VERSION "created by canmatrix"

NS_ :

BS_:

BU_: RadarFrontCenter DASy MPC3

BO_ 3221225472 VECTOR__INDEPENDENT_SIG_MSG: 0 Vector__XXX
 SG_ New_Signal_4448 : 0|8@1+ (1,0) [0|0] "" Vector__XXX

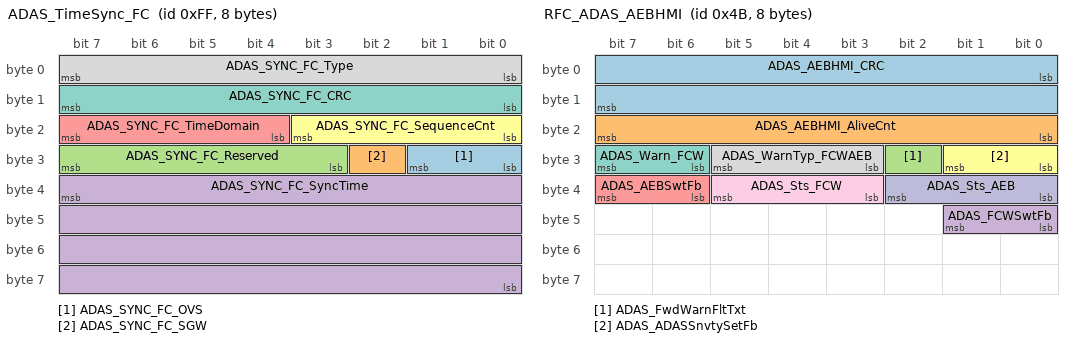
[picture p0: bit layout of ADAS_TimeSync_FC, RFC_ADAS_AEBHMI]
BO_ 255 ADAS_TimeSync_FC: 8 DASy
 SG_ ADAS_SYNC_FC_OVS : 24|2@1+ (1,0) [0|3] ""  MPC3,RadarFrontCenter
 SG_ ADAS_SYNC_FC_SGW : 26|1@1+ (1,0) [0|1] ""  MPC3,RadarFrontCenter
 SG_ ADAS_SYNC_FC_Reserved : 27|5@1+ (1,0) [0|31] ""  MPC3,RadarFrontCenter
 SG_ ADAS_SYNC_FC_SyncTime : 39|32@0+ (1,0) [0|4294967295] ""  MPC3,RadarFrontCenter
 SG_ ADAS_SYNC_FC_TimeDomain : 20|4@1+ (1,0) [0|15] ""  MPC3,RadarFrontCenter
 SG_ ADAS_SYNC_FC_SequenceCnt : 16|4@1+ (1,0) [0|15] ""  MPC3,RadarFrontCenter
 SG_ ADAS_SYNC_FC_CRC : 8|8@1+ (1,0) [0|0] ""  MPC3,RadarFrontCenter
 SG_ ADAS_SYNC_FC_Type : 0|8@1+ (1,0) [0|255] ""  MPC3,RadarFrontCenter

BO_ 75 RFC_ADAS_AEBHMI: 8 RadarFrontCenter
 SG_ ADAS_AEBHMI_CRC : 0|16@1+ (1,0) [0|65535] ""  DASy
 SG_ ADAS_AEBHMI_AliveCnt : 16|8@1+ (1,0) [0|255] ""  DASy
 SG_ ADAS_FwdWarnFltTxt : 26|1@1+ (1,0) [0|1] ""  DASy
 SG_ ADAS_FCWSwtFb : 40|2@1+ (1,0) [0|3] ""  DASy
 SG_ ADAS_AEBSwtFb : 38|2@1+ (1,0) [0|3] ""  DASy
 SG_ ADAS_ADASSnvtySetFb : 24|2@1+ (1,0) [0|3] ""  DASy
 SG_ ADAS_Warn_FCW : 30|2@1+ (1,0) [0|3] ""  DASy
 SG_ ADAS_WarnTyp_FCWAEB : 27|3@1+ (1,0) [0|7] ""  DASy
 SG_ ADAS_Sts_FCW : 35|3@1+ (1,0) [0|7] ""  DASy
 SG_ ADAS_Sts_AEB : 32|3@1+ (1,0) [0|7] ""  DASy

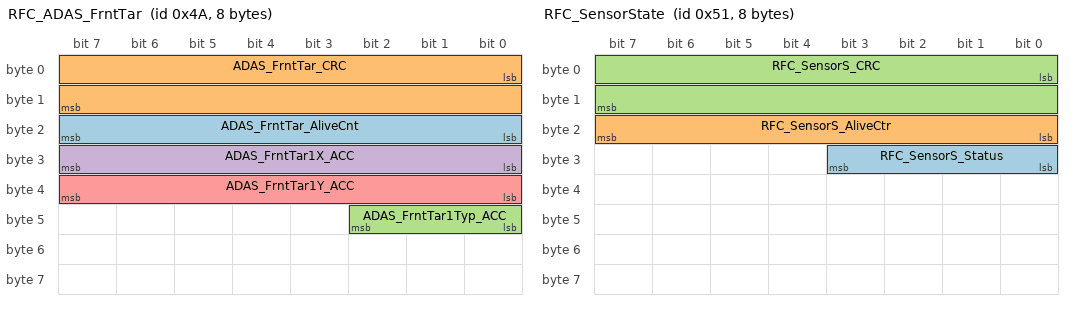
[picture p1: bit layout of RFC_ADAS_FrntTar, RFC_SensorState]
BO_ 74 RFC_ADAS_FrntTar: 8 RadarFrontCenter
 SG_ ADAS_FrntTar_AliveCnt : 16|8@1+ (1,0) [0|255] ""  DASy
 SG_ ADAS_FrntTar_CRC : 0|16@1+ (1,0) [0|65535] ""  DASy
 SG_ ADAS_FrntTar1Typ_ACC : 40|3@1+ (1,0) [0|7] ""  DASy
 SG_ ADAS_FrntTar1X_ACC : 24|8@1+ (1,0) [0|255] ""  DASy
 SG_ ADAS_FrntTar1Y_ACC : 32|8@1+ (0.1,-12.7) [-12.7|12.8] ""  DASy

BO_ 81 RFC_SensorState: 8 RadarFrontCenter
 SG_ RFC_SensorS_Status : 24|4@1+ (1,0) [0|15] ""  DASy
 SG_ RFC_SensorS_AliveCtr : 16|8@1+ (1,0) [0|255] ""  DASy
 SG_ RFC_SensorS_CRC : 0|16@1+ (1,0) [0|65535] ""  DASy

BO_ 2281601536 Dev_Video_SyncVisor_TX: 8 MPC3
 SG_ ImgTimeDelay : 32|32@1+ (1,0) [0|4294967295] ""  RadarFrontCenter,DASy
 SG_ ImgFrameCounter : 0|32@1+ (1,0) [0|4294967295] ""  DASy,RadarFrontCenter

BO_ 931 VFC_MapInfo: 16 MPC3
 SG_ VFC_MapInfo_CountryCode : 118|10@1+ (1,0) [0|1023] ""  RadarFrontCenter,DASy
 SG_ VFC_MapInfo_CurrentLane : 52|3@1+ (1,0) [0|7] ""  RadarFrontCenter,DASy
 SG_ VFC_MapInfo_RoadCurv : 104|12@1+ (2E-005,-0.04094) [-0.04094|0.04096] "1/m"  RadarFrontCenter,DASy
 SG_ VFC_MapInfo_BuildUp_Dx : 88|10@1+ (1,0) [0|1023] "m"  RadarFrontCenter,DASy
 SG_ VFC_MapInfo_BuildUp : 98|2@1+ (1,0) [0|3] ""  RadarFrontCenter,DASy
 SG_ VFC_MapInfo_Bridge_Dx : 72|10@1+ (1,0) [0|1023] "m"  RadarFrontCenter,DASy
 SG_ VFC_MapInfo_Bridge : 82|2@1+ (1,0) [0|3] ""  RadarFrontCenter,DASy
 SG_ VFC_MapInfo_Tunnel : 66|2@1+ (1,0) [0|3] ""  RadarFrontCenter,DASy
 SG_ VFC_MapInfo_Tunnel_Dx : 56|10@1+ (1,0) [0|1023] "m"  RadarFrontCenter,DASy
 SG_ VFC_MapInfo_TollGate : 50|2@1+ (1,0) [0|3] ""  RadarFrontCenter,DASy
 SG_ VFC_MapInfo_TollGate_Dx : 40|10@1+ (1,0) [0|1023] "m"  RadarFrontCenter,DASy
 SG_ VFC_MapInfo_DiRoad_Offset200 : 38|2@1+ (1,0) [0|3] ""  RadarFrontCenter,DASy
 SG_ VFC_MapInfo_LaneNum_Offset200 : 35|3@1+ (1,0) [0|7] ""  RadarFrontCenter,DASy
 SG_ VFC_MapInfo_LaneNum_Offset0 : 32|3@1+ (1,0) [0|7] ""  RadarFrontCenter,DASy
 SG_ VFC_MapInfo_DiRoad_Offset0 : 30|2@1+ (1,0) [0|3] ""  RadarFrontCenter,DASy
 SG_ VFC_MapInfo_RoadClass_Offset200 : 27|3@1+ (1,0) [0|7] ""  RadarFrontCenter,DASy
 SG_ VFC_MapInfo_RoadClass_Offset0 : 24|3@1+ (1,0) [0|7] ""  RadarFrontCenter,DASy
 SG_ VFC_MapInfo_AliveCtr : 16|8@1+ (1,0) [0|255] ""  RadarFrontCenter,DASy
 SG_ VFC_MapInfo_CRC : 0|16@1+ (1,0) [0|65535] ""  RadarFrontCenter,DASy

BO_ 80 VFC_SensorState: 12 MPC3
 SG_ VFC_SensorState_Status : 40|3@1+ (1,0) [0|7] ""  RadarFrontCenter,DASy
 SG_ VFC_SensorState_Report : 64|6@1+ (1,0) [0|63] ""  RadarFrontCenter,DASy
 SG_ VFC_SensorState_VisionFault : 32|3@1+ (1,0) [0|7] ""  RadarFrontCenter,DASy
 SG_ VFC_SensorState_VisionDTCs : 35|3@1+ (1,0) [0|7] ""  RadarFrontCenter,DASy
 SG_ VFC_SensorState_ProtocolVersion : 48|16@1+ (1,0) [0|65535] ""  RadarFrontCenter,DASy
 SG_ VFC_SensorState_BlindnessProb : 24|6@1+ (2,0) [0|100] "%"  RadarFrontCenter,DASy
 SG_ VFC_SensorState_AliveCtr : 16|8@1+ (1,0) [0|255] ""  RadarFrontCenter,DASy
 SG_ VFC_SensorState_CRC : 0|16@1+ (1,0) [0|65535] ""  RadarFrontCenter,DASy

BO_ 160 VFC_ObjectHdr: 32 MPC3
 SG_ VFC_ObjHdr_TimeStampStatus : 248|8@1+ (1,0) [0|255] ""  DASy,RadarFrontCenter
 SG_ VFC_ObjHdr_AUTOSARTStamp : 222|26@1+ (1,0) [0|67108863] "ms"  DASy,RadarFrontCenter
 SG_ VFC_ObjHdr_CycleTime : 208|10@1+ (0.001,0) [0|1] "s"  RadarFrontCenter,DASy
 SG_ VFC_ObjHdr_MountPosZ : 192|11@1+ (0.001,0) [0|2] "m"  RadarFrontCenter,DASy
 SG_ VFC_ObjHdr_MountPosY : 176|12@1+ (0.001,-2) [-2|2] "m"  RadarFrontCenter,DASy
 SG_ VFC_ObjHdr_MountPosX : 160|13@1+ (0.001,-4) [-4|4] "m"  RadarFrontCenter,DASy
 SG_ VFC_ObjHdr_CalibYawStdDev : 144|9@1+ (0.0005,0) [0|0.25] "rad"  RadarFrontCenter,DASy
 SG_ VFC_ObjHdr_CalibYawAngle : 128|10@1+ (0.0005,-0.2) [-0.2|0.2] "rad"  RadarFrontCenter,DASy
 SG_ VFC_ObjHdr_CalibRollStdDev : 112|9@1+ (0.0005,0) [0|0.25] "rad"  RadarFrontCenter,DASy
 SG_ VFC_ObjHdr_CalibRollAngle : 96|10@1+ (0.0005,-0.2) [-0.2|0.2] "rad"  RadarFrontCenter,DASy
 SG_ VFC_ObjHdr_FreeViewProb : 74|6@1+ (2,0) [0|100] "%"  RadarFrontCenter,DASy
 SG_ VFC_ObjHdr_CalibPitchStdDev : 80|9@1+ (0.0005,0) [0|0.25] "rad"  RadarFrontCenter,DASy
 SG_ VFC_ObjHdr_CalibState : 173|3@1+ (1,0) [0|7] ""  RadarFrontCenter,DASy
 SG_ VFC_ObjHdr_CalibPitchAngle : 64|10@1+ (0.0005,-0.2) [-0.2|0.2] "rad"  RadarFrontCenter,DASy
 SG_ VFC_ObjHdr_FrameNo : 28|4@1+ (1,0) [0|15] ""  RadarFrontCenter,DASy
 SG_ VFC_ObjHdr_CRC : 0|16@1+ (1,0) [0|65535] ""  RadarFrontCenter,DASy
 SG_ VFC_ObjHdr_AliveCtr : 16|8@1+ (1,0) [0|255] ""  RadarFrontCenter,DASy
 SG_ VFC_ObjHdr_BlockCtr : 24|4@1+ (1,0) [0|15] ""  RadarFrontCenter,DASy
 SG_ VFC_ObjHdr_TimeStamp : 32|26@1+ (1,0) [0|67108863] "ms"  RadarFrontCenter,DASy
 SG_ VFC_ObjHdr_Blindness : 58|6@1+ (2,0) [0|100] "%"  RadarFrontCenter,DASy
 SG_ VFC_ObjHdr_ObjCount : 89|7@1+ (1,0) [0|127] ""  RadarFrontCenter,DASy

BO_ 176 VFC_Object00A: 64 MPC3
 SG_ VFC_Obj00A_CRC : 0|16@1+ (1,0) [0|65535] ""  RadarFrontCenter,DASy
 SG_ VFC_Obj00A_AliveCtr : 16|8@1+ (1,0) [0|255] ""  RadarFrontCenter,DASy
 SG_ VFC_Obj00A_BlockCtr : 24|4@1+ (1,0) [0|15] ""  RadarFrontCenter,DASy
 SG_ VFC_Obj00A_ProtOrderIndex : 32|6@1+ (1,0) [0|63] ""  RadarFrontCenter,DASy
 SG_ VFC_Obj00A_Ax : 39|9@1+ (0.1,-16) [-16|16] "m/s^2"  RadarFrontCenter,DASy
 SG_ VFC_Obj00A_Vx : 48|12@1+ (0.1,-154) [-154|50] "m/s"  RadarFrontCenter,DASy
 SG_ VFC_Obj00A_Dx : 60|12@1+ (0.05,0) [0|204.7] "m"  RadarFrontCenter,DASy
 SG_ VFC_Obj00A_Dy : 72|14@1+ (0.01,-80) [-80|80] "m"  RadarFrontCenter,DASy
 SG_ VFC_Obj00A_Vy : 86|10@1+ (0.1,-50) [-50|50] "m/s"  RadarFrontCenter,DASy
 SG_ VFC_Obj00A_Ay : 96|8@1+ (0.1,-12) [-12|12] "m/s^2"  RadarFrontCenter,DASy
 SG_ VFC_Obj00A_DyStdDev : 104|10@1+ (0.02,0) [0|20] "m"  RadarFrontCenter,DASy
 SG_ VFC_Obj00A_DxStdDev : 118|10@1+ (0.05,0) [0|50] "m"  RadarFrontCenter,DASy
 SG_ VFC_Obj00A_VxStdDev : 128|10@1+ (0.1,0) [0|100] "m/s"  RadarFrontCenter,DASy
 SG_ VFC_Obj00A_ExistProb : 138|6@1+ (2,0) [0|100] "%"  RadarFrontCenter,DASy
 SG_ VFC_Obj00A_VyStdDev : 144|9@1+ (0.1,0) [0|50] "m/s"  RadarFrontCenter,DASy
 SG_ VFC_Obj00A_TypeProb : 154|6@1+ (2,0) [0|100] "%"  RadarFrontCenter,DASy
 SG_ VFC_Obj00A_AxStdDev : 160|8@1+ (0.1,0) [0|25] "m/s^2"  RadarFrontCenter,DASy
 SG_ VFC_Obj00A_AyStdDev : 168|8@1+ (0.1,0) [0|25] "m/s^2"  RadarFrontCenter,DASy
 SG_ VFC_Obj00A_PhiLeft : 176|13@1+ (0.00025,-1) [-1|1] ""  RadarFrontCenter,DASy
 SG_ VFC_Obj00A_ClassifiedView : 189|3@1+ (1,0) [0|7] ""  RadarFrontCenter,DASy
 SG_ VFC_Obj00A_Length : 192|9@1+ (0.05,0) [0|25.5] "m"  RadarFrontCenter,DASy
 SG_ VFC_Obj00A_WidthStdDev : 201|7@1+ (0.01,0) [0|1] "m"  RadarFrontCenter,DASy
 SG_ VFC_Obj00A_Height : 208|9@1+ (0.01,0) [0|5.11] "m"  RadarFrontCenter,DASy
 SG_ VFC_Obj00A_HeightStdDev : 217|7@1+ (0.01,0) [0|1] "m"  RadarFrontCenter,DASy
 SG_ VFC_Obj00A_PhiLeftStdDev : 224|8@1+ (0.0002,0) [0|0.05] ""  RadarFrontCenter,DASy
 SG_ VFC_Obj00A_HeadingStdDev : 232|6@1+ (0.01,0) [0|0.5] "rad"  RadarFrontCenter,DASy
 SG_ VFC_Obj00A_Measured : 238|2@1+ (1,0) [0|3] ""  RadarFrontCenter,DASy
 SG_ VFC_Obj00A_Heading : 240|9@1+ (0.01,-1.57) [-1.57|1.57] "rad"  RadarFrontCenter,DASy
 SG_ VFC_Obj00A_LengthStdDev : 249|7@1+ (0.05,0) [0|5] "m"  RadarFrontCenter,DASy
 SG_ VFC_Obj00A_PhiMid : 256|13@1+ (0.00025,-1) [-1|1] ""  RadarFrontCenter,DASy
 SG_ VFC_Obj00A_Width : 269|11@1+ (0.01,0) [0|12] "m"  RadarFrontCenter,DASy
 SG_ VFC_Obj00A_PhiMidStdDev : 280|8@1+ (0.0002,0) [0|0.05] ""  RadarFrontCenter,DASy
 SG_ VFC_Obj00A_PhiRight : 288|13@1+ (0.00025,-1) [-1|1] ""  RadarFrontCenter,DASy
 SG_ VFC_Obj00A_VisibleView : 301|3@1+ (1,0) [0|4] ""  RadarFrontCenter,DASy
 SG_ VFC_Obj00A_PhiRightStdDev : 304|8@1+ (0.0002,0) [0|0.05] ""  RadarFrontCenter,DASy
 SG_ VFC_Obj00A_PhiLeftVel : 312|13@1+ (0.001,-4) [-4|4] "1/s"  RadarFrontCenter,DASy
 SG_ VFC_Obj00A_PhiRightVel : 328|13@1+ (0.001,-4) [-4|4] "1/s"  RadarFrontCenter,DASy
 SG_ VFC_Obj00A_PhiRightVelStdDev : 344|8@1+ (0.001,0) [0|0.25] "1/s"  RadarFrontCenter,DASy
 SG_ VFC_Obj00A_PhiLeftVelStdDev : 352|8@1+ (0.001,0) [0|0.25] "1/s"  RadarFrontCenter,DASy
 SG_ VFC_Obj00A_PhiTop : 360|12@1+ (0.00025,-0.4) [-0.4|0.4] ""  RadarFrontCenter,DASy
 SG_ VFC_Obj00A_PhiBottom : 372|12@1+ (0.00025,-0.4) [-0.4|0.4] ""  RadarFrontCenter,DASy
 SG_ VFC_Obj00A_PhiTopStdDev : 384|8@1+ (0.0002,0) [0|0.05] ""  RadarFrontCenter,DASy
 SG_ VFC_Obj00A_HeadOrientation : 392|4@1+ (1,0) [0|15] ""  RadarFrontCenter,DASy
 SG_ VFC_Obj00A_Type : 396|4@1+ (1,0) [0|15] ""  RadarFrontCenter,DASy
 SG_ VFC_Obj00A_PhiBottomStdDev : 400|8@1+ (0.0002,0) [0|0.05] ""  RadarFrontCenter,DASy
 SG_ VFC_Obj00A_NormVx : 408|16@1+ (0.001,-40) [-40|25] "1/s"  RadarFrontCenter,DASy
 SG_ VFC_Obj00A_NormAx : 424|13@1+ (0.002,-10) [-10|6] "1/s^2"  RadarFrontCenter,DASy
 SG_ VFC_Obj00A_NormAxStdDev : 440|10@1+ (0.0025,0) [0|2.5] "1/s^2"  RadarFrontCenter,DASy
 SG_ VFC_Obj00A_ProbMovingLat : 450|6@1+ (2,0) [0|100] "%"  RadarFrontCenter,DASy
 SG_ VFC_Obj00A_ID : 456|8@1+ (1,0) [0|254] ""  RadarFrontCenter,DASy
 SG_ VFC_Obj00A_NormVxStdDev : 464|10@1+ (0.001,0) [0|1] "1/s"  RadarFrontCenter,DASy
 SG_ VFC_Obj00A_ProbMovingLong : 474|6@1+ (2,0) [0|100] "%"  RadarFrontCenter,DASy

BO_ 177 VFC_Object00B: 16 MPC3
 SG_ VFC_Obj00B_TTIPC_StdDev : 120|7@1+ (0.0625,0) [0|7.875] ""  RadarFrontCenter,DASy
 SG_ VFC_Obj00B_TTIPC : 104|11@1+ (0.008,-8) [-8|8] ""  RadarFrontCenter,DASy
 SG_ VFC_Obj00B_AngLongitude : 88|10@1+ (0.005,-2.5) [-2.5|2.5] "rad/s"  RadarFrontCenter,DASy
 SG_ VFC_Obj00B_CRC : 0|16@1+ (1,0) [0|65535] ""  RadarFrontCenter,DASy
 SG_ VFC_Obj00B_AliveCtr : 16|8@1+ (1,0) [0|255] ""  RadarFrontCenter,DASy
 SG_ VFC_Obj00B_BlockCtr : 24|4@1+ (1,0) [0|15] ""  RadarFrontCenter,DASy
 SG_ VFC_Obj00B_ScaleChange : 32|14@1+ (0.0001,0.5) [0.5|2.1] ""  RadarFrontCenter,DASy
 SG_ VFC_Obj00B_ScaleChngStdDev : 48|10@1+ (0.0001,0) [0|0.1] ""  RadarFrontCenter,DASy
 SG_ VFC_Obj00B_LineEdgeRightEgo : 58|1@1+ (1,0) [0|1] ""  RadarFrontCenter,DASy
 SG_ VFC_Obj00B_LineEdgeLeftEgo : 59|1@1+ (1,0) [0|1] ""  RadarFrontCenter,DASy
 SG_ VFC_Obj00B_CompletelyInImg : 60|1@1+ (1,0) [0|1] ""  RadarFrontCenter,DASy
 SG_ VFC_Obj00B_DirIndicator : 61|3@1+ (1,0) [0|7] ""  RadarFrontCenter,DASy
 SG_ VFC_Obj00B_LineEdgeAngle : 64|13@1+ (0.00025,-1) [-1|1] "rad"  RadarFrontCenter,DASy
 SG_ VFC_Obj00B_BrakeLight : 77|3@1+ (1,0) [0|7] ""  RadarFrontCenter,DASy
 SG_ VFC_Obj00B_MeasSource : 80|5@1+ (1,0) [0|31] ""  RadarFrontCenter,DASy
 SG_ VFC_Obj00B_Reliab : 98|6@1+ (1,0) [0|63] ""  RadarFrontCenter,DASy

BO_ 178 VFC_Object01A: 64 MPC3
 SG_ VFC_Obj01A_CRC : 0|16@1+ (1,0) [0|65535] ""  RadarFrontCenter,DASy
 SG_ VFC_Obj01A_AliveCtr : 16|8@1+ (1,0) [0|255] ""  RadarFrontCenter,DASy
 SG_ VFC_Obj01A_BlockCtr : 24|4@1+ (1,0) [0|15] ""  RadarFrontCenter,DASy
 SG_ VFC_Obj01A_ProtOrderIndex : 32|6@1+ (1,0) [0|63] ""  RadarFrontCenter,DASy
 SG_ VFC_Obj01A_Ax : 39|9@1+ (0.1,-16) [-16|16] "m/s^2"  RadarFrontCenter,DASy
 SG_ VFC_Obj01A_Vx : 48|12@1+ (0.1,-154) [-154|50] "m/s"  RadarFrontCenter,DASy
 SG_ VFC_Obj01A_Dx : 60|12@1+ (0.05,0) [0|204.7] "m"  RadarFrontCenter,DASy
 SG_ VFC_Obj01A_Dy : 72|14@1+ (0.01,-80) [-80|80] "m"  RadarFrontCenter,DASy
 SG_ VFC_Obj01A_Vy : 86|10@1+ (0.1,-50) [-50|50] "m/s"  RadarFrontCenter,DASy
 SG_ VFC_Obj01A_Ay : 96|8@1+ (0.1,-12) [-12|12] "m/s^2"  RadarFrontCenter,DASy
 SG_ VFC_Obj01A_DyStdDev : 104|10@1+ (0.02,0) [0|20] "m"  RadarFrontCenter,DASy
 SG_ VFC_Obj01A_DxStdDev : 118|10@1+ (0.05,0) [0|50] "m"  RadarFrontCenter,DASy
 SG_ VFC_Obj01A_VxStdDev : 128|10@1+ (0.1,0) [0|100] "m/s"  RadarFrontCenter,DASy
 SG_ VFC_Obj01A_ExistProb : 138|6@1+ (2,0) [0|100] "%"  RadarFrontCenter,DASy
 SG_ VFC_Obj01A_VyStdDev : 144|9@1+ (0.1,0) [0|50] "m/s"  RadarFrontCenter,DASy
 SG_ VFC_Obj01A_TypeProb : 154|6@1+ (2,0) [0|100] "%"  RadarFrontCenter,DASy
 SG_ VFC_Obj01A_AxStdDev : 160|8@1+ (0.1,0) [0|25] "m/s^2"  RadarFrontCenter,DASy
 SG_ VFC_Obj01A_AyStdDev : 168|8@1+ (0.1,0) [0|25] "m/s^2"  RadarFrontCenter,DASy
 SG_ VFC_Obj01A_PhiLeft : 176|13@1+ (0.00025,-1) [-1|1] ""  RadarFrontCenter,DASy
 SG_ VFC_Obj01A_ClassifiedView : 189|3@1+ (1,0) [0|7] ""  RadarFrontCenter,DASy
 SG_ VFC_Obj01A_Length : 192|9@1+ (0.05,0) [0|25.5] "m"  RadarFrontCenter,DASy
 SG_ VFC_Obj01A_WidthStdDev : 201|7@1+ (0.01,0) [0|1] "m"  RadarFrontCenter,DASy
 SG_ VFC_Obj01A_Height : 208|9@1+ (0.01,0) [0|5.11] "m"  RadarFrontCenter,DASy
 SG_ VFC_Obj01A_HeightStdDev : 217|7@1+ (0.01,0) [0|1] "m"  RadarFrontCenter,DASy
 SG_ VFC_Obj01A_PhiLeftStdDev : 224|8@1+ (0.0002,0) [0|0.05] ""  RadarFrontCenter,DASy
 SG_ VFC_Obj01A_HeadingStdDev : 232|6@1+ (0.01,0) [0|0.5] "rad"  RadarFrontCenter,DASy
 SG_ VFC_Obj01A_Measured : 238|2@1+ (1,0) [0|3] ""  RadarFrontCenter,DASy
 SG_ VFC_Obj01A_Heading : 240|9@1+ (0.01,-1.57) [-1.57|1.57] "rad"  RadarFrontCenter,DASy
 SG_ VFC_Obj01A_LengthStdDev : 249|7@1+ (0.05,0) [0|5] "m"  RadarFrontCenter,DASy
 SG_ VFC_Obj01A_PhiMid : 256|13@1+ (0.00025,-1) [-1|1] ""  RadarFrontCenter,DASy
 SG_ VFC_Obj01A_Width : 269|11@1+ (0.01,0) [0|12] "m"  RadarFrontCenter,DASy
 SG_ VFC_Obj01A_PhiMidStdDev : 280|8@1+ (0.0002,0) [0|0.05] ""  RadarFrontCenter,DASy
 SG_ VFC_Obj01A_PhiRight : 288|13@1+ (0.00025,-1) [-1|1] ""  RadarFrontCenter,DASy
 SG_ VFC_Obj01A_VisibleView : 301|3@1+ (1,0) [0|4] ""  RadarFrontCenter,DASy
 SG_ VFC_Obj01A_PhiRightStdDev : 304|8@1+ (0.0002,0) [0|0.05] ""  RadarFrontCenter,DASy
 SG_ VFC_Obj01A_PhiLeftVel : 312|13@1+ (0.001,-4) [-4|4] "1/s"  RadarFrontCenter,DASy
 SG_ VFC_Obj01A_PhiRightVel : 328|13@1+ (0.001,-4) [-4|4] "1/s"  RadarFrontCenter,DASy
 SG_ VFC_Obj01A_PhiRightVelStdDev : 344|8@1+ (0.001,0) [0|0.25] "1/s"  RadarFrontCenter,DASy
 SG_ VFC_Obj01A_PhiLeftVelStdDev : 352|8@1+ (0.001,0) [0|0.25] "1/s"  RadarFrontCenter,DASy
 SG_ VFC_Obj01A_PhiTop : 360|12@1+ (0.00025,-0.4) [-0.4|0.4] ""  RadarFrontCenter,DASy
 SG_ VFC_Obj01A_PhiBottom : 372|12@1+ (0.00025,-0.4) [-0.4|0.4] ""  RadarFrontCenter,DASy
 SG_ VFC_Obj01A_PhiTopStdDev : 384|8@1+ (0.0002,0) [0|0.05] ""  RadarFrontCenter,DASy
 SG_ VFC_Obj01A_HeadOrientation : 392|4@1+ (1,0) [0|10] ""  RadarFrontCenter,DASy
 SG_ VFC_Obj01A_Type : 396|4@1+ (1,0) [0|15] ""  RadarFrontCenter,DASy
 SG_ VFC_Obj01A_PhiBottomStdDev : 400|8@1+ (0.0002,0) [0|0.05] ""  RadarFrontCenter,DASy
 SG_ VFC_Obj01A_NormVx : 408|16@1+ (0.001,-40) [-40|25] "1/s"  RadarFrontCenter,DASy
 SG_ VFC_Obj01A_NormAx : 424|13@1+ (0.002,-10) [-10|6] "1/s^2"  RadarFrontCenter,DASy
 SG_ VFC_Obj01A_NormAxStdDev : 440|10@1+ (0.0025,0) [0|2.5] "1/s^2"  RadarFrontCenter,DASy
 SG_ VFC_Obj01A_ProbMovingLat : 450|6@1+ (2,0) [0|100] "%"  RadarFrontCenter,DASy
 SG_ VFC_Obj01A_ID : 456|8@1+ (1,0) [0|254] ""  RadarFrontCenter,DASy
 SG_ VFC_Obj01A_NormVxStdDev : 464|10@1+ (0.001,0) [0|1] "1/s"  RadarFrontCenter,DASy
 SG_ VFC_Obj01A_ProbMovingLong : 474|6@1+ (2,0) [0|100] "%"  RadarFrontCenter,DASy

BO_ 179 VFC_Object01B: 16 MPC3
 SG_ VFC_Obj01B_TTIPC_StdDev : 120|7@1+ (0.0625,0) [0|7.875] ""  RadarFrontCenter,DASy
 SG_ VFC_Obj01B_TTIPC : 104|11@1+ (0.008,-8) [-8|8] ""  RadarFrontCenter,DASy
 SG_ VFC_Obj01B_AngLongitude : 88|10@1+ (0.005,-2.5) [-2.5|2.5] "rad/s"  RadarFrontCenter,DASy
 SG_ VFC_Obj01B_CRC : 0|16@1+ (1,0) [0|65535] ""  RadarFrontCenter,DASy
 SG_ VFC_Obj01B_AliveCtr : 16|8@1+ (1,0) [0|255] ""  RadarFrontCenter,DASy
 SG_ VFC_Obj01B_BlockCtr : 24|4@1+ (1,0) [0|15] ""  RadarFrontCenter,DASy
 SG_ VFC_Obj01B_ScaleChange : 32|14@1+ (0.0001,0.5) [0.5|2.1] ""  RadarFrontCenter,DASy
 SG_ VFC_Obj01B_ScaleChngStdDev : 48|10@1+ (0.0001,0) [0|0.1] ""  RadarFrontCenter,DASy
 SG_ VFC_Obj01B_LineEdgeRightEgo : 58|1@1+ (1,0) [0|1] ""  RadarFrontCenter,DASy
 SG_ VFC_Obj01B_LineEdgeLeftEgo : 59|1@1+ (1,0) [0|1] ""  RadarFrontCenter,DASy
 SG_ VFC_Obj01B_CompletelyInImg : 60|1@1+ (1,0) [0|1] ""  RadarFrontCenter,DASy
 SG_ VFC_Obj01B_DirIndicator : 61|3@1+ (1,0) [0|7] ""  RadarFrontCenter,DASy
 SG_ VFC_Obj01B_LineEdgeAngle : 64|13@1+ (0.00025,-1) [-1|1] "rad"  RadarFrontCenter,DASy
 SG_ VFC_Obj01B_BrakeLight : 77|3@1+ (1,0) [0|7] ""  RadarFrontCenter,DASy
 SG_ VFC_Obj01B_MeasSource : 80|5@1+ (1,0) [0|31] ""  RadarFrontCenter,DASy
 SG_ VFC_Obj01B_Reliab : 98|6@1+ (1,0) [0|63] ""  RadarFrontCenter,DASy

BO_ 180 VFC_Object02A: 64 MPC3
 SG_ VFC_Obj02A_CRC : 0|16@1+ (1,0) [0|65535] ""  RadarFrontCenter,DASy
 SG_ VFC_Obj02A_AliveCtr : 16|8@1+ (1,0) [0|255] ""  RadarFrontCenter,DASy
 SG_ VFC_Obj02A_BlockCtr : 24|4@1+ (1,0) [0|15] ""  RadarFrontCenter,DASy
 SG_ VFC_Obj02A_ProtOrderIndex : 32|6@1+ (1,0) [0|63] ""  RadarFrontCenter,DASy
 SG_ VFC_Obj02A_Ax : 39|9@1+ (0.1,-16) [-16|16] "m/s^2"  RadarFrontCenter,DASy
 SG_ VFC_Obj02A_Vx : 48|12@1+ (0.1,-154) [-154|50] "m/s"  RadarFrontCenter,DASy
 SG_ VFC_Obj02A_Dx : 60|12@1+ (0.05,0) [0|204.7] "m"  RadarFrontCenter,DASy
 SG_ VFC_Obj02A_Dy : 72|14@1+ (0.01,-80) [-80|80] "m"  RadarFrontCenter,DASy
 SG_ VFC_Obj02A_Vy : 86|10@1+ (0.1,-50) [-50|50] "m/s"  RadarFrontCenter,DASy
 SG_ VFC_Obj02A_Ay : 96|8@1+ (0.1,-12) [-12|12] "m/s^2"  RadarFrontCenter,DASy
 SG_ VFC_Obj02A_DyStdDev : 104|10@1+ (0.02,0) [0|20] "m"  RadarFrontCenter,DASy
 SG_ VFC_Obj02A_DxStdDev : 118|10@1+ (0.05,0) [0|50] "m"  RadarFrontCenter,DASy
 SG_ VFC_Obj02A_VxStdDev : 128|10@1+ (0.1,0) [0|100] "m/s"  RadarFrontCenter,DASy
 SG_ VFC_Obj02A_ExistProb : 138|6@1+ (2,0) [0|100] "%"  RadarFrontCenter,DASy
 SG_ VFC_Obj02A_VyStdDev : 144|9@1+ (0.1,0) [0|50] "m/s"  RadarFrontCenter,DASy
 SG_ VFC_Obj02A_TypeProb : 154|6@1+ (2,0) [0|100] "%"  RadarFrontCenter,DASy
 SG_ VFC_Obj02A_AxStdDev : 160|8@1+ (0.1,0) [0|25] "m/s^2"  RadarFrontCenter,DASy
 SG_ VFC_Obj02A_AyStdDev : 168|8@1+ (0.1,0) [0|25] "m/s^2"  RadarFrontCenter,DASy
 SG_ VFC_Obj02A_PhiLeft : 176|13@1+ (0.00025,-1) [-1|1] ""  RadarFrontCenter,DASy
 SG_ VFC_Obj02A_ClassifiedView : 189|3@1+ (1,0) [0|7] ""  RadarFrontCenter,DASy
 SG_ VFC_Obj02A_Length : 192|9@1+ (0.05,0) [0|25.5] "m"  RadarFrontCenter,DASy
 SG_ VFC_Obj02A_WidthStdDev : 201|7@1+ (0.01,0) [0|1] "m"  RadarFrontCenter,DASy
 SG_ VFC_Obj02A_Height : 208|9@1+ (0.01,0) [0|5.11] "m"  RadarFrontCenter,DASy
 SG_ VFC_Obj02A_HeightStdDev : 217|7@1+ (0.01,0) [0|1] "m"  RadarFrontCenter,DASy
 SG_ VFC_Obj02A_PhiLeftStdDev : 224|8@1+ (0.0002,0) [0|0.05] ""  RadarFrontCenter,DASy
 SG_ VFC_Obj02A_HeadingStdDev : 232|6@1+ (0.01,0) [0|0.5] "rad"  RadarFrontCenter,DASy
 SG_ VFC_Obj02A_Measured : 238|2@1+ (1,0) [0|3] ""  RadarFrontCenter,DASy
 SG_ VFC_Obj02A_Heading : 240|9@1+ (0.01,-1.57) [-1.57|1.57] "rad"  RadarFrontCenter,DASy
 SG_ VFC_Obj02A_LengthStdDev : 249|7@1+ (0.05,0) [0|5] "m"  RadarFrontCenter,DASy
 SG_ VFC_Obj02A_PhiMid : 256|13@1+ (0.00025,-1) [-1|1] ""  RadarFrontCenter,DASy
 SG_ VFC_Obj02A_Width : 269|11@1+ (0.01,0) [0|12] "m"  RadarFrontCenter,DASy
 SG_ VFC_Obj02A_PhiMidStdDev : 280|8@1+ (0.0002,0) [0|0.05] ""  RadarFrontCenter,DASy
 SG_ VFC_Obj02A_PhiRight : 288|13@1+ (0.00025,-1) [-1|1] ""  RadarFrontCenter,DASy
 SG_ VFC_Obj02A_VisibleView : 301|3@1+ (1,0) [0|4] ""  RadarFrontCenter,DASy
 SG_ VFC_Obj02A_PhiRightStdDev : 304|8@1+ (0.0002,0) [0|0.05] ""  RadarFrontCenter,DASy
 SG_ VFC_Obj02A_PhiLeftVel : 312|13@1+ (0.001,-4) [-4|4] "1/s"  RadarFrontCenter,DASy
 SG_ VFC_Obj02A_PhiRightVel : 328|13@1+ (0.001,-4) [-4|4] "1/s"  RadarFrontCenter,DASy
 SG_ VFC_Obj02A_PhiRightVelStdDev : 344|8@1+ (0.001,0) [0|0.25] "1/s"  RadarFrontCenter,DASy
 SG_ VFC_Obj02A_PhiLeftVelStdDev : 352|8@1+ (0.001,0) [0|0.25] "1/s"  RadarFrontCenter,DASy
 SG_ VFC_Obj02A_PhiTop : 360|12@1+ (0.00025,-0.4) [-0.4|0.4] ""  RadarFrontCenter,DASy
 SG_ VFC_Obj02A_PhiBottom : 372|12@1+ (0.00025,-0.4) [-0.4|0.4] ""  RadarFrontCenter,DASy
 SG_ VFC_Obj02A_PhiTopStdDev : 384|8@1+ (0.0002,0) [0|0.05] ""  RadarFrontCenter,DASy
 SG_ VFC_Obj02A_HeadOrientation : 392|4@1+ (1,0) [0|10] ""  RadarFrontCenter,DASy
 SG_ VFC_Obj02A_Type : 396|4@1+ (1,0) [0|15] ""  RadarFrontCenter,DASy
 SG_ VFC_Obj02A_PhiBottomStdDev : 400|8@1+ (0.0002,0) [0|0.05] ""  RadarFrontCenter,DASy
 SG_ VFC_Obj02A_NormVx : 408|16@1+ (0.001,-40) [-40|25] "1/s"  RadarFrontCenter,DASy
 SG_ VFC_Obj02A_NormAx : 424|13@1+ (0.002,-10) [-10|6] "1/s^2"  RadarFrontCenter,DASy
 SG_ VFC_Obj02A_NormAxStdDev : 440|10@1+ (0.0025,0) [0|2.5] "1/s^2"  RadarFrontCenter,DASy
 SG_ VFC_Obj02A_ProbMovingLat : 450|6@1+ (2,0) [0|100] "%"  RadarFrontCenter,DASy
 SG_ VFC_Obj02A_ID : 456|8@1+ (1,0) [0|254] ""  RadarFrontCenter,DASy
 SG_ VFC_Obj02A_NormVxStdDev : 464|10@1+ (0.001,0) [0|1] "1/s"  RadarFrontCenter,DASy
 SG_ VFC_Obj02A_ProbMovingLong : 474|6@1+ (2,0) [0|100] "%"  RadarFrontCenter,DASy

BO_ 181 VFC_Object02B: 16 MPC3
 SG_ VFC_Obj02B_TTIPC_StdDev : 120|7@1+ (0.0625,0) [0|7.875] ""  RadarFrontCenter,DASy
 SG_ VFC_Obj02B_TTIPC : 104|11@1+ (0.008,-8) [-8|8] ""  RadarFrontCenter,DASy
 SG_ VFC_Obj02B_AngLongitude : 88|10@1+ (0.005,-2.5) [-2.5|2.5] "rad/s"  RadarFrontCenter,DASy
 SG_ VFC_Obj02B_CRC : 0|16@1+ (1,0) [0|65535] ""  RadarFrontCenter,DASy
 SG_ VFC_Obj02B_AliveCtr : 16|8@1+ (1,0) [0|255] ""  RadarFrontCenter,DASy
 SG_ VFC_Obj02B_BlockCtr : 24|4@1+ (1,0) [0|15] ""  RadarFrontCenter,DASy
 SG_ VFC_Obj02B_ScaleChange : 32|14@1+ (0.0001,0.5) [0.5|2.1] ""  RadarFrontCenter,DASy
 SG_ VFC_Obj02B_ScaleChngStdDev : 48|10@1+ (0.0001,0) [0|0.1] ""  RadarFrontCenter,DASy
 SG_ VFC_Obj02B_LineEdgeRightEgo : 58|1@1+ (1,0) [0|1] ""  RadarFrontCenter,DASy
 SG_ VFC_Obj02B_LineEdgeLeftEgo : 59|1@1+ (1,0) [0|1] ""  RadarFrontCenter,DASy
 SG_ VFC_Obj02B_CompletelyInImg : 60|1@1+ (1,0) [0|1] ""  RadarFrontCenter,DASy
 SG_ VFC_Obj02B_DirIndicator : 61|3@1+ (1,0) [0|7] ""  RadarFrontCenter,DASy
 SG_ VFC_Obj02B_LineEdgeAngle : 64|13@1+ (0.00025,-1) [-1|1] "rad"  RadarFrontCenter,DASy
 SG_ VFC_Obj02B_BrakeLight : 77|3@1+ (1,0) [0|7] ""  RadarFrontCenter,DASy
 SG_ VFC_Obj02B_MeasSource : 80|5@1+ (1,0) [0|31] ""  RadarFrontCenter,DASy
 SG_ VFC_Obj02B_Reliab : 98|6@1+ (1,0) [0|63] ""  RadarFrontCenter,DASy

BO_ 182 VFC_Object03A: 64 MPC3
 SG_ VFC_Obj03A_CRC : 0|16@1+ (1,0) [0|65535] ""  RadarFrontCenter,DASy
 SG_ VFC_Obj03A_AliveCtr : 16|8@1+ (1,0) [0|255] ""  RadarFrontCenter,DASy
 SG_ VFC_Obj03A_BlockCtr : 24|4@1+ (1,0) [0|15] ""  RadarFrontCenter,DASy
 SG_ VFC_Obj03A_ProtOrderIndex : 32|6@1+ (1,0) [0|63] ""  RadarFrontCenter,DASy
 SG_ VFC_Obj03A_Ax : 39|9@1+ (0.1,-16) [-16|16] "m/s^2"  RadarFrontCenter,DASy
 SG_ VFC_Obj03A_Vx : 48|12@1+ (0.1,-154) [-154|50] "m/s"  RadarFrontCenter,DASy
 SG_ VFC_Obj03A_Dx : 60|12@1+ (0.05,0) [0|204.7] "m"  RadarFrontCenter,DASy
 SG_ VFC_Obj03A_Dy : 72|14@1+ (0.01,-80) [-80|80] "m"  RadarFrontCenter,DASy
 SG_ VFC_Obj03A_Vy : 86|10@1+ (0.1,-50) [-50|50] "m/s"  RadarFrontCenter,DASy
 SG_ VFC_Obj03A_Ay : 96|8@1+ (0.1,-12) [-12|12] "m/s^2"  RadarFrontCenter,DASy
 SG_ VFC_Obj03A_DyStdDev : 104|10@1+ (0.02,0) [0|20] "m"  RadarFrontCenter,DASy
 SG_ VFC_Obj03A_DxStdDev : 118|10@1+ (0.05,0) [0|50] "m"  RadarFrontCenter,DASy
 SG_ VFC_Obj03A_VxStdDev : 128|10@1+ (0.1,0) [0|100] "m/s"  RadarFrontCenter,DASy
 SG_ VFC_Obj03A_ExistProb : 138|6@1+ (2,0) [0|100] "%"  RadarFrontCenter,DASy
 SG_ VFC_Obj03A_VyStdDev : 144|9@1+ (0.1,0) [0|50] "m/s"  RadarFrontCenter,DASy
 SG_ VFC_Obj03A_TypeProb : 154|6@1+ (2,0) [0|100] "%"  RadarFrontCenter,DASy
 SG_ VFC_Obj03A_AxStdDev : 160|8@1+ (0.1,0) [0|25] "m/s^2"  RadarFrontCenter,DASy
 SG_ VFC_Obj03A_AyStdDev : 168|8@1+ (0.1,0) [0|25] "m/s^2"  RadarFrontCenter,DASy
 SG_ VFC_Obj03A_PhiLeft : 176|13@1+ (0.00025,-1) [-1|1] ""  RadarFrontCenter,DASy
 SG_ VFC_Obj03A_ClassifiedView : 189|3@1+ (1,0) [0|7] ""  RadarFrontCenter,DASy
 SG_ VFC_Obj03A_Length : 192|9@1+ (0.05,0) [0|25.5] "m"  RadarFrontCenter,DASy
 SG_ VFC_Obj03A_WidthStdDev : 201|7@1+ (0.01,0) [0|1] "m"  RadarFrontCenter,DASy
 SG_ VFC_Obj03A_Height : 208|9@1+ (0.01,0) [0|5.11] "m"  RadarFrontCenter,DASy
 SG_ VFC_Obj03A_HeightStdDev : 217|7@1+ (0.01,0) [0|1] "m"  RadarFrontCenter,DASy
 SG_ VFC_Obj03A_PhiLeftStdDev : 224|8@1+ (0.0002,0) [0|0.05] ""  RadarFrontCenter,DASy
 SG_ VFC_Obj03A_HeadingStdDev : 232|6@1+ (0.01,0) [0|0.5] "rad"  RadarFrontCenter,DASy
 SG_ VFC_Obj03A_Measured : 238|2@1+ (1,0) [0|3] ""  RadarFrontCenter,DASy
 SG_ VFC_Obj03A_Heading : 240|9@1+ (0.01,-1.57) [-1.57|1.57] "rad"  RadarFrontCenter,DASy
 SG_ VFC_Obj03A_LengthStdDev : 249|7@1+ (0.05,0) [0|5] "m"  RadarFrontCenter,DASy
 SG_ VFC_Obj03A_PhiMid : 256|13@1+ (0.00025,-1) [-1|1] ""  RadarFrontCenter,DASy
 SG_ VFC_Obj03A_Width : 269|11@1+ (0.01,0) [0|12] "m"  RadarFrontCenter,DASy
 SG_ VFC_Obj03A_PhiMidStdDev : 280|8@1+ (0.0002,0) [0|0.05] ""  RadarFrontCenter,DASy
 SG_ VFC_Obj03A_PhiRight : 288|13@1+ (0.00025,-1) [-1|1] ""  RadarFrontCenter,DASy
 SG_ VFC_Obj03A_VisibleView : 301|3@1+ (1,0) [0|4] ""  RadarFrontCenter,DASy
 SG_ VFC_Obj03A_PhiRightStdDev : 304|8@1+ (0.0002,0) [0|0.05] ""  RadarFrontCenter,DASy
 SG_ VFC_Obj03A_PhiLeftVel : 312|13@1+ (0.001,-4) [-4|4] "1/s"  RadarFrontCenter,DASy
 SG_ VFC_Obj03A_PhiRightVel : 328|13@1+ (0.001,-4) [-4|4] "1/s"  RadarFrontCenter,DASy
 SG_ VFC_Obj03A_PhiRightVelStdDev : 344|8@1+ (0.001,0) [0|0.25] "1/s"  RadarFrontCenter,DASy
 SG_ VFC_Obj03A_PhiLeftVelStdDev : 352|8@1+ (0.001,0) [0|0.25] "1/s"  RadarFrontCenter,DASy
 SG_ VFC_Obj03A_PhiTop : 360|12@1+ (0.00025,-0.4) [-0.4|0.4] ""  RadarFrontCenter,DASy
 SG_ VFC_Obj03A_PhiBottom : 372|12@1+ (0.00025,-0.4) [-0.4|0.4] ""  RadarFrontCenter,DASy
 SG_ VFC_Obj03A_PhiTopStdDev : 384|8@1+ (0.0002,0) [0|0.05] ""  RadarFrontCenter,DASy
 SG_ VFC_Obj03A_HeadOrientation : 392|4@1+ (1,0) [0|10] ""  RadarFrontCenter,DASy
 SG_ VFC_Obj03A_Type : 396|4@1+ (1,0) [0|15] ""  RadarFrontCenter,DASy
 SG_ VFC_Obj03A_PhiBottomStdDev : 400|8@1+ (0.0002,0) [0|0.05] ""  RadarFrontCenter,DASy
 SG_ VFC_Obj03A_NormVx : 408|16@1+ (0.001,-40) [-40|25] "1/s"  RadarFrontCenter,DASy
 SG_ VFC_Obj03A_NormAx : 424|13@1+ (0.002,-10) [-10|6] "1/s^2"  RadarFrontCenter,DASy
 SG_ VFC_Obj03A_NormAxStdDev : 440|10@1+ (0.0025,0) [0|2.5] "1/s^2"  RadarFrontCenter,DASy
 SG_ VFC_Obj03A_ProbMovingLat : 450|6@1+ (2,0) [0|100] "%"  RadarFrontCenter,DASy
 SG_ VFC_Obj03A_ID : 456|8@1+ (1,0) [0|254] ""  RadarFrontCenter,DASy
 SG_ VFC_Obj03A_NormVxStdDev : 464|10@1+ (0.001,0) [0|1] "1/s"  RadarFrontCenter,DASy
 SG_ VFC_Obj03A_ProbMovingLong : 474|6@1+ (2,0) [0|100] "%"  RadarFrontCenter,DASy

BO_ 183 VFC_Object03B: 16 MPC3
 SG_ VFC_Obj03B_TTIPC_StdDev : 120|7@1+ (0.0625,0) [0|7.875] ""  RadarFrontCenter,DASy
 SG_ VFC_Obj03B_TTIPC : 104|11@1+ (0.008,-8) [-8|8] ""  RadarFrontCenter,DASy
 SG_ VFC_Obj03B_AngLongitude : 88|10@1+ (0.005,-2.5) [-2.5|2.5] "rad/s"  RadarFrontCenter,DASy
 SG_ VFC_Obj03B_CRC : 0|16@1+ (1,0) [0|65535] ""  RadarFrontCenter,DASy
 SG_ VFC_Obj03B_AliveCtr : 16|8@1+ (1,0) [0|255] ""  RadarFrontCenter,DASy
 SG_ VFC_Obj03B_BlockCtr : 24|4@1+ (1,0) [0|15] ""  RadarFrontCenter,DASy
 SG_ VFC_Obj03B_ScaleChange : 32|14@1+ (0.0001,0.5) [0.5|2.1] ""  RadarFrontCenter,DASy
 SG_ VFC_Obj03B_ScaleChngStdDev : 48|10@1+ (0.0001,0) [0|0.1] ""  RadarFrontCenter,DASy
 SG_ VFC_Obj03B_LineEdgeRightEgo : 58|1@1+ (1,0) [0|1] ""  RadarFrontCenter,DASy
 SG_ VFC_Obj03B_LineEdgeLeftEgo : 59|1@1+ (1,0) [0|1] ""  RadarFrontCenter,DASy
 SG_ VFC_Obj03B_CompletelyInImg : 60|1@1+ (1,0) [0|1] ""  RadarFrontCenter,DASy
 SG_ VFC_Obj03B_DirIndicator : 61|3@1+ (1,0) [0|7] ""  RadarFrontCenter,DASy
 SG_ VFC_Obj03B_LineEdgeAngle : 64|13@1+ (0.00025,-1) [-1|1] "rad"  RadarFrontCenter,DASy
 SG_ VFC_Obj03B_BrakeLight : 77|3@1+ (1,0) [0|7] ""  RadarFrontCenter,DASy
 SG_ VFC_Obj03B_MeasSource : 80|5@1+ (1,0) [0|31] ""  RadarFrontCenter,DASy
 SG_ VFC_Obj03B_Reliab : 98|6@1+ (1,0) [0|63] ""  RadarFrontCenter,DASy

BO_ 184 VFC_Object04A: 64 MPC3
 SG_ VFC_Obj04A_CRC : 0|16@1+ (1,0) [0|65535] ""  RadarFrontCenter,DASy
 SG_ VFC_Obj04A_AliveCtr : 16|8@1+ (1,0) [0|255] ""  RadarFrontCenter,DASy
 SG_ VFC_Obj04A_BlockCtr : 24|4@1+ (1,0) [0|15] ""  RadarFrontCenter,DASy
 SG_ VFC_Obj04A_ProtOrderIndex : 32|6@1+ (1,0) [0|63] ""  RadarFrontCenter,DASy
 SG_ VFC_Obj04A_Ax : 39|9@1+ (0.1,-16) [-16|16] "m/s^2"  RadarFrontCenter,DASy
 SG_ VFC_Obj04A_Vx : 48|12@1+ (0.1,-154) [-154|50] "m/s"  RadarFrontCenter,DASy
 SG_ VFC_Obj04A_Dx : 60|12@1+ (0.05,0) [0|204.7] "m"  RadarFrontCenter,DASy
 SG_ VFC_Obj04A_Dy : 72|14@1+ (0.01,-80) [-80|80] "m"  RadarFrontCenter,DASy
 SG_ VFC_Obj04A_Vy : 86|10@1+ (0.1,-50) [-50|50] "m/s"  RadarFrontCenter,DASy
 SG_ VFC_Obj04A_Ay : 96|8@1+ (0.1,-12) [-12|12] "m/s^2"  RadarFrontCenter,DASy
 SG_ VFC_Obj04A_DyStdDev : 104|10@1+ (0.02,0) [0|20] "m"  RadarFrontCenter,DASy
 SG_ VFC_Obj04A_DxStdDev : 118|10@1+ (0.05,0) [0|50] "m"  RadarFrontCenter,DASy
 SG_ VFC_Obj04A_VxStdDev : 128|10@1+ (0.1,0) [0|100] "m/s"  RadarFrontCenter,DASy
 SG_ VFC_Obj04A_ExistProb : 138|6@1+ (2,0) [0|100] "%"  RadarFrontCenter,DASy
 SG_ VFC_Obj04A_VyStdDev : 144|9@1+ (0.1,0) [0|50] "m/s"  RadarFrontCenter,DASy
 SG_ VFC_Obj04A_TypeProb : 154|6@1+ (2,0) [0|100] "%"  RadarFrontCenter,DASy
 SG_ VFC_Obj04A_AxStdDev : 160|8@1+ (0.1,0) [0|25] "m/s^2"  RadarFrontCenter,DASy
 SG_ VFC_Obj04A_AyStdDev : 168|8@1+ (0.1,0) [0|25] "m/s^2"  RadarFrontCenter,DASy
 SG_ VFC_Obj04A_PhiLeft : 176|13@1+ (0.00025,-1) [-1|1] ""  RadarFrontCenter,DASy
 SG_ VFC_Obj04A_ClassifiedView : 189|3@1+ (1,0) [0|7] ""  RadarFrontCenter,DASy
 SG_ VFC_Obj04A_Length : 192|9@1+ (0.05,0) [0|25.5] "m"  RadarFrontCenter,DASy
 SG_ VFC_Obj04A_WidthStdDev : 201|7@1+ (0.01,0) [0|1] "m"  RadarFrontCenter,DASy
 SG_ VFC_Obj04A_Height : 208|9@1+ (0.01,0) [0|5.11] "m"  RadarFrontCenter,DASy
 SG_ VFC_Obj04A_HeightStdDev : 217|7@1+ (0.01,0) [0|1] "m"  RadarFrontCenter,DASy
 SG_ VFC_Obj04A_PhiLeftStdDev : 224|8@1+ (0.0002,0) [0|0.05] ""  RadarFrontCenter,DASy
 SG_ VFC_Obj04A_HeadingStdDev : 232|6@1+ (0.01,0) [0|0.5] "rad"  RadarFrontCenter,DASy
 SG_ VFC_Obj04A_Measured : 238|2@1+ (1,0) [0|3] ""  RadarFrontCenter,DASy
 SG_ VFC_Obj04A_Heading : 240|9@1+ (0.01,-1.57) [-1.57|1.57] "rad"  RadarFrontCenter,DASy
 SG_ VFC_Obj04A_LengthStdDev : 249|7@1+ (0.05,0) [0|5] "m"  RadarFrontCenter,DASy
 SG_ VFC_Obj04A_PhiMid : 256|13@1+ (0.00025,-1) [-1|1] ""  RadarFrontCenter,DASy
 SG_ VFC_Obj04A_Width : 269|11@1+ (0.01,0) [0|12] "m"  RadarFrontCenter,DASy
 SG_ VFC_Obj04A_PhiMidStdDev : 280|8@1+ (0.0002,0) [0|0.05] ""  RadarFrontCenter,DASy
 SG_ VFC_Obj04A_PhiRight : 288|13@1+ (0.00025,-1) [-1|1] ""  RadarFrontCenter,DASy
 SG_ VFC_Obj04A_VisibleView : 301|3@1+ (1,0) [0|4] ""  RadarFrontCenter,DASy
 SG_ VFC_Obj04A_PhiRightStdDev : 304|8@1+ (0.0002,0) [0|0.05] ""  RadarFrontCenter,DASy
 SG_ VFC_Obj04A_PhiLeftVel : 312|13@1+ (0.001,-4) [-4|4] "1/s"  RadarFrontCenter,DASy
 SG_ VFC_Obj04A_PhiRightVel : 328|13@1+ (0.001,-4) [-4|4] "1/s"  RadarFrontCenter,DASy
 SG_ VFC_Obj04A_PhiRightVelStdDev : 344|8@1+ (0.001,0) [0|0.25] "1/s"  RadarFrontCenter,DASy
 SG_ VFC_Obj04A_PhiLeftVelStdDev : 352|8@1+ (0.001,0) [0|0.25] "1/s"  RadarFrontCenter,DASy
 SG_ VFC_Obj04A_PhiTop : 360|12@1+ (0.00025,-0.4) [-0.4|0.4] ""  RadarFrontCenter,DASy
 SG_ VFC_Obj04A_PhiBottom : 372|12@1+ (0.00025,-0.4) [-0.4|0.4] ""  RadarFrontCenter,DASy
 SG_ VFC_Obj04A_PhiTopStdDev : 384|8@1+ (0.0002,0) [0|0.05] ""  RadarFrontCenter,DASy
 SG_ VFC_Obj04A_HeadOrientation : 392|4@1+ (1,0) [0|10] ""  RadarFrontCenter,DASy
 SG_ VFC_Obj04A_Type : 396|4@1+ (1,0) [0|15] ""  RadarFrontCenter,DASy
 SG_ VFC_Obj04A_PhiBottomStdDev : 400|8@1+ (0.0002,0) [0|0.05] ""  RadarFrontCenter,DASy
 SG_ VFC_Obj04A_NormVx : 408|16@1+ (0.001,-40) [-40|25] "1/s"  RadarFrontCenter,DASy
 SG_ VFC_Obj04A_NormAx : 424|13@1+ (0.002,-10) [-10|6] "1/s^2"  RadarFrontCenter,DASy
 SG_ VFC_Obj04A_NormAxStdDev : 440|10@1+ (0.0025,0) [0|2.5] "1/s^2"  RadarFrontCenter,DASy
 SG_ VFC_Obj04A_ProbMovingLat : 450|6@1+ (2,0) [0|100] "%"  RadarFrontCenter,DASy
 SG_ VFC_Obj04A_ID : 456|8@1+ (1,0) [0|254] ""  RadarFrontCenter,DASy
 SG_ VFC_Obj04A_NormVxStdDev : 464|10@1+ (0.001,0) [0|1] "1/s"  RadarFrontCenter,DASy
 SG_ VFC_Obj04A_ProbMovingLong : 474|6@1+ (2,0) [0|100] "%"  RadarFrontCenter,DASy

BO_ 185 VFC_Object04B: 16 MPC3
 SG_ VFC_Obj04B_TTIPC_StdDev : 120|7@1+ (0.0625,0) [0|7.875] ""  RadarFrontCenter,DASy
 SG_ VFC_Obj04B_TTIPC : 104|11@1+ (0.008,-8) [-8|8] ""  RadarFrontCenter,DASy
 SG_ VFC_Obj04B_AngLongitude : 88|10@1+ (0.005,-2.5) [-2.5|2.5] "rad/s"  RadarFrontCenter,DASy
 SG_ VFC_Obj04B_CRC : 0|16@1+ (1,0) [0|65535] ""  RadarFrontCenter,DASy
 SG_ VFC_Obj04B_AliveCtr : 16|8@1+ (1,0) [0|255] ""  RadarFrontCenter,DASy
 SG_ VFC_Obj04B_BlockCtr : 24|4@1+ (1,0) [0|15] ""  RadarFrontCenter,DASy
 SG_ VFC_Obj04B_ScaleChange : 32|14@1+ (0.0001,0.5) [0.5|2.1] ""  RadarFrontCenter,DASy
 SG_ VFC_Obj04B_ScaleChngStdDev : 48|10@1+ (0.0001,0) [0|0.1] ""  RadarFrontCenter,DASy
 SG_ VFC_Obj04B_LineEdgeRightEgo : 58|1@1+ (1,0) [0|1] ""  RadarFrontCenter,DASy
 SG_ VFC_Obj04B_LineEdgeLeftEgo : 59|1@1+ (1,0) [0|1] ""  RadarFrontCenter,DASy
 SG_ VFC_Obj04B_CompletelyInImg : 60|1@1+ (1,0) [0|1] ""  RadarFrontCenter,DASy
 SG_ VFC_Obj04B_DirIndicator : 61|3@1+ (1,0) [0|7] ""  RadarFrontCenter,DASy
 SG_ VFC_Obj04B_LineEdgeAngle : 64|13@1+ (0.00025,-1) [-1|1] "rad"  RadarFrontCenter,DASy
 SG_ VFC_Obj04B_BrakeLight : 77|3@1+ (1,0) [0|7] ""  RadarFrontCenter,DASy
 SG_ VFC_Obj04B_MeasSource : 80|5@1+ (1,0) [0|31] ""  RadarFrontCenter,DASy
 SG_ VFC_Obj04B_Reliab : 98|6@1+ (1,0) [0|63] ""  RadarFrontCenter,DASy

BO_ 186 VFC_Object05A: 64 MPC3
 SG_ VFC_Obj05A_CRC : 0|16@1+ (1,0) [0|65535] ""  RadarFrontCenter,DASy
 SG_ VFC_Obj05A_AliveCtr : 16|8@1+ (1,0) [0|255] ""  RadarFrontCenter,DASy
 SG_ VFC_Obj05A_BlockCtr : 24|4@1+ (1,0) [0|15] ""  RadarFrontCenter,DASy
 SG_ VFC_Obj05A_ProtOrderIndex : 32|6@1+ (1,0) [0|63] ""  RadarFrontCenter,DASy
 SG_ VFC_Obj05A_Ax : 39|9@1+ (0.1,-16) [-16|16] "m/s^2"  RadarFrontCenter,DASy
 SG_ VFC_Obj05A_Vx : 48|12@1+ (0.1,-154) [-154|50] "m/s"  RadarFrontCenter,DASy
 SG_ VFC_Obj05A_Dx : 60|12@1+ (0.05,0) [0|204.7] "m"  RadarFrontCenter,DASy
 SG_ VFC_Obj05A_Dy : 72|14@1+ (0.01,-80) [-80|80] "m"  RadarFrontCenter,DASy
 SG_ VFC_Obj05A_Vy : 86|10@1+ (0.1,-50) [-50|50] "m/s"  RadarFrontCenter,DASy
 SG_ VFC_Obj05A_Ay : 96|8@1+ (0.1,-12) [-12|12] "m/s^2"  RadarFrontCenter,DASy
 SG_ VFC_Obj05A_DyStdDev : 104|10@1+ (0.02,0) [0|20] "m"  RadarFrontCenter,DASy
 SG_ VFC_Obj05A_DxStdDev : 118|10@1+ (0.05,0) [0|50] "m"  RadarFrontCenter,DASy
 SG_ VFC_Obj05A_VxStdDev : 128|10@1+ (0.1,0) [0|100] "m/s"  RadarFrontCenter,DASy
 SG_ VFC_Obj05A_ExistProb : 138|6@1+ (2,0) [0|100] "%"  RadarFrontCenter,DASy
 SG_ VFC_Obj05A_VyStdDev : 144|9@1+ (0.1,0) [0|50] "m/s"  RadarFrontCenter,DASy
 SG_ VFC_Obj05A_TypeProb : 154|6@1+ (2,0) [0|100] "%"  RadarFrontCenter,DASy
 SG_ VFC_Obj05A_AxStdDev : 160|8@1+ (0.1,0) [0|25] "m/s^2"  RadarFrontCenter,DASy
 SG_ VFC_Obj05A_AyStdDev : 168|8@1+ (0.1,0) [0|25] "m/s^2"  RadarFrontCenter,DASy
 SG_ VFC_Obj05A_PhiLeft : 176|13@1+ (0.00025,-1) [-1|1] ""  RadarFrontCenter,DASy
 SG_ VFC_Obj05A_ClassifiedView : 189|3@1+ (1,0) [0|7] ""  RadarFrontCenter,DASy
 SG_ VFC_Obj05A_Length : 192|9@1+ (0.05,0) [0|25.5] "m"  RadarFrontCenter,DASy
 SG_ VFC_Obj05A_WidthStdDev : 201|7@1+ (0.01,0) [0|1] "m"  RadarFrontCenter,DASy
 SG_ VFC_Obj05A_Height : 208|9@1+ (0.01,0) [0|5.11] "m"  RadarFrontCenter,DASy
 SG_ VFC_Obj05A_HeightStdDev : 217|7@1+ (0.01,0) [0|1] "m"  RadarFrontCenter,DASy
 SG_ VFC_Obj05A_PhiLeftStdDev : 224|8@1+ (0.0002,0) [0|0.05] ""  RadarFrontCenter,DASy
 SG_ VFC_Obj05A_HeadingStdDev : 232|6@1+ (0.01,0) [0|0.5] "rad"  RadarFrontCenter,DASy
 SG_ VFC_Obj05A_Measured : 238|2@1+ (1,0) [0|3] ""  RadarFrontCenter,DASy
 SG_ VFC_Obj05A_Heading : 240|9@1+ (0.01,-1.57) [-1.57|1.57] "rad"  RadarFrontCenter,DASy
 SG_ VFC_Obj05A_LengthStdDev : 249|7@1+ (0.05,0) [0|5] "m"  RadarFrontCenter,DASy
 SG_ VFC_Obj05A_PhiMid : 256|13@1+ (0.00025,-1) [-1|1] ""  RadarFrontCenter,DASy
 SG_ VFC_Obj05A_Width : 269|11@1+ (0.01,0) [0|12] "m"  RadarFrontCenter,DASy
 SG_ VFC_Obj05A_PhiMidStdDev : 280|8@1+ (0.0002,0) [0|0.05] ""  RadarFrontCenter,DASy
 SG_ VFC_Obj05A_PhiRight : 288|13@1+ (0.00025,-1) [-1|1] ""  RadarFrontCenter,DASy
 SG_ VFC_Obj05A_VisibleView : 301|3@1+ (1,0) [0|4] ""  RadarFrontCenter,DASy
 SG_ VFC_Obj05A_PhiRightStdDev : 304|8@1+ (0.0002,0) [0|0.05] ""  RadarFrontCenter,DASy
 SG_ VFC_Obj05A_PhiLeftVel : 312|13@1+ (0.001,-4) [-4|4] "1/s"  RadarFrontCenter,DASy
 SG_ VFC_Obj05A_PhiRightVel : 328|13@1+ (0.001,-4) [-4|4] "1/s"  RadarFrontCenter,DASy
 SG_ VFC_Obj05A_PhiRightVelStdDev : 344|8@1+ (0.001,0) [0|0.25] "1/s"  RadarFrontCenter,DASy
 SG_ VFC_Obj05A_PhiLeftVelStdDev : 352|8@1+ (0.001,0) [0|0.25] "1/s"  RadarFrontCenter,DASy
 SG_ VFC_Obj05A_PhiTop : 360|12@1+ (0.00025,-0.4) [-0.4|0.4] ""  RadarFrontCenter,DASy
 SG_ VFC_Obj05A_PhiBottom : 372|12@1+ (0.00025,-0.4) [-0.4|0.4] ""  RadarFrontCenter,DASy
 SG_ VFC_Obj05A_PhiTopStdDev : 384|8@1+ (0.0002,0) [0|0.05] ""  RadarFrontCenter,DASy
 SG_ VFC_Obj05A_HeadOrientation : 392|4@1+ (1,0) [0|10] ""  RadarFrontCenter,DASy
 SG_ VFC_Obj05A_Type : 396|4@1+ (1,0) [0|15] ""  RadarFrontCenter,DASy
 SG_ VFC_Obj05A_PhiBottomStdDev : 400|8@1+ (0.0002,0) [0|0.05] ""  RadarFrontCenter,DASy
 SG_ VFC_Obj05A_NormVx : 408|16@1+ (0.001,-40) [-40|25] "1/s"  RadarFrontCenter,DASy
 SG_ VFC_Obj05A_NormAx : 424|13@1+ (0.002,-10) [-10|6] "1/s^2"  RadarFrontCenter,DASy
 SG_ VFC_Obj05A_NormAxStdDev : 440|10@1+ (0.0025,0) [0|2.5] "1/s^2"  RadarFrontCenter,DASy
 SG_ VFC_Obj05A_ProbMovingLat : 450|6@1+ (2,0) [0|100] "%"  RadarFrontCenter,DASy
 SG_ VFC_Obj05A_ID : 456|8@1+ (1,0) [0|254] ""  RadarFrontCenter,DASy
 SG_ VFC_Obj05A_NormVxStdDev : 464|10@1+ (0.001,0) [0|1] "1/s"  RadarFrontCenter,DASy
 SG_ VFC_Obj05A_ProbMovingLong : 474|6@1+ (2,0) [0|100] "%"  RadarFrontCenter,DASy

BO_ 187 VFC_Object05B: 16 MPC3
 SG_ VFC_Obj05B_TTIPC_StdDev : 120|7@1+ (0.0625,0) [0|7.875] ""  RadarFrontCenter,DASy
 SG_ VFC_Obj05B_TTIPC : 104|11@1+ (0.008,-8) [-8|8] ""  RadarFrontCenter,DASy
 SG_ VFC_Obj05B_AngLongitude : 88|10@1+ (0.005,-2.5) [-2.5|2.5] "rad/s"  RadarFrontCenter,DASy
 SG_ VFC_Obj05B_CRC : 0|16@1+ (1,0) [0|65535] ""  RadarFrontCenter,DASy
 SG_ VFC_Obj05B_AliveCtr : 16|8@1+ (1,0) [0|255] ""  RadarFrontCenter,DASy
 SG_ VFC_Obj05B_BlockCtr : 24|4@1+ (1,0) [0|15] ""  RadarFrontCenter,DASy
 SG_ VFC_Obj05B_ScaleChange : 32|14@1+ (0.0001,0.5) [0.5|2.1] ""  RadarFrontCenter,DASy
 SG_ VFC_Obj05B_ScaleChngStdDev : 48|10@1+ (0.0001,0) [0|0.1] ""  RadarFrontCenter,DASy
 SG_ VFC_Obj05B_LineEdgeRightEgo : 58|1@1+ (1,0) [0|1] ""  RadarFrontCenter,DASy
 SG_ VFC_Obj05B_LineEdgeLeftEgo : 59|1@1+ (1,0) [0|1] ""  RadarFrontCenter,DASy
 SG_ VFC_Obj05B_CompletelyInImg : 60|1@1+ (1,0) [0|1] ""  RadarFrontCenter,DASy
 SG_ VFC_Obj05B_DirIndicator : 61|3@1+ (1,0) [0|7] ""  RadarFrontCenter,DASy
 SG_ VFC_Obj05B_LineEdgeAngle : 64|13@1+ (0.00025,-1) [-1|1] "rad"  RadarFrontCenter,DASy
 SG_ VFC_Obj05B_BrakeLight : 77|3@1+ (1,0) [0|7] ""  RadarFrontCenter,DASy
 SG_ VFC_Obj05B_MeasSource : 80|5@1+ (1,0) [0|31] ""  RadarFrontCenter,DASy
 SG_ VFC_Obj05B_Reliab : 98|6@1+ (1,0) [0|63] ""  RadarFrontCenter,DASy

BO_ 188 VFC_Object06A: 64 MPC3
 SG_ VFC_Obj06A_CRC : 0|16@1+ (1,0) [0|65535] ""  RadarFrontCenter,DASy
 SG_ VFC_Obj06A_AliveCtr : 16|8@1+ (1,0) [0|255] ""  RadarFrontCenter,DASy
 SG_ VFC_Obj06A_BlockCtr : 24|4@1+ (1,0) [0|15] ""  RadarFrontCenter,DASy
 SG_ VFC_Obj06A_ProtOrderIndex : 32|6@1+ (1,0) [0|63] ""  RadarFrontCenter,DASy
 SG_ VFC_Obj06A_Ax : 39|9@1+ (0.1,-16) [-16|16] "m/s^2"  RadarFrontCenter,DASy
 SG_ VFC_Obj06A_Vx : 48|12@1+ (0.1,-154) [-154|50] "m/s"  RadarFrontCenter,DASy
 SG_ VFC_Obj06A_Dx : 60|12@1+ (0.05,0) [0|204.7] "m"  RadarFrontCenter,DASy
 SG_ VFC_Obj06A_Dy : 72|14@1+ (0.01,-80) [-80|80] "m"  RadarFrontCenter,DASy
 SG_ VFC_Obj06A_Vy : 86|10@1+ (0.1,-50) [-50|50] "m/s"  RadarFrontCenter,DASy
 SG_ VFC_Obj06A_Ay : 96|8@1+ (0.1,-12) [-12|12] "m/s^2"  RadarFrontCenter,DASy
 SG_ VFC_Obj06A_DyStdDev : 104|10@1+ (0.02,0) [0|20] "m"  RadarFrontCenter,DASy
 SG_ VFC_Obj06A_DxStdDev : 118|10@1+ (0.05,0) [0|50] "m"  RadarFrontCenter,DASy
 SG_ VFC_Obj06A_VxStdDev : 128|10@1+ (0.1,0) [0|100] "m/s"  RadarFrontCenter,DASy
 SG_ VFC_Obj06A_ExistProb : 138|6@1+ (2,0) [0|100] "%"  RadarFrontCenter,DASy
 SG_ VFC_Obj06A_VyStdDev : 144|9@1+ (0.1,0) [0|50] "m/s"  RadarFrontCenter,DASy
 SG_ VFC_Obj06A_TypeProb : 154|6@1+ (2,0) [0|100] "%"  RadarFrontCenter,DASy
 SG_ VFC_Obj06A_AxStdDev : 160|8@1+ (0.1,0) [0|25] "m/s^2"  RadarFrontCenter,DASy
 SG_ VFC_Obj06A_AyStdDev : 168|8@1+ (0.1,0) [0|25] "m/s^2"  RadarFrontCenter,DASy
 SG_ VFC_Obj06A_PhiLeft : 176|13@1+ (0.00025,-1) [-1|1] ""  RadarFrontCenter,DASy
 SG_ VFC_Obj06A_ClassifiedView : 189|3@1+ (1,0) [0|7] ""  RadarFrontCenter,DASy
 SG_ VFC_Obj06A_Length : 192|9@1+ (0.05,0) [0|25.5] "m"  RadarFrontCenter,DASy
 SG_ VFC_Obj06A_WidthStdDev : 201|7@1+ (0.01,0) [0|1] "m"  RadarFrontCenter,DASy
 SG_ VFC_Obj06A_Height : 208|9@1+ (0.01,0) [0|5.11] "m"  RadarFrontCenter,DASy
 SG_ VFC_Obj06A_HeightStdDev : 217|7@1+ (0.01,0) [0|1] "m"  RadarFrontCenter,DASy
 SG_ VFC_Obj06A_PhiLeftStdDev : 224|8@1+ (0.0002,0) [0|0.05] ""  RadarFrontCenter,DASy
 SG_ VFC_Obj06A_HeadingStdDev : 232|6@1+ (0.01,0) [0|0.5] "rad"  RadarFrontCenter,DASy
 SG_ VFC_Obj06A_Measured : 238|2@1+ (1,0) [0|3] ""  RadarFrontCenter,DASy
 SG_ VFC_Obj06A_Heading : 240|9@1+ (0.01,-1.57) [-1.57|1.57] "rad"  RadarFrontCenter,DASy
 SG_ VFC_Obj06A_LengthStdDev : 249|7@1+ (0.05,0) [0|5] "m"  RadarFrontCenter,DASy
 SG_ VFC_Obj06A_PhiMid : 256|13@1+ (0.00025,-1) [-1|1] ""  RadarFrontCenter,DASy
 SG_ VFC_Obj06A_Width : 269|11@1+ (0.01,0) [0|12] "m"  RadarFrontCenter,DASy
 SG_ VFC_Obj06A_PhiMidStdDev : 280|8@1+ (0.0002,0) [0|0.05] ""  RadarFrontCenter,DASy
 SG_ VFC_Obj06A_PhiRight : 288|13@1+ (0.00025,-1) [-1|1] ""  RadarFrontCenter,DASy
 SG_ VFC_Obj06A_VisibleView : 301|3@1+ (1,0) [0|4] ""  RadarFrontCenter,DASy
 SG_ VFC_Obj06A_PhiRightStdDev : 304|8@1+ (0.0002,0) [0|0.05] ""  RadarFrontCenter,DASy
 SG_ VFC_Obj06A_PhiLeftVel : 312|13@1+ (0.001,-4) [-4|4] "1/s"  RadarFrontCenter,DASy
 SG_ VFC_Obj06A_PhiRightVel : 328|13@1+ (0.001,-4) [-4|4] "1/s"  RadarFrontCenter,DASy
 SG_ VFC_Obj06A_PhiRightVelStdDev : 344|8@1+ (0.001,0) [0|0.25] "1/s"  RadarFrontCenter,DASy
 SG_ VFC_Obj06A_PhiLeftVelStdDev : 352|8@1+ (0.001,0) [0|0.25] "1/s"  RadarFrontCenter,DASy
 SG_ VFC_Obj06A_PhiTop : 360|12@1+ (0.00025,-0.4) [-0.4|0.4] ""  RadarFrontCenter,DASy
 SG_ VFC_Obj06A_PhiBottom : 372|12@1+ (0.00025,-0.4) [-0.4|0.4] ""  RadarFrontCenter,DASy
 SG_ VFC_Obj06A_PhiTopStdDev : 384|8@1+ (0.0002,0) [0|0.05] ""  RadarFrontCenter,DASy
 SG_ VFC_Obj06A_HeadOrientation : 392|4@1+ (1,0) [0|10] ""  RadarFrontCenter,DASy
 SG_ VFC_Obj06A_Type : 396|4@1+ (1,0) [0|15] ""  RadarFrontCenter,DASy
 SG_ VFC_Obj06A_PhiBottomStdDev : 400|8@1+ (0.0002,0) [0|0.05] ""  RadarFrontCenter,DASy
 SG_ VFC_Obj06A_NormVx : 408|16@1+ (0.001,-40) [-40|25] "1/s"  RadarFrontCenter,DASy
 SG_ VFC_Obj06A_NormAx : 424|13@1+ (0.002,-10) [-10|6] "1/s^2"  RadarFrontCenter,DASy
 SG_ VFC_Obj06A_NormAxStdDev : 440|10@1+ (0.0025,0) [0|2.5] "1/s^2"  RadarFrontCenter,DASy
 SG_ VFC_Obj06A_ProbMovingLat : 450|6@1+ (2,0) [0|100] "%"  RadarFrontCenter,DASy
 SG_ VFC_Obj06A_ID : 456|8@1+ (1,0) [0|254] ""  RadarFrontCenter,DASy
 SG_ VFC_Obj06A_NormVxStdDev : 464|10@1+ (0.001,0) [0|1] "1/s"  RadarFrontCenter,DASy
 SG_ VFC_Obj06A_ProbMovingLong : 474|6@1+ (2,0) [0|100] "%"  RadarFrontCenter,DASy

BO_ 189 VFC_Object06B: 16 MPC3
 SG_ VFC_Obj06B_TTIPC_StdDev : 120|7@1+ (0.0625,0) [0|7.875] ""  RadarFrontCenter,DASy
 SG_ VFC_Obj06B_TTIPC : 104|11@1+ (0.008,-8) [-8|8] ""  RadarFrontCenter,DASy
 SG_ VFC_Obj06B_AngLongitude : 88|10@1+ (0.005,-2.5) [-2.5|2.5] "rad/s"  RadarFrontCenter,DASy
 SG_ VFC_Obj06B_CRC : 0|16@1+ (1,0) [0|65535] ""  RadarFrontCenter,DASy
 SG_ VFC_Obj06B_AliveCtr : 16|8@1+ (1,0) [0|255] ""  RadarFrontCenter,DASy
 SG_ VFC_Obj06B_BlockCtr : 24|4@1+ (1,0) [0|15] ""  RadarFrontCenter,DASy
 SG_ VFC_Obj06B_ScaleChange : 32|14@1+ (0.0001,0.5) [0.5|2.1] ""  RadarFrontCenter,DASy
 SG_ VFC_Obj06B_ScaleChngStdDev : 48|10@1+ (0.0001,0) [0|0.1] ""  RadarFrontCenter,DASy
 SG_ VFC_Obj06B_LineEdgeRightEgo : 58|1@1+ (1,0) [0|1] ""  RadarFrontCenter,DASy
 SG_ VFC_Obj06B_LineEdgeLeftEgo : 59|1@1+ (1,0) [0|1] ""  RadarFrontCenter,DASy
 SG_ VFC_Obj06B_CompletelyInImg : 60|1@1+ (1,0) [0|1] ""  RadarFrontCenter,DASy
 SG_ VFC_Obj06B_DirIndicator : 61|3@1+ (1,0) [0|7] ""  RadarFrontCenter,DASy
 SG_ VFC_Obj06B_LineEdgeAngle : 64|13@1+ (0.00025,-1) [-1|1] "rad"  RadarFrontCenter,DASy
 SG_ VFC_Obj06B_BrakeLight : 77|3@1+ (1,0) [0|7] ""  RadarFrontCenter,DASy
 SG_ VFC_Obj06B_MeasSource : 80|5@1+ (1,0) [0|31] ""  RadarFrontCenter,DASy
 SG_ VFC_Obj06B_Reliab : 98|6@1+ (1,0) [0|63] ""  RadarFrontCenter,DASy

BO_ 190 VFC_Object07A: 64 MPC3
 SG_ VFC_Obj07A_CRC : 0|16@1+ (1,0) [0|65535] ""  RadarFrontCenter,DASy
 SG_ VFC_Obj07A_AliveCtr : 16|8@1+ (1,0) [0|255] ""  RadarFrontCenter,DASy
 SG_ VFC_Obj07A_BlockCtr : 24|4@1+ (1,0) [0|15] ""  RadarFrontCenter,DASy
 SG_ VFC_Obj07A_ProtOrderIndex : 32|6@1+ (1,0) [0|63] ""  RadarFrontCenter,DASy
 SG_ VFC_Obj07A_Ax : 39|9@1+ (0.1,-16) [-16|16] "m/s^2"  RadarFrontCenter,DASy
 SG_ VFC_Obj07A_Vx : 48|12@1+ (0.1,-154) [-154|50] "m/s"  RadarFrontCenter,DASy
 SG_ VFC_Obj07A_Dx : 60|12@1+ (0.05,0) [0|204.7] "m"  RadarFrontCenter,DASy
 SG_ VFC_Obj07A_Dy : 72|14@1+ (0.01,-80) [-80|80] "m"  RadarFrontCenter,DASy
 SG_ VFC_Obj07A_Vy : 86|10@1+ (0.1,-50) [-50|50] "m/s"  RadarFrontCenter,DASy
 SG_ VFC_Obj07A_Ay : 96|8@1+ (0.1,-12) [-12|12] "m/s^2"  RadarFrontCenter,DASy
 SG_ VFC_Obj07A_DyStdDev : 104|10@1+ (0.02,0) [0|20] "m"  RadarFrontCenter,DASy
 SG_ VFC_Obj07A_DxStdDev : 118|10@1+ (0.05,0) [0|50] "m"  RadarFrontCenter,DASy
 SG_ VFC_Obj07A_VxStdDev : 128|10@1+ (0.1,0) [0|100] "m/s"  RadarFrontCenter,DASy
 SG_ VFC_Obj07A_ExistProb : 138|6@1+ (2,0) [0|100] "%"  RadarFrontCenter,DASy
 SG_ VFC_Obj07A_VyStdDev : 144|9@1+ (0.1,0) [0|50] "m/s"  RadarFrontCenter,DASy
 SG_ VFC_Obj07A_TypeProb : 154|6@1+ (2,0) [0|100] "%"  RadarFrontCenter,DASy
 SG_ VFC_Obj07A_AxStdDev : 160|8@1+ (0.1,0) [0|25] "m/s^2"  RadarFrontCenter,DASy
 SG_ VFC_Obj07A_AyStdDev : 168|8@1+ (0.1,0) [0|25] "m/s^2"  RadarFrontCenter,DASy
 SG_ VFC_Obj07A_PhiLeft : 176|13@1+ (0.00025,-1) [-1|1] ""  RadarFrontCenter,DASy
 SG_ VFC_Obj07A_ClassifiedView : 189|3@1+ (1,0) [0|7] ""  RadarFrontCenter,DASy
 SG_ VFC_Obj07A_Length : 192|9@1+ (0.05,0) [0|25.5] "m"  RadarFrontCenter,DASy
 SG_ VFC_Obj07A_WidthStdDev : 201|7@1+ (0.01,0) [0|1] "m"  RadarFrontCenter,DASy
 SG_ VFC_Obj07A_Height : 208|9@1+ (0.01,0) [0|5.11] "m"  RadarFrontCenter,DASy
 SG_ VFC_Obj07A_HeightStdDev : 217|7@1+ (0.01,0) [0|1] "m"  RadarFrontCenter,DASy
 SG_ VFC_Obj07A_PhiLeftStdDev : 224|8@1+ (0.0002,0) [0|0.05] ""  RadarFrontCenter,DASy
 SG_ VFC_Obj07A_HeadingStdDev : 232|6@1+ (0.01,0) [0|0.5] "rad"  RadarFrontCenter,DASy
 SG_ VFC_Obj07A_Measured : 238|2@1+ (1,0) [0|3] ""  RadarFrontCenter,DASy
 SG_ VFC_Obj07A_Heading : 240|9@1+ (0.01,-1.57) [-1.57|1.57] "rad"  RadarFrontCenter,DASy
 SG_ VFC_Obj07A_LengthStdDev : 249|7@1+ (0.05,0) [0|5] "m"  RadarFrontCenter,DASy
 SG_ VFC_Obj07A_PhiMid : 256|13@1+ (0.00025,-1) [-1|1] ""  RadarFrontCenter,DASy
 SG_ VFC_Obj07A_Width : 269|11@1+ (0.01,0) [0|12] "m"  RadarFrontCenter,DASy
 SG_ VFC_Obj07A_PhiMidStdDev : 280|8@1+ (0.0002,0) [0|0.05] ""  RadarFrontCenter,DASy
 SG_ VFC_Obj07A_PhiRight : 288|13@1+ (0.00025,-1) [-1|1] ""  RadarFrontCenter,DASy
 SG_ VFC_Obj07A_VisibleView : 301|3@1+ (1,0) [0|4] ""  RadarFrontCenter,DASy
 SG_ VFC_Obj07A_PhiRightStdDev : 304|8@1+ (0.0002,0) [0|0.05] ""  RadarFrontCenter,DASy
 SG_ VFC_Obj07A_PhiLeftVel : 312|13@1+ (0.001,-4) [-4|4] "1/s"  RadarFrontCenter,DASy
 SG_ VFC_Obj07A_PhiRightVel : 328|13@1+ (0.001,-4) [-4|4] "1/s"  RadarFrontCenter,DASy
 SG_ VFC_Obj07A_PhiRightVelStdDev : 344|8@1+ (0.001,0) [0|0.25] "1/s"  RadarFrontCenter,DASy
 SG_ VFC_Obj07A_PhiLeftVelStdDev : 352|8@1+ (0.001,0) [0|0.25] "1/s"  RadarFrontCenter,DASy
 SG_ VFC_Obj07A_PhiTop : 360|12@1+ (0.00025,-0.4) [-0.4|0.4] ""  RadarFrontCenter,DASy
 SG_ VFC_Obj07A_PhiBottom : 372|12@1+ (0.00025,-0.4) [-0.4|0.4] ""  RadarFrontCenter,DASy
 SG_ VFC_Obj07A_PhiTopStdDev : 384|8@1+ (0.0002,0) [0|0.05] ""  RadarFrontCenter,DASy
 SG_ VFC_Obj07A_HeadOrientation : 392|4@1+ (1,0) [0|10] ""  RadarFrontCenter,DASy
 SG_ VFC_Obj07A_Type : 396|4@1+ (1,0) [0|15] ""  RadarFrontCenter,DASy
 SG_ VFC_Obj07A_PhiBottomStdDev : 400|8@1+ (0.0002,0) [0|0.05] ""  RadarFrontCenter,DASy
 SG_ VFC_Obj07A_NormVx : 408|16@1+ (0.001,-40) [-40|25] "1/s"  RadarFrontCenter,DASy
 SG_ VFC_Obj07A_NormAx : 424|13@1+ (0.002,-10) [-10|6] "1/s^2"  RadarFrontCenter,DASy
 SG_ VFC_Obj07A_NormAxStdDev : 440|10@1+ (0.0025,0) [0|2.5] "1/s^2"  RadarFrontCenter,DASy
 SG_ VFC_Obj07A_ProbMovingLat : 450|6@1+ (2,0) [0|100] "%"  RadarFrontCenter,DASy
 SG_ VFC_Obj07A_ID : 456|8@1+ (1,0) [0|254] ""  RadarFrontCenter,DASy
 SG_ VFC_Obj07A_NormVxStdDev : 464|10@1+ (0.001,0) [0|1] "1/s"  RadarFrontCenter,DASy
 SG_ VFC_Obj07A_ProbMovingLong : 474|6@1+ (2,0) [0|100] "%"  RadarFrontCenter,DASy

BO_ 191 VFC_Object07B: 16 MPC3
 SG_ VFC_Obj07B_TTIPC_StdDev : 120|7@1+ (0.0625,0) [0|7.875] ""  RadarFrontCenter,DASy
 SG_ VFC_Obj07B_TTIPC : 104|11@1+ (0.008,-8) [-8|8] ""  RadarFrontCenter,DASy
 SG_ VFC_Obj07B_AngLongitude : 88|10@1+ (0.005,-2.5) [-2.5|2.5] "rad/s"  RadarFrontCenter,DASy
 SG_ VFC_Obj07B_CRC : 0|16@1+ (1,0) [0|65535] ""  RadarFrontCenter,DASy
 SG_ VFC_Obj07B_AliveCtr : 16|8@1+ (1,0) [0|255] ""  RadarFrontCenter,DASy
 SG_ VFC_Obj07B_BlockCtr : 24|4@1+ (1,0) [0|15] ""  RadarFrontCenter,DASy
 SG_ VFC_Obj07B_ScaleChange : 32|14@1+ (0.0001,0.5) [0.5|2.1] ""  RadarFrontCenter,DASy
 SG_ VFC_Obj07B_ScaleChngStdDev : 48|10@1+ (0.0001,0) [0|0.1] ""  RadarFrontCenter,DASy
 SG_ VFC_Obj07B_LineEdgeRightEgo : 58|1@1+ (1,0) [0|1] ""  RadarFrontCenter,DASy
 SG_ VFC_Obj07B_LineEdgeLeftEgo : 59|1@1+ (1,0) [0|1] ""  RadarFrontCenter,DASy
 SG_ VFC_Obj07B_CompletelyInImg : 60|1@1+ (1,0) [0|1] ""  RadarFrontCenter,DASy
 SG_ VFC_Obj07B_DirIndicator : 61|3@1+ (1,0) [0|7] ""  RadarFrontCenter,DASy
 SG_ VFC_Obj07B_LineEdgeAngle : 64|13@1+ (0.00025,-1) [-1|1] "rad"  RadarFrontCenter,DASy
 SG_ VFC_Obj07B_BrakeLight : 77|3@1+ (1,0) [0|7] ""  RadarFrontCenter,DASy
 SG_ VFC_Obj07B_MeasSource : 80|5@1+ (1,0) [0|31] ""  RadarFrontCenter,DASy
 SG_ VFC_Obj07B_Reliab : 98|6@1+ (1,0) [0|63] ""  RadarFrontCenter,DASy

BO_ 192 VFC_Object08A: 64 MPC3
 SG_ VFC_Obj08A_CRC : 0|16@1+ (1,0) [0|65535] ""  RadarFrontCenter,DASy
 SG_ VFC_Obj08A_AliveCtr : 16|8@1+ (1,0) [0|255] ""  RadarFrontCenter,DASy
 SG_ VFC_Obj08A_BlockCtr : 24|4@1+ (1,0) [0|15] ""  RadarFrontCenter,DASy
 SG_ VFC_Obj08A_ProtOrderIndex : 32|6@1+ (1,0) [0|63] ""  RadarFrontCenter,DASy
 SG_ VFC_Obj08A_Ax : 39|9@1+ (0.1,-16) [-16|16] "m/s^2"  RadarFrontCenter,DASy
 SG_ VFC_Obj08A_Vx : 48|12@1+ (0.1,-154) [-154|50] "m/s"  RadarFrontCenter,DASy
 SG_ VFC_Obj08A_Dx : 60|12@1+ (0.05,0) [0|204.7] "m"  RadarFrontCenter,DASy
 SG_ VFC_Obj08A_Dy : 72|14@1+ (0.01,-80) [-80|80] "m"  RadarFrontCenter,DASy
 SG_ VFC_Obj08A_Vy : 86|10@1+ (0.1,-50) [-50|50] "m/s"  RadarFrontCenter,DASy
 SG_ VFC_Obj08A_Ay : 96|8@1+ (0.1,-12) [-12|12] "m/s^2"  RadarFrontCenter,DASy
 SG_ VFC_Obj08A_DyStdDev : 104|10@1+ (0.02,0) [0|20] "m"  RadarFrontCenter,DASy
 SG_ VFC_Obj08A_DxStdDev : 118|10@1+ (0.05,0) [0|50] "m"  RadarFrontCenter,DASy
 SG_ VFC_Obj08A_VxStdDev : 128|10@1+ (0.1,0) [0|100] "m/s"  RadarFrontCenter,DASy
 SG_ VFC_Obj08A_ExistProb : 138|6@1+ (2,0) [0|100] "%"  RadarFrontCenter,DASy
 SG_ VFC_Obj08A_VyStdDev : 144|9@1+ (0.1,0) [0|50] "m/s"  RadarFrontCenter,DASy
 SG_ VFC_Obj08A_TypeProb : 154|6@1+ (2,0) [0|100] "%"  RadarFrontCenter,DASy
 SG_ VFC_Obj08A_AxStdDev : 160|8@1+ (0.1,0) [0|25] "m/s^2"  RadarFrontCenter,DASy
 SG_ VFC_Obj08A_AyStdDev : 168|8@1+ (0.1,0) [0|25] "m/s^2"  RadarFrontCenter,DASy
 SG_ VFC_Obj08A_PhiLeft : 176|13@1+ (0.00025,-1) [-1|1] ""  RadarFrontCenter,DASy
 SG_ VFC_Obj08A_ClassifiedView : 189|3@1+ (1,0) [0|7] ""  RadarFrontCenter,DASy
 SG_ VFC_Obj08A_Length : 192|9@1+ (0.05,0) [0|25.5] "m"  RadarFrontCenter,DASy
 SG_ VFC_Obj08A_WidthStdDev : 201|7@1+ (0.01,0) [0|1] "m"  RadarFrontCenter,DASy
 SG_ VFC_Obj08A_Height : 208|9@1+ (0.01,0) [0|5.11] "m"  RadarFrontCenter,DASy
 SG_ VFC_Obj08A_HeightStdDev : 217|7@1+ (0.01,0) [0|1] "m"  RadarFrontCenter,DASy
 SG_ VFC_Obj08A_PhiLeftStdDev : 224|8@1+ (0.0002,0) [0|0.05] ""  RadarFrontCenter,DASy
 SG_ VFC_Obj08A_HeadingStdDev : 232|6@1+ (0.01,0) [0|0.5] "rad"  RadarFrontCenter,DASy
 SG_ VFC_Obj08A_Measured : 238|2@1+ (1,0) [0|3] ""  RadarFrontCenter,DASy
 SG_ VFC_Obj08A_Heading : 240|9@1+ (0.01,-1.57) [-1.57|1.57] "rad"  RadarFrontCenter,DASy
 SG_ VFC_Obj08A_LengthStdDev : 249|7@1+ (0.05,0) [0|5] "m"  RadarFrontCenter,DASy
 SG_ VFC_Obj08A_PhiMid : 256|13@1+ (0.00025,-1) [-1|1] ""  RadarFrontCenter,DASy
 SG_ VFC_Obj08A_Width : 269|11@1+ (0.01,0) [0|12] "m"  RadarFrontCenter,DASy
 SG_ VFC_Obj08A_PhiMidStdDev : 280|8@1+ (0.0002,0) [0|0.05] ""  RadarFrontCenter,DASy
 SG_ VFC_Obj08A_PhiRight : 288|13@1+ (0.00025,-1) [-1|1] ""  RadarFrontCenter,DASy
 SG_ VFC_Obj08A_VisibleView : 301|3@1+ (1,0) [0|4] ""  RadarFrontCenter,DASy
 SG_ VFC_Obj08A_PhiRightStdDev : 304|8@1+ (0.0002,0) [0|0.05] ""  RadarFrontCenter,DASy
 SG_ VFC_Obj08A_PhiLeftVel : 312|13@1+ (0.001,-4) [-4|4] "1/s"  RadarFrontCenter,DASy
 SG_ VFC_Obj08A_PhiRightVel : 328|13@1+ (0.001,-4) [-4|4] "1/s"  RadarFrontCenter,DASy
 SG_ VFC_Obj08A_PhiRightVelStdDev : 344|8@1+ (0.001,0) [0|0.25] "1/s"  RadarFrontCenter,DASy
 SG_ VFC_Obj08A_PhiLeftVelStdDev : 352|8@1+ (0.001,0) [0|0.25] "1/s"  RadarFrontCenter,DASy
 SG_ VFC_Obj08A_PhiTop : 360|12@1+ (0.00025,-0.4) [-0.4|0.4] ""  RadarFrontCenter,DASy
 SG_ VFC_Obj08A_PhiBottom : 372|12@1+ (0.00025,-0.4) [-0.4|0.4] ""  RadarFrontCenter,DASy
 SG_ VFC_Obj08A_PhiTopStdDev : 384|8@1+ (0.0002,0) [0|0.05] ""  RadarFrontCenter,DASy
 SG_ VFC_Obj08A_HeadOrientation : 392|4@1+ (1,0) [0|10] ""  RadarFrontCenter,DASy
 SG_ VFC_Obj08A_Type : 396|4@1+ (1,0) [0|15] ""  RadarFrontCenter,DASy
 SG_ VFC_Obj08A_PhiBottomStdDev : 400|8@1+ (0.0002,0) [0|0.05] ""  RadarFrontCenter,DASy
 SG_ VFC_Obj08A_NormVx : 408|16@1+ (0.001,-40) [-40|25] "1/s"  RadarFrontCenter,DASy
 SG_ VFC_Obj08A_NormAx : 424|13@1+ (0.002,-10) [-10|6] "1/s^2"  RadarFrontCenter,DASy
 SG_ VFC_Obj08A_NormAxStdDev : 440|10@1+ (0.0025,0) [0|2.5] "1/s^2"  RadarFrontCenter,DASy
 SG_ VFC_Obj08A_ProbMovingLat : 450|6@1+ (2,0) [0|100] "%"  RadarFrontCenter,DASy
 SG_ VFC_Obj08A_ID : 456|8@1+ (1,0) [0|254] ""  RadarFrontCenter,DASy
 SG_ VFC_Obj08A_NormVxStdDev : 464|10@1+ (0.001,0) [0|1] "1/s"  RadarFrontCenter,DASy
 SG_ VFC_Obj08A_ProbMovingLong : 474|6@1+ (2,0) [0|100] "%"  RadarFrontCenter,DASy

BO_ 193 VFC_Object08B: 16 MPC3
 SG_ VFC_Obj08B_TTIPC_StdDev : 120|7@1+ (0.0625,0) [0|7.875] ""  RadarFrontCenter,DASy
 SG_ VFC_Obj08B_TTIPC : 104|11@1+ (0.008,-8) [-8|8] ""  RadarFrontCenter,DASy
 SG_ VFC_Obj08B_AngLongitude : 88|10@1+ (0.005,-2.5) [-2.5|2.5] "rad/s"  RadarFrontCenter,DASy
 SG_ VFC_Obj08B_CRC : 0|16@1+ (1,0) [0|65535] ""  RadarFrontCenter,DASy
 SG_ VFC_Obj08B_AliveCtr : 16|8@1+ (1,0) [0|255] ""  RadarFrontCenter,DASy
 SG_ VFC_Obj08B_BlockCtr : 24|4@1+ (1,0) [0|15] ""  RadarFrontCenter,DASy
 SG_ VFC_Obj08B_ScaleChange : 32|14@1+ (0.0001,0.5) [0.5|2.1] ""  RadarFrontCenter,DASy
 SG_ VFC_Obj08B_ScaleChngStdDev : 48|10@1+ (0.0001,0) [0|0.1] ""  RadarFrontCenter,DASy
 SG_ VFC_Obj08B_LineEdgeRightEgo : 58|1@1+ (1,0) [0|1] ""  RadarFrontCenter,DASy
 SG_ VFC_Obj08B_LineEdgeLeftEgo : 59|1@1+ (1,0) [0|1] ""  RadarFrontCenter,DASy
 SG_ VFC_Obj08B_CompletelyInImg : 60|1@1+ (1,0) [0|1] ""  RadarFrontCenter,DASy
 SG_ VFC_Obj08B_DirIndicator : 61|3@1+ (1,0) [0|7] ""  RadarFrontCenter,DASy
 SG_ VFC_Obj08B_LineEdgeAngle : 64|13@1+ (0.00025,-1) [-1|1] "rad"  RadarFrontCenter,DASy
 SG_ VFC_Obj08B_BrakeLight : 77|3@1+ (1,0) [0|7] ""  RadarFrontCenter,DASy
 SG_ VFC_Obj08B_MeasSource : 80|5@1+ (1,0) [0|31] ""  RadarFrontCenter,DASy
 SG_ VFC_Obj08B_Reliab : 98|6@1+ (1,0) [0|63] ""  RadarFrontCenter,DASy

CM_ "for BJEV BL05";
CM_ BO_ 3221225472 "This is a message for not used signals, created by Vector CANdb++ DBC OLE DB Provider.";
CM_ BO_ 255 "AUTOSAR Time Sync";
CM_ SG_ 255 ADAS_SYNC_FC_OVS "in FUP PDU
OVS = Overflow of seconds";
CM_ SG_ 255 ADAS_SYNC_FC_SGW "in FUP PDU
SyncToGTM = 0
SyncToSubDomain = 1";
CM_ SG_ 255 ADAS_SYNC_FC_Reserved "in FUP PDU
reserved, default =0";
CM_ SG_ 255 ADAS_SYNC_FC_SyncTime "TSync: SyncTimeSec = 32 bit LSB of the 48 bits seconds part of the time
TSync FUP: SyncTimeNSec = 32 Bit time value in nanoseconds";
CM_ SG_ 255 ADAS_SYNC_FC_TimeDomain "Time Domain";
CM_ SG_ 255 ADAS_SYNC_FC_SequenceCnt "Sequence counter";
CM_ SG_ 255 ADAS_SYNC_FC_CRC "CRC";
CM_ SG_ 255 ADAS_SYNC_FC_Type "Type=0x20 : TSync    Type=0x28 : TSync FUP";
CM_ SG_ 75 ADAS_AEBHMI_CRC "E2E Profile 5--CRC";
CM_ SG_ 75 ADAS_AEBHMI_AliveCnt "E2E Profile 5--Alive Counter";
CM_ SG_ 75 ADAS_FwdWarnFltTxt "FCW warning system failure";
CM_ SG_ 75 ADAS_FCWSwtFb "FCW warning switch status feedback";
CM_ SG_ 75 ADAS_AEBSwtFb "AEB switch status feedbac";
CM_ SG_ 75 ADAS_ADASSnvtySetFb "ADAS sensitivity set feedback";
CM_ SG_ 75 ADAS_Warn_FCW "FCW warning";
CM_ SG_ 75 ADAS_WarnTyp_FCWAEB "FCWAEB warning type";
CM_ SG_ 75 ADAS_Sts_FCW "FCW status";
CM_ SG_ 75 ADAS_Sts_AEB "AEB status";
CM_ SG_ 74 ADAS_FrntTar_AliveCnt "E2E Profile 5--Alive Counter";
CM_ SG_ 74 ADAS_FrntTar_CRC "E2E Profile 5--CRC";
CM_ SG_ 74 ADAS_FrntTar1Typ_ACC "Front ACC/AEB target object type";
CM_ SG_ 74 ADAS_FrntTar1X_ACC "Front ACC/AEB target object in X direction
X direction distance between ego car and front ACC/AEB target object";
CM_ SG_ 74 ADAS_FrntTar1Y_ACC "Front ACC/AEB target object in Y direction
Y direction distance between ego car and front ACC/AEB target object";
CM_ SG_ 81 RFC_SensorS_AliveCtr "Alive counter - Autosar E2E Profile 5";
CM_ SG_ 81 RFC_SensorS_CRC "CRC - Autosar E2E Profile 5";
CM_ BO_ 2281601536 "Frame Counter";
CM_ BO_ 931 "map info. after eHorizon re-constructor processing";
CM_ SG_ 931 VFC_MapInfo_CountryCode "country code, ISO3166-1, CN=156";
CM_ SG_ 931 VFC_MapInfo_CurrentLane "Current Lane where vehicle is located";
CM_ SG_ 931 VFC_MapInfo_RoadCurv "the road curvature in the driving direction, 
maximum curvature value(minimum radius) within the range of video detection( 150m?)";
CM_ SG_ 931 VFC_MapInfo_BuildUp_Dx "distance to the buildup in the driving direction";
CM_ SG_ 931 VFC_MapInfo_BuildUp "vehicle relation to the buildup";
CM_ SG_ 931 VFC_MapInfo_Bridge_Dx "distance to the bridge in the driving direction";
CM_ SG_ 931 VFC_MapInfo_Bridge "vehicle relation to the bridge";
CM_ SG_ 931 VFC_MapInfo_Tunnel "vehicle relation to the tunnel";
CM_ SG_ 931 VFC_MapInfo_Tunnel_Dx "distance to the tunnel in the driving direction";
CM_ SG_ 931 VFC_MapInfo_TollGate "vehicle relation to the tollgate";
CM_ SG_ 931 VFC_MapInfo_TollGate_Dx "distance to the tollgate in the driving direction";
CM_ SG_ 931 VFC_MapInfo_DiRoad_Offset200 "Road divided info at offset 200 meter";
CM_ SG_ 931 VFC_MapInfo_LaneNum_Offset200 "Lane number info at offset 200 meter";
CM_ SG_ 931 VFC_MapInfo_LaneNum_Offset0 "Lane number info at offset 0 meter";
CM_ SG_ 931 VFC_MapInfo_DiRoad_Offset0 "Road divided info at offset 0 meter";
CM_ SG_ 931 VFC_MapInfo_RoadClass_Offset200 "road class info,at offset 200 meter";
CM_ SG_ 931 VFC_MapInfo_RoadClass_Offset0 "road class info,at offset 0, that is at the vehicle current position";
CM_ SG_ 931 VFC_MapInfo_AliveCtr "Alive counter - Autosar E2E Profile 5";
CM_ SG_ 931 VFC_MapInfo_CRC "CRC - Autosar E2E Profile 5";
CM_ SG_ 80 VFC_SensorState_Status "Informs the system of the current state of the camera";
CM_ SG_ 80 VFC_SensorState_Report "The status report of the vision system";
CM_ SG_ 80 VFC_SensorState_VisionFault "The current status of the forward looking camera system";
CM_ SG_ 80 VFC_SensorState_VisionDTCs "The current status of the diagnostic";
CM_ SG_ 80 VFC_SensorState_ProtocolVersion "Protocol version BCD coded: Major.Minor, e. g. 0x0102 = V1.2 (Checked-In Version)";
CM_ SG_ 80 VFC_SensorState_BlindnessProb "The probability of the overall camera lens being blinded";
CM_ SG_ 80 VFC_SensorState_AliveCtr "Alive counter - Autosar E2E Profile 5";
CM_ SG_ 80 VFC_SensorState_CRC "CRC - Autosar E2E Profile 5";
CM_ SG_ 160 VFC_ObjHdr_TimeStampStatus "Autosar StbM_TimeBaseStatusType bitfield with extension:
Bit 0: TIMEOUT
Bit 1: Reserved1
Bit 2: SYNC_TO_GATEWAY
Bit 3: GLOBAL_TIME_BASE
Bit 4: TIMELEAP_FUTURE
Bit 5: TIMELEAP_PAST
Bit 6: Reserved6
Bit 7: Extension: GENERAL_ERROR";
CM_ SG_ 160 VFC_ObjHdr_AUTOSARTStamp "The timestamp of when object is measured, in AUTOSAR Time Sync mode";
CM_ SG_ 160 VFC_ObjHdr_CycleTime "Camera Cycle Time";
CM_ SG_ 160 VFC_ObjHdr_MountPosZ "The current estimation of mounting position of the camera in the vertical direction";
CM_ SG_ 160 VFC_ObjHdr_MountPosY "The current estimation of mounting position of the camera in the lateral direction";
CM_ SG_ 160 VFC_ObjHdr_MountPosX "The current estimation of the mounting position of the camera in the longitudinal direction";
CM_ SG_ 160 VFC_ObjHdr_CalibYawStdDev "The standard deviation of the calibrated yaw angle of the camera";
CM_ SG_ 160 VFC_ObjHdr_CalibYawAngle "The calibrated yaw angle of the camera";
CM_ SG_ 160 VFC_ObjHdr_CalibRollStdDev "The standard deviation of the calibrated roll angle of the camera";
CM_ SG_ 160 VFC_ObjHdr_CalibRollAngle "The calibrated roll angle of the camera";
CM_ SG_ 160 VFC_ObjHdr_FreeViewProb "The probability of the camera lens being blocked";
CM_ SG_ 160 VFC_ObjHdr_CalibPitchStdDev "The standard deviation of the calibrated pitch angle of the camera";
CM_ SG_ 160 VFC_ObjHdr_CalibState "The calibration state of the forward looking camera system";
CM_ SG_ 160 VFC_ObjHdr_CalibPitchAngle "The calibrated pitch angle of the camera";
CM_ SG_ 160 VFC_ObjHdr_FrameNo "The frame number that the data belongs to";
CM_ SG_ 160 VFC_ObjHdr_CRC "CRC - Autosar E2E Profile 5";
CM_ SG_ 160 VFC_ObjHdr_AliveCtr "Alive counter - Autosar E2E Profile 5";
CM_ SG_ 160 VFC_ObjHdr_BlockCtr "Protocol-Signal: Block-Counter";
CM_ SG_ 160 VFC_ObjHdr_TimeStamp "The timestamp of when object is measured, or
Time gap between object data measure and send (only in 1R1V)";
CM_ SG_ 160 VFC_ObjHdr_Blindness "Informs the system whether the current object detection is blind or not blind";
CM_ SG_ 160 VFC_ObjHdr_ObjCount "Number of objects that have been detected by the system";
CM_ SG_ 176 VFC_Obj00A_CRC "CRC - Autosar E2E Profile 5";
CM_ SG_ 176 VFC_Obj00A_AliveCtr "Alive counter - Autosar E2E Profile 5";
CM_ SG_ 176 VFC_Obj00A_BlockCtr "Protocol-Signal: Block-Counter";
CM_ SG_ 176 VFC_Obj00A_ProtOrderIndex "Protocol-Signal: Index to ensure same order in Tx and Rx of the objects";
CM_ SG_ 176 VFC_Obj00A_Ax "Object Acceleration in longitudinal direction";
CM_ SG_ 176 VFC_Obj00A_Vx "Object Velocity in longitudinal direction";
CM_ SG_ 176 VFC_Obj00A_Dx "Object Position in longitudinal direction";
CM_ SG_ 176 VFC_Obj00A_Dy "Object Position in lateral direction";
CM_ SG_ 176 VFC_Obj00A_Vy "Object Velocity in lateral direction";
CM_ SG_ 176 VFC_Obj00A_Ay "Object Acceleration in lateral direction";
CM_ SG_ 176 VFC_Obj00A_DyStdDev "Standard deviation of Object position in lateral direction";
CM_ SG_ 176 VFC_Obj00A_DxStdDev "Standard deviation of Object position in longitudinal direction";
CM_ SG_ 176 VFC_Obj00A_VxStdDev "Standard deviation of Object velocity in longitudinal direction";
CM_ SG_ 176 VFC_Obj00A_ExistProb "Object existence probability";
CM_ SG_ 176 VFC_Obj00A_VyStdDev "Standard deviation of Object velocity in lateral direction";
CM_ SG_ 176 VFC_Obj00A_TypeProb "Probability of the classified object type";
CM_ SG_ 176 VFC_Obj00A_AxStdDev "Standard deviation of Object acceleration in longitudinal direction";
CM_ SG_ 176 VFC_Obj00A_AyStdDev "Standard deviation of Object acceleration in lateral direction";
CM_ SG_ 176 VFC_Obj00A_PhiLeft "ACCS Viewing Angle of left object edge(dimensionless)";
CM_ SG_ 176 VFC_Obj00A_ClassifiedView "The classified view of object to be used in connection with Heading angle";
CM_ SG_ 176 VFC_Obj00A_Length "Length of the object";
CM_ SG_ 176 VFC_Obj00A_WidthStdDev "Standard deviation of object width";
CM_ SG_ 176 VFC_Obj00A_Height "Height of the object";
CM_ SG_ 176 VFC_Obj00A_HeightStdDev "Standard deviation of object height";
CM_ SG_ 176 VFC_Obj00A_PhiLeftStdDev "Standard deviation of the ACCS angle of left object(dimensionless)";
CM_ SG_ 176 VFC_Obj00A_HeadingStdDev "Standard deviation of object Heading angle";
CM_ SG_ 176 VFC_Obj00A_Measured "Indicator if the object detected is measured or predicted.";
CM_ SG_ 176 VFC_Obj00A_Heading "Heading angle of the object";
CM_ SG_ 176 VFC_Obj00A_LengthStdDev "Standard deviation of object length";
CM_ SG_ 176 VFC_Obj00A_PhiMid "Viewing angle of the ACCS middle of the object(dimensionless)";
CM_ SG_ 176 VFC_Obj00A_Width "Width of the object";
CM_ SG_ 176 VFC_Obj00A_PhiMidStdDev "Standard deviation of the ACCS middle angle of object(dimensionless)";
CM_ SG_ 176 VFC_Obj00A_PhiRight "ACCS Viewing Angle of right object edge(dimensionless)";
CM_ SG_ 176 VFC_Obj00A_VisibleView "The visible view of the detectd object";
CM_ SG_ 176 VFC_Obj00A_PhiRightStdDev "Standard deviation of the ACCS angle of right object(dimensionless)";
CM_ SG_ 176 VFC_Obj00A_PhiLeftVel "Velocity of the ACCS viewing angle of the left edge";
CM_ SG_ 176 VFC_Obj00A_PhiRightVel "Velocity of the ACCS viewing angle of the right edge";
CM_ SG_ 176 VFC_Obj00A_PhiRightVelStdDev "Standard deviation of ACCS viewing angle velocity of right object edge from ego vehicle related to camera";
CM_ SG_ 176 VFC_Obj00A_PhiLeftVelStdDev "Standard deviation of ACCS viewing angle velocity of left object edge from ego vehicle related to camera";
CM_ SG_ 176 VFC_Obj00A_PhiTop "ACCS Viewing angle of the top of the object(dimensionless)";
CM_ SG_ 176 VFC_Obj00A_PhiBottom "ACCS Viewing angle of the bottom of the object(dimensionless)";
CM_ SG_ 176 VFC_Obj00A_PhiTopStdDev "Standard deviation  of the ACCS top angle of object(dimensionless)";
CM_ SG_ 176 VFC_Obj00A_HeadOrientation "The orientation of the head of cyclists or pedestrians that are detected.";
CM_ SG_ 176 VFC_Obj00A_Type "Classification of the object";
CM_ SG_ 176 VFC_Obj00A_PhiBottomStdDev "Standard deviation of the ACCS bottom angle of object(dimensionless)";
CM_ SG_ 176 VFC_Obj00A_NormVx "Normalised object velocity in longitudinal direction.";
CM_ SG_ 176 VFC_Obj00A_NormAx "Normalised object acceleration in longitudinal direction.";
CM_ SG_ 176 VFC_Obj00A_NormAxStdDev "Standard deviation of Normalized Object Acceleration in longitudinal direction";
CM_ SG_ 176 VFC_Obj00A_ProbMovingLat "Probability of object moving laterally";
CM_ SG_ 176 VFC_Obj00A_ID "Unique Object ID";
CM_ SG_ 176 VFC_Obj00A_NormVxStdDev "Standard deviation of Normalized Object Velocity in longitudinal direction";
CM_ SG_ 176 VFC_Obj00A_ProbMovingLong "Probability of object moving longitudinally";
CM_ SG_ 177 VFC_Obj00B_TTIPC_StdDev "Inverse TTI standard deviation";
CM_ SG_ 177 VFC_Obj00B_TTIPC "Inverse TTI";
CM_ SG_ 177 VFC_Obj00B_AngLongitude "angular velocity with regarding to longitudinal direction";
CM_ SG_ 177 VFC_Obj00B_CRC "CRC - Autosar E2E Profile 5";
CM_ SG_ 177 VFC_Obj00B_AliveCtr "Alive counter - Autosar E2E Profile 5";
CM_ SG_ 177 VFC_Obj00B_BlockCtr "Protocol-Signal: Block Counter";
CM_ SG_ 177 VFC_Obj00B_ScaleChange "A scale change of of the detected object";
CM_ SG_ 177 VFC_Obj00B_ScaleChngStdDev "Standard deviation of object scale change";
CM_ SG_ 177 VFC_Obj00B_LineEdgeRightEgo "ObjLineEdgeAngle refers to the line which limits the host vehicle lane on the right side";
CM_ SG_ 177 VFC_Obj00B_LineEdgeLeftEgo "ObjLineEdgeAngle refers to the line which limits the host vehicle lane on the left side";
CM_ SG_ 177 VFC_Obj00B_CompletelyInImg "indicator if the object is completely measrued in the image";
CM_ SG_ 177 VFC_Obj00B_DirIndicator "The detected direction indicator lights";
CM_ SG_ 177 VFC_Obj00B_LineEdgeAngle "Angle between the video object's edge and the lane marking";
CM_ SG_ 177 VFC_Obj00B_BrakeLight "The number of detected lights. More confident if more lights are detected.";
CM_ SG_ 177 VFC_Obj00B_MeasSource "Bitmask for the measurement programs from which this object originates";
CM_ SG_ 177 VFC_Obj00B_Reliab "Bitmask that indicates the algorithmic paths that have detected this object";
CM_ SG_ 178 VFC_Obj01A_CRC "CRC - Autosar E2E Profile 5";
CM_ SG_ 178 VFC_Obj01A_AliveCtr "Alive counter - Autosar E2E Profile 5";
CM_ SG_ 178 VFC_Obj01A_BlockCtr "Protocol-Signal: Block-Counter";
CM_ SG_ 178 VFC_Obj01A_ProtOrderIndex "Protocol-Signal: Index to ensure same order in Tx and Rx of the objects";
CM_ SG_ 178 VFC_Obj01A_Ax "Object Acceleration in longitudinal direction";
CM_ SG_ 178 VFC_Obj01A_Vx "Object Velocity in longitudinal direction";
CM_ SG_ 178 VFC_Obj01A_Dx "Object Position in longitudinal direction";
CM_ SG_ 178 VFC_Obj01A_Dy "Object Position in lateral direction";
CM_ SG_ 178 VFC_Obj01A_Vy "Object Velocity in lateral direction";
CM_ SG_ 178 VFC_Obj01A_Ay "Object Acceleration in lateral direction";
CM_ SG_ 178 VFC_Obj01A_DyStdDev "Standard deviation of Object position in lateral direction";
CM_ SG_ 178 VFC_Obj01A_DxStdDev "Standard deviation of Object position in longitudinal direction";
CM_ SG_ 178 VFC_Obj01A_VxStdDev "Standard deviation of Object velocity in longitudinal direction";
CM_ SG_ 178 VFC_Obj01A_ExistProb "Object existence probability";
CM_ SG_ 178 VFC_Obj01A_VyStdDev "Standard deviation of Object velocity in lateral direction";
CM_ SG_ 178 VFC_Obj01A_TypeProb "Probability of the classified object type";
CM_ SG_ 178 VFC_Obj01A_AxStdDev "Standard deviation of Object acceleration in longitudinal direction";
CM_ SG_ 178 VFC_Obj01A_AyStdDev "Standard deviation of Object acceleration in lateral direction";
CM_ SG_ 178 VFC_Obj01A_PhiLeft "ACCS Viewing Angle of left object edge(dimensionless)";
CM_ SG_ 178 VFC_Obj01A_ClassifiedView "The classified view of object to be used in connection with Heading angle";
CM_ SG_ 178 VFC_Obj01A_Length "Length of the object";
CM_ SG_ 178 VFC_Obj01A_WidthStdDev "Standard deviation of object width";
CM_ SG_ 178 VFC_Obj01A_Height "Height of the object";
CM_ SG_ 178 VFC_Obj01A_HeightStdDev "Standard deviation of object height";
CM_ SG_ 178 VFC_Obj01A_PhiLeftStdDev "Standard deviation of the ACCS angle of left object(dimensionless)";
CM_ SG_ 178 VFC_Obj01A_HeadingStdDev "Standard deviation of object Heading angle";
CM_ SG_ 178 VFC_Obj01A_Measured "Indicator if the object detected is measured or predicted.";
CM_ SG_ 178 VFC_Obj01A_Heading "Heading angle of the object";
CM_ SG_ 178 VFC_Obj01A_LengthStdDev "Standard deviation of object length";
CM_ SG_ 178 VFC_Obj01A_PhiMid "Viewing angle of the ACCS middle of the object(dimensionless)";
CM_ SG_ 178 VFC_Obj01A_Width "Width of the object";
CM_ SG_ 178 VFC_Obj01A_PhiMidStdDev "Standard deviation of the ACCS middle angle of object(dimensionless)";
CM_ SG_ 178 VFC_Obj01A_PhiRight "ACCS Viewing Angle of right object edge(dimensionless)";
CM_ SG_ 178 VFC_Obj01A_VisibleView "The visible view of the detectd object";
CM_ SG_ 178 VFC_Obj01A_PhiRightStdDev "Standard deviation of the ACCS angle of right object(dimensionless)";
CM_ SG_ 178 VFC_Obj01A_PhiLeftVel "Velocity of the ACCS viewing angle of the left edge";
CM_ SG_ 178 VFC_Obj01A_PhiRightVel "Velocity of the ACCS viewing angle of the right edge";
CM_ SG_ 178 VFC_Obj01A_PhiRightVelStdDev "Standard deviation of ACCS viewing angle velocity of right object edge from ego vehicle related to camera";
CM_ SG_ 178 VFC_Obj01A_PhiLeftVelStdDev "Standard deviation of ACCS viewing angle velocity of left object edge from ego vehicle related to camera";
CM_ SG_ 178 VFC_Obj01A_PhiTop "ACCS Viewing angle of the top of the object(dimensionless)";
CM_ SG_ 178 VFC_Obj01A_PhiBottom "ACCS Viewing angle of the bottom of the object(dimensionless)";
CM_ SG_ 178 VFC_Obj01A_PhiTopStdDev "Standard deviation  of the ACCS top angle of object(dimensionless)";
CM_ SG_ 178 VFC_Obj01A_HeadOrientation "The orientation of the head of cyclists or pedestrians that are detected.";
CM_ SG_ 178 VFC_Obj01A_Type "Classification of the object";
CM_ SG_ 178 VFC_Obj01A_PhiBottomStdDev "Standard deviation of the ACCS bottom angle of object(dimensionless)";
CM_ SG_ 178 VFC_Obj01A_NormVx "Normalised object velocity in longitudinal direction.";
CM_ SG_ 178 VFC_Obj01A_NormAx "Normalised object acceleration in longitudinal direction.";
CM_ SG_ 178 VFC_Obj01A_NormAxStdDev "Standard deviation of Normalized Object Acceleration in longitudinal direction";
CM_ SG_ 178 VFC_Obj01A_ProbMovingLat "Probability of object moving laterally";
CM_ SG_ 178 VFC_Obj01A_ID "Unique Object ID";
CM_ SG_ 178 VFC_Obj01A_NormVxStdDev "Standard deviation of Normalized Object Velocity in longitudinal direction";
CM_ SG_ 178 VFC_Obj01A_ProbMovingLong "Probability of object moving longitudinally";
CM_ SG_ 179 VFC_Obj01B_TTIPC_StdDev "Inverse TTI standard deviation";
CM_ SG_ 179 VFC_Obj01B_TTIPC "Inverse TTI";
CM_ SG_ 179 VFC_Obj01B_AngLongitude "angular velocity with regarding to longitudinal direction";
CM_ SG_ 179 VFC_Obj01B_CRC "CRC - Autosar E2E Profile 5";
CM_ SG_ 179 VFC_Obj01B_AliveCtr "Alive counter - Autosar E2E Profile 5";
CM_ SG_ 179 VFC_Obj01B_BlockCtr "Protocol-Signal: Block Counter";
CM_ SG_ 179 VFC_Obj01B_ScaleChange "A scale change of of the detected object";
CM_ SG_ 179 VFC_Obj01B_ScaleChngStdDev "Standard deviation of object scale change";
CM_ SG_ 179 VFC_Obj01B_LineEdgeRightEgo "ObjLineEdgeAngle refers to the line which limits the host vehicle lane on the right side";
CM_ SG_ 179 VFC_Obj01B_LineEdgeLeftEgo "ObjLineEdgeAngle refers to the line which limits the host vehicle lane on the left side";
CM_ SG_ 179 VFC_Obj01B_CompletelyInImg "indicator if the object is completely measrued in the image";
CM_ SG_ 179 VFC_Obj01B_DirIndicator "The detected direction indicator lights";
CM_ SG_ 179 VFC_Obj01B_LineEdgeAngle "Angle between the video object's edge and the lane marking";
CM_ SG_ 179 VFC_Obj01B_BrakeLight "The number of detected lights. More confident if more lights are detected.";
CM_ SG_ 179 VFC_Obj01B_MeasSource "Bitmask for the measurement programs from which this object originates";
CM_ SG_ 179 VFC_Obj01B_Reliab "Bitmask that indicates the algorithmic paths that have detected this object";
CM_ SG_ 180 VFC_Obj02A_CRC "CRC - Autosar E2E Profile 5";
CM_ SG_ 180 VFC_Obj02A_AliveCtr "Alive counter - Autosar E2E Profile 5";
CM_ SG_ 180 VFC_Obj02A_BlockCtr "Protocol-Signal: Block-Counter";
CM_ SG_ 180 VFC_Obj02A_ProtOrderIndex "Protocol-Signal: Index to ensure same order in Tx and Rx of the objects";
CM_ SG_ 180 VFC_Obj02A_Ax "Object Acceleration in longitudinal direction";
CM_ SG_ 180 VFC_Obj02A_Vx "Object Velocity in longitudinal direction";
CM_ SG_ 180 VFC_Obj02A_Dx "Object Position in longitudinal direction";
CM_ SG_ 180 VFC_Obj02A_Dy "Object Position in lateral direction";
CM_ SG_ 180 VFC_Obj02A_Vy "Object Velocity in lateral direction";
CM_ SG_ 180 VFC_Obj02A_Ay "Object Acceleration in lateral direction";
CM_ SG_ 180 VFC_Obj02A_DyStdDev "Standard deviation of Object position in lateral direction";
CM_ SG_ 180 VFC_Obj02A_DxStdDev "Standard deviation of Object position in longitudinal direction";
CM_ SG_ 180 VFC_Obj02A_VxStdDev "Standard deviation of Object velocity in longitudinal direction";
CM_ SG_ 180 VFC_Obj02A_ExistProb "Object existence probability";
CM_ SG_ 180 VFC_Obj02A_VyStdDev "Standard deviation of Object velocity in lateral direction";
CM_ SG_ 180 VFC_Obj02A_TypeProb "Probability of the classified object type";
CM_ SG_ 180 VFC_Obj02A_AxStdDev "Standard deviation of Object acceleration in longitudinal direction";
CM_ SG_ 180 VFC_Obj02A_AyStdDev "Standard deviation of Object acceleration in lateral direction";
CM_ SG_ 180 VFC_Obj02A_PhiLeft "ACCS Viewing Angle of left object edge(dimensionless)";
CM_ SG_ 180 VFC_Obj02A_ClassifiedView "The classified view of object to be used in connection with Heading angle";
CM_ SG_ 180 VFC_Obj02A_Length "Length of the object";
CM_ SG_ 180 VFC_Obj02A_WidthStdDev "Standard deviation of object width";
CM_ SG_ 180 VFC_Obj02A_Height "Height of the object";
CM_ SG_ 180 VFC_Obj02A_HeightStdDev "Standard deviation of object height";
CM_ SG_ 180 VFC_Obj02A_PhiLeftStdDev "Standard deviation of the ACCS angle of left object(dimensionless)";
CM_ SG_ 180 VFC_Obj02A_HeadingStdDev "Standard deviation of object Heading angle";
CM_ SG_ 180 VFC_Obj02A_Measured "Indicator if the object detected is measured or predicted.";
CM_ SG_ 180 VFC_Obj02A_Heading "Heading angle of the object";
CM_ SG_ 180 VFC_Obj02A_LengthStdDev "Standard deviation of object length";
CM_ SG_ 180 VFC_Obj02A_PhiMid "Viewing angle of the ACCS middle of the object(dimensionless)";
CM_ SG_ 180 VFC_Obj02A_Width "Width of the object";
CM_ SG_ 180 VFC_Obj02A_PhiMidStdDev "Standard deviation of the ACCS middle angle of object(dimensionless)";
CM_ SG_ 180 VFC_Obj02A_PhiRight "ACCS Viewing Angle of right object edge(dimensionless)";
CM_ SG_ 180 VFC_Obj02A_VisibleView "The visible view of the detectd object";
CM_ SG_ 180 VFC_Obj02A_PhiRightStdDev "Standard deviation of the ACCS angle of right object(dimensionless)";
CM_ SG_ 180 VFC_Obj02A_PhiLeftVel "Velocity of the ACCS viewing angle of the left edge";
CM_ SG_ 180 VFC_Obj02A_PhiRightVel "Velocity of the ACCS viewing angle of the right edge";
CM_ SG_ 180 VFC_Obj02A_PhiRightVelStdDev "Standard deviation of ACCS viewing angle velocity of right object edge from ego vehicle related to camera";
CM_ SG_ 180 VFC_Obj02A_PhiLeftVelStdDev "Standard deviation of ACCS viewing angle velocity of left object edge from ego vehicle related to camera";
CM_ SG_ 180 VFC_Obj02A_PhiTop "ACCS Viewing angle of the top of the object(dimensionless)";
CM_ SG_ 180 VFC_Obj02A_PhiBottom "ACCS Viewing angle of the bottom of the object(dimensionless)";
CM_ SG_ 180 VFC_Obj02A_PhiTopStdDev "Standard deviation  of the ACCS top angle of object(dimensionless)";
CM_ SG_ 180 VFC_Obj02A_HeadOrientation "The orientation of the head of cyclists or pedestrians that are detected.";
CM_ SG_ 180 VFC_Obj02A_Type "Classification of the object";
CM_ SG_ 180 VFC_Obj02A_PhiBottomStdDev "Standard deviation of the ACCS bottom angle of object(dimensionless)";
CM_ SG_ 180 VFC_Obj02A_NormVx "Normalised object velocity in longitudinal direction.";
CM_ SG_ 180 VFC_Obj02A_NormAx "Normalised object acceleration in longitudinal direction.";
CM_ SG_ 180 VFC_Obj02A_NormAxStdDev "Standard deviation of Normalized Object Acceleration in longitudinal direction";
CM_ SG_ 180 VFC_Obj02A_ProbMovingLat "Probability of object moving laterally";
CM_ SG_ 180 VFC_Obj02A_ID "Unique Object ID";
CM_ SG_ 180 VFC_Obj02A_NormVxStdDev "Standard deviation of Normalized Object Velocity in longitudinal direction";
CM_ SG_ 180 VFC_Obj02A_ProbMovingLong "Probability of object moving longitudinally";
CM_ SG_ 181 VFC_Obj02B_TTIPC_StdDev "Inverse TTI standard deviation";
CM_ SG_ 181 VFC_Obj02B_TTIPC "Inverse TTI";
CM_ SG_ 181 VFC_Obj02B_AngLongitude "angular velocity with regarding to longitudinal direction";
CM_ SG_ 181 VFC_Obj02B_CRC "CRC - Autosar E2E Profile 5";
CM_ SG_ 181 VFC_Obj02B_AliveCtr "Alive counter - Autosar E2E Profile 5";
CM_ SG_ 181 VFC_Obj02B_BlockCtr "Protocol-Signal: Block Counter";
CM_ SG_ 181 VFC_Obj02B_ScaleChange "A scale change of of the detected object";
CM_ SG_ 181 VFC_Obj02B_ScaleChngStdDev "Standard deviation of object scale change";
CM_ SG_ 181 VFC_Obj02B_LineEdgeRightEgo "ObjLineEdgeAngle refers to the line which limits the host vehicle lane on the right side";
CM_ SG_ 181 VFC_Obj02B_LineEdgeLeftEgo "ObjLineEdgeAngle refers to the line which limits the host vehicle lane on the left side";
CM_ SG_ 181 VFC_Obj02B_CompletelyInImg "indicator if the object is completely measrued in the image";
CM_ SG_ 181 VFC_Obj02B_DirIndicator "The detected direction indicator lights";
CM_ SG_ 181 VFC_Obj02B_LineEdgeAngle "Angle between the video object's edge and the lane marking";
CM_ SG_ 181 VFC_Obj02B_BrakeLight "The number of detected lights. More confident if more lights are detected.";
CM_ SG_ 181 VFC_Obj02B_MeasSource "Bitmask for the measurement programs from which this object originates";
CM_ SG_ 181 VFC_Obj02B_Reliab "Bitmask that indicates the algorithmic paths that have detected this object";
CM_ SG_ 182 VFC_Obj03A_CRC "CRC - Autosar E2E Profile 5";
CM_ SG_ 182 VFC_Obj03A_AliveCtr "Alive counter - Autosar E2E Profile 5";
CM_ SG_ 182 VFC_Obj03A_BlockCtr "Protocol-Signal: Block-Counter";
CM_ SG_ 182 VFC_Obj03A_ProtOrderIndex "Protocol-Signal: Index to ensure same order in Tx and Rx of the objects";
CM_ SG_ 182 VFC_Obj03A_Ax "Object Acceleration in longitudinal direction";
CM_ SG_ 182 VFC_Obj03A_Vx "Object Velocity in longitudinal direction";
CM_ SG_ 182 VFC_Obj03A_Dx "Object Position in longitudinal direction";
CM_ SG_ 182 VFC_Obj03A_Dy "Object Position in lateral direction";
CM_ SG_ 182 VFC_Obj03A_Vy "Object Velocity in lateral direction";
CM_ SG_ 182 VFC_Obj03A_Ay "Object Acceleration in lateral direction";
CM_ SG_ 182 VFC_Obj03A_DyStdDev "Standard deviation of Object position in lateral direction";
CM_ SG_ 182 VFC_Obj03A_DxStdDev "Standard deviation of Object position in longitudinal direction";
CM_ SG_ 182 VFC_Obj03A_VxStdDev "Standard deviation of Object velocity in longitudinal direction";
CM_ SG_ 182 VFC_Obj03A_ExistProb "Object existence probability";
CM_ SG_ 182 VFC_Obj03A_VyStdDev "Standard deviation of Object velocity in lateral direction";
CM_ SG_ 182 VFC_Obj03A_TypeProb "Probability of the classified object type";
CM_ SG_ 182 VFC_Obj03A_AxStdDev "Standard deviation of Object acceleration in longitudinal direction";
CM_ SG_ 182 VFC_Obj03A_AyStdDev "Standard deviation of Object acceleration in lateral direction";
CM_ SG_ 182 VFC_Obj03A_PhiLeft "ACCS Viewing Angle of left object edge(dimensionless)";
CM_ SG_ 182 VFC_Obj03A_ClassifiedView "The classified view of object to be used in connection with Heading angle";
CM_ SG_ 182 VFC_Obj03A_Length "Length of the object";
CM_ SG_ 182 VFC_Obj03A_WidthStdDev "Standard deviation of object width";
CM_ SG_ 182 VFC_Obj03A_Height "Height of the object";
CM_ SG_ 182 VFC_Obj03A_HeightStdDev "Standard deviation of object height";
CM_ SG_ 182 VFC_Obj03A_PhiLeftStdDev "Standard deviation of the ACCS angle of left object(dimensionless)";
CM_ SG_ 182 VFC_Obj03A_HeadingStdDev "Standard deviation of object Heading angle";
CM_ SG_ 182 VFC_Obj03A_Measured "Indicator if the object detected is measured or predicted.";
CM_ SG_ 182 VFC_Obj03A_Heading "Heading angle of the object";
CM_ SG_ 182 VFC_Obj03A_LengthStdDev "Standard deviation of object length";
CM_ SG_ 182 VFC_Obj03A_PhiMid "Viewing angle of the ACCS middle of the object(dimensionless)";
CM_ SG_ 182 VFC_Obj03A_Width "Width of the object";
CM_ SG_ 182 VFC_Obj03A_PhiMidStdDev "Standard deviation of the ACCS middle angle of object(dimensionless)";
CM_ SG_ 182 VFC_Obj03A_PhiRight "ACCS Viewing Angle of right object edge(dimensionless)";
CM_ SG_ 182 VFC_Obj03A_VisibleView "The visible view of the detectd object";
CM_ SG_ 182 VFC_Obj03A_PhiRightStdDev "Standard deviation of the ACCS angle of right object(dimensionless)";
CM_ SG_ 182 VFC_Obj03A_PhiLeftVel "Velocity of the ACCS viewing angle of the left edge";
CM_ SG_ 182 VFC_Obj03A_PhiRightVel "Velocity of the ACCS viewing angle of the right edge";
CM_ SG_ 182 VFC_Obj03A_PhiRightVelStdDev "Standard deviation of ACCS viewing angle velocity of right object edge from ego vehicle related to camera";
CM_ SG_ 182 VFC_Obj03A_PhiLeftVelStdDev "Standard deviation of ACCS viewing angle velocity of left object edge from ego vehicle related to camera";
CM_ SG_ 182 VFC_Obj03A_PhiTop "ACCS Viewing angle of the top of the object(dimensionless)";
CM_ SG_ 182 VFC_Obj03A_PhiBottom "ACCS Viewing angle of the bottom of the object(dimensionless)";
CM_ SG_ 182 VFC_Obj03A_PhiTopStdDev "Standard deviation  of the ACCS top angle of object(dimensionless)";
CM_ SG_ 182 VFC_Obj03A_HeadOrientation "The orientation of the head of cyclists or pedestrians that are detected.";
CM_ SG_ 182 VFC_Obj03A_Type "Classification of the object";
CM_ SG_ 182 VFC_Obj03A_PhiBottomStdDev "Standard deviation of the ACCS bottom angle of object(dimensionless)";
CM_ SG_ 182 VFC_Obj03A_NormVx "Normalised object velocity in longitudinal direction.";
CM_ SG_ 182 VFC_Obj03A_NormAx "Normalised object acceleration in longitudinal direction.";
CM_ SG_ 182 VFC_Obj03A_NormAxStdDev "Standard deviation of Normalized Object Acceleration in longitudinal direction";
CM_ SG_ 182 VFC_Obj03A_ProbMovingLat "Probability of object moving laterally";
CM_ SG_ 182 VFC_Obj03A_ID "Unique Object ID";
CM_ SG_ 182 VFC_Obj03A_NormVxStdDev "Standard deviation of Normalized Object Velocity in longitudinal direction";
CM_ SG_ 182 VFC_Obj03A_ProbMovingLong "Probability of object moving longitudinally";
CM_ SG_ 183 VFC_Obj03B_TTIPC_StdDev "Inverse TTI standard deviation";
CM_ SG_ 183 VFC_Obj03B_TTIPC "Inverse TTI";
CM_ SG_ 183 VFC_Obj03B_AngLongitude "angular velocity with regarding to longitudinal direction";
CM_ SG_ 183 VFC_Obj03B_CRC "CRC - Autosar E2E Profile 5";
CM_ SG_ 183 VFC_Obj03B_AliveCtr "Alive counter - Autosar E2E Profile 5";
CM_ SG_ 183 VFC_Obj03B_BlockCtr "Protocol-Signal: Block Counter";
CM_ SG_ 183 VFC_Obj03B_ScaleChange "A scale change of of the detected object";
CM_ SG_ 183 VFC_Obj03B_ScaleChngStdDev "Standard deviation of object scale change";
CM_ SG_ 183 VFC_Obj03B_LineEdgeRightEgo "ObjLineEdgeAngle refers to the line which limits the host vehicle lane on the right side";
CM_ SG_ 183 VFC_Obj03B_LineEdgeLeftEgo "ObjLineEdgeAngle refers to the line which limits the host vehicle lane on the left side";
CM_ SG_ 183 VFC_Obj03B_CompletelyInImg "indicator if the object is completely measrued in the image";
CM_ SG_ 183 VFC_Obj03B_DirIndicator "The detected direction indicator lights";
CM_ SG_ 183 VFC_Obj03B_LineEdgeAngle "Angle between the video object's edge and the lane marking";
CM_ SG_ 183 VFC_Obj03B_BrakeLight "The number of detected lights. More confident if more lights are detected.";
CM_ SG_ 183 VFC_Obj03B_MeasSource "Bitmask for the measurement programs from which this object originates";
CM_ SG_ 183 VFC_Obj03B_Reliab "Bitmask that indicates the algorithmic paths that have detected this object";
CM_ SG_ 184 VFC_Obj04A_CRC "CRC - Autosar E2E Profile 5";
CM_ SG_ 184 VFC_Obj04A_AliveCtr "Alive counter - Autosar E2E Profile 5";
CM_ SG_ 184 VFC_Obj04A_BlockCtr "Protocol-Signal: Block-Counter";
CM_ SG_ 184 VFC_Obj04A_ProtOrderIndex "Protocol-Signal: Index to ensure same order in Tx and Rx of the objects";
CM_ SG_ 184 VFC_Obj04A_Ax "Object Acceleration in longitudinal direction";
CM_ SG_ 184 VFC_Obj04A_Vx "Object Velocity in longitudinal direction";
CM_ SG_ 184 VFC_Obj04A_Dx "Object Position in longitudinal direction";
CM_ SG_ 184 VFC_Obj04A_Dy "Object Position in lateral direction";
CM_ SG_ 184 VFC_Obj04A_Vy "Object Velocity in lateral direction";
CM_ SG_ 184 VFC_Obj04A_Ay "Object Acceleration in lateral direction";
CM_ SG_ 184 VFC_Obj04A_DyStdDev "Standard deviation of Object position in lateral direction";
CM_ SG_ 184 VFC_Obj04A_DxStdDev "Standard deviation of Object position in longitudinal direction";
CM_ SG_ 184 VFC_Obj04A_VxStdDev "Standard deviation of Object velocity in longitudinal direction";
CM_ SG_ 184 VFC_Obj04A_ExistProb "Object existence probability";
CM_ SG_ 184 VFC_Obj04A_VyStdDev "Standard deviation of Object velocity in lateral direction";
CM_ SG_ 184 VFC_Obj04A_TypeProb "Probability of the classified object type";
CM_ SG_ 184 VFC_Obj04A_AxStdDev "Standard deviation of Object acceleration in longitudinal direction";
CM_ SG_ 184 VFC_Obj04A_AyStdDev "Standard deviation of Object acceleration in lateral direction";
CM_ SG_ 184 VFC_Obj04A_PhiLeft "ACCS Viewing Angle of left object edge(dimensionless)";
CM_ SG_ 184 VFC_Obj04A_ClassifiedView "The classified view of object to be used in connection with Heading angle";
CM_ SG_ 184 VFC_Obj04A_Length "Length of the object";
CM_ SG_ 184 VFC_Obj04A_WidthStdDev "Standard deviation of object width";
CM_ SG_ 184 VFC_Obj04A_Height "Height of the object";
CM_ SG_ 184 VFC_Obj04A_HeightStdDev "Standard deviation of object height";
CM_ SG_ 184 VFC_Obj04A_PhiLeftStdDev "Standard deviation of the ACCS angle of left object(dimensionless)";
CM_ SG_ 184 VFC_Obj04A_HeadingStdDev "Standard deviation of object Heading angle";
CM_ SG_ 184 VFC_Obj04A_Measured "Indicator if the object detected is measured or predicted.";
CM_ SG_ 184 VFC_Obj04A_Heading "Heading angle of the object";
CM_ SG_ 184 VFC_Obj04A_LengthStdDev "Standard deviation of object length";
CM_ SG_ 184 VFC_Obj04A_PhiMid "Viewing angle of the ACCS middle of the object(dimensionless)";
CM_ SG_ 184 VFC_Obj04A_Width "Width of the object";
CM_ SG_ 184 VFC_Obj04A_PhiMidStdDev "Standard deviation of the ACCS middle angle of object(dimensionless)";
CM_ SG_ 184 VFC_Obj04A_PhiRight "ACCS Viewing Angle of right object edge(dimensionless)";
CM_ SG_ 184 VFC_Obj04A_VisibleView "The visible view of the detectd object";
CM_ SG_ 184 VFC_Obj04A_PhiRightStdDev "Standard deviation of the ACCS angle of right object(dimensionless)";
CM_ SG_ 184 VFC_Obj04A_PhiLeftVel "Velocity of the ACCS viewing angle of the left edge";
CM_ SG_ 184 VFC_Obj04A_PhiRightVel "Velocity of the ACCS viewing angle of the right edge";
CM_ SG_ 184 VFC_Obj04A_PhiRightVelStdDev "Standard deviation of ACCS viewing angle velocity of right object edge from ego vehicle related to camera";
CM_ SG_ 184 VFC_Obj04A_PhiLeftVelStdDev "Standard deviation of ACCS viewing angle velocity of left object edge from ego vehicle related to camera";
CM_ SG_ 184 VFC_Obj04A_PhiTop "ACCS Viewing angle of the top of the object(dimensionless)";
CM_ SG_ 184 VFC_Obj04A_PhiBottom "ACCS Viewing angle of the bottom of the object(dimensionless)";
CM_ SG_ 184 VFC_Obj04A_PhiTopStdDev "Standard deviation  of the ACCS top angle of object(dimensionless)";
CM_ SG_ 184 VFC_Obj04A_HeadOrientation "The orientation of the head of cyclists or pedestrians that are detected.";
CM_ SG_ 184 VFC_Obj04A_Type "Classification of the object";
CM_ SG_ 184 VFC_Obj04A_PhiBottomStdDev "Standard deviation of the ACCS bottom angle of object(dimensionless)";
CM_ SG_ 184 VFC_Obj04A_NormVx "Normalised object velocity in longitudinal direction.";
CM_ SG_ 184 VFC_Obj04A_NormAx "Normalised object acceleration in longitudinal direction.";
CM_ SG_ 184 VFC_Obj04A_NormAxStdDev "Standard deviation of Normalized Object Acceleration in longitudinal direction";
CM_ SG_ 184 VFC_Obj04A_ProbMovingLat "Probability of object moving laterally";
CM_ SG_ 184 VFC_Obj04A_ID "Unique Object ID";
CM_ SG_ 184 VFC_Obj04A_NormVxStdDev "Standard deviation of Normalized Object Velocity in longitudinal direction";
CM_ SG_ 184 VFC_Obj04A_ProbMovingLong "Probability of object moving longitudinally";
CM_ SG_ 185 VFC_Obj04B_TTIPC_StdDev "Inverse TTI standard deviation";
CM_ SG_ 185 VFC_Obj04B_TTIPC "Inverse TTI";
CM_ SG_ 185 VFC_Obj04B_AngLongitude "angular velocity with regarding to longitudinal direction";
CM_ SG_ 185 VFC_Obj04B_CRC "CRC - Autosar E2E Profile 5";
CM_ SG_ 185 VFC_Obj04B_AliveCtr "Alive counter - Autosar E2E Profile 5";
CM_ SG_ 185 VFC_Obj04B_BlockCtr "Protocol-Signal: Block Counter";
CM_ SG_ 185 VFC_Obj04B_ScaleChange "A scale change of of the detected object";
CM_ SG_ 185 VFC_Obj04B_ScaleChngStdDev "Standard deviation of object scale change";
CM_ SG_ 185 VFC_Obj04B_LineEdgeRightEgo "ObjLineEdgeAngle refers to the line which limits the host vehicle lane on the right side";
CM_ SG_ 185 VFC_Obj04B_LineEdgeLeftEgo "ObjLineEdgeAngle refers to the line which limits the host vehicle lane on the left side";
CM_ SG_ 185 VFC_Obj04B_CompletelyInImg "indicator if the object is completely measrued in the image";
CM_ SG_ 185 VFC_Obj04B_DirIndicator "The detected direction indicator lights";
CM_ SG_ 185 VFC_Obj04B_LineEdgeAngle "Angle between the video object's edge and the lane marking";
CM_ SG_ 185 VFC_Obj04B_BrakeLight "The number of detected lights. More confident if more lights are detected.";
CM_ SG_ 185 VFC_Obj04B_MeasSource "Bitmask for the measurement programs from which this object originates";
CM_ SG_ 185 VFC_Obj04B_Reliab "Bitmask that indicates the algorithmic paths that have detected this object";
CM_ SG_ 186 VFC_Obj05A_CRC "CRC - Autosar E2E Profile 5";
CM_ SG_ 186 VFC_Obj05A_AliveCtr "Alive counter - Autosar E2E Profile 5";
CM_ SG_ 186 VFC_Obj05A_BlockCtr "Protocol-Signal: Block-Counter";
CM_ SG_ 186 VFC_Obj05A_ProtOrderIndex "Protocol-Signal: Index to ensure same order in Tx and Rx of the objects";
CM_ SG_ 186 VFC_Obj05A_Ax "Object Acceleration in longitudinal direction";
CM_ SG_ 186 VFC_Obj05A_Vx "Object Velocity in longitudinal direction";
CM_ SG_ 186 VFC_Obj05A_Dx "Object Position in longitudinal direction";
CM_ SG_ 186 VFC_Obj05A_Dy "Object Position in lateral direction";
CM_ SG_ 186 VFC_Obj05A_Vy "Object Velocity in lateral direction";
CM_ SG_ 186 VFC_Obj05A_Ay "Object Acceleration in lateral direction";
CM_ SG_ 186 VFC_Obj05A_DyStdDev "Standard deviation of Object position in lateral direction";
CM_ SG_ 186 VFC_Obj05A_DxStdDev "Standard deviation of Object position in longitudinal direction";
CM_ SG_ 186 VFC_Obj05A_VxStdDev "Standard deviation of Object velocity in longitudinal direction";
CM_ SG_ 186 VFC_Obj05A_ExistProb "Object existence probability";
CM_ SG_ 186 VFC_Obj05A_VyStdDev "Standard deviation of Object velocity in lateral direction";
CM_ SG_ 186 VFC_Obj05A_TypeProb "Probability of the classified object type";
CM_ SG_ 186 VFC_Obj05A_AxStdDev "Standard deviation of Object acceleration in longitudinal direction";
CM_ SG_ 186 VFC_Obj05A_AyStdDev "Standard deviation of Object acceleration in lateral direction";
CM_ SG_ 186 VFC_Obj05A_PhiLeft "ACCS Viewing Angle of left object edge(dimensionless)";
CM_ SG_ 186 VFC_Obj05A_ClassifiedView "The classified view of object to be used in connection with Heading angle";
CM_ SG_ 186 VFC_Obj05A_Length "Length of the object";
CM_ SG_ 186 VFC_Obj05A_WidthStdDev "Standard deviation of object width";
CM_ SG_ 186 VFC_Obj05A_Height "Height of the object";
CM_ SG_ 186 VFC_Obj05A_HeightStdDev "Standard deviation of object height";
CM_ SG_ 186 VFC_Obj05A_PhiLeftStdDev "Standard deviation of the ACCS angle of left object(dimensionless)";
CM_ SG_ 186 VFC_Obj05A_HeadingStdDev "Standard deviation of object Heading angle";
CM_ SG_ 186 VFC_Obj05A_Measured "Indicator if the object detected is measured or predicted.";
CM_ SG_ 186 VFC_Obj05A_Heading "Heading angle of the object";
CM_ SG_ 186 VFC_Obj05A_LengthStdDev "Standard deviation of object length";
CM_ SG_ 186 VFC_Obj05A_PhiMid "Viewing angle of the ACCS middle of the object(dimensionless)";
CM_ SG_ 186 VFC_Obj05A_Width "Width of the object";
CM_ SG_ 186 VFC_Obj05A_PhiMidStdDev "Standard deviation of the ACCS middle angle of object(dimensionless)";
CM_ SG_ 186 VFC_Obj05A_PhiRight "ACCS Viewing Angle of right object edge(dimensionless)";
CM_ SG_ 186 VFC_Obj05A_VisibleView "The visible view of the detectd object";
CM_ SG_ 186 VFC_Obj05A_PhiRightStdDev "Standard deviation of the ACCS angle of right object(dimensionless)";
CM_ SG_ 186 VFC_Obj05A_PhiLeftVel "Velocity of the ACCS viewing angle of the left edge";
CM_ SG_ 186 VFC_Obj05A_PhiRightVel "Velocity of the ACCS viewing angle of the right edge";
CM_ SG_ 186 VFC_Obj05A_PhiRightVelStdDev "Standard deviation of ACCS viewing angle velocity of right object edge from ego vehicle related to camera";
CM_ SG_ 186 VFC_Obj05A_PhiLeftVelStdDev "Standard deviation of ACCS viewing angle velocity of left object edge from ego vehicle related to camera";
CM_ SG_ 186 VFC_Obj05A_PhiTop "ACCS Viewing angle of the top of the object(dimensionless)";
CM_ SG_ 186 VFC_Obj05A_PhiBottom "ACCS Viewing angle of the bottom of the object(dimensionless)";
CM_ SG_ 186 VFC_Obj05A_PhiTopStdDev "Standard deviation  of the ACCS top angle of object(dimensionless)";
CM_ SG_ 186 VFC_Obj05A_HeadOrientation "The orientation of the head of cyclists or pedestrians that are detected.";
CM_ SG_ 186 VFC_Obj05A_Type "Classification of the object";
CM_ SG_ 186 VFC_Obj05A_PhiBottomStdDev "Standard deviation of the ACCS bottom angle of object(dimensionless)";
CM_ SG_ 186 VFC_Obj05A_NormVx "Normalised object velocity in longitudinal direction.";
CM_ SG_ 186 VFC_Obj05A_NormAx "Normalised object acceleration in longitudinal direction.";
CM_ SG_ 186 VFC_Obj05A_NormAxStdDev "Standard deviation of Normalized Object Acceleration in longitudinal direction";
CM_ SG_ 186 VFC_Obj05A_ProbMovingLat "Probability of object moving laterally";
CM_ SG_ 186 VFC_Obj05A_ID "Unique Object ID";
CM_ SG_ 186 VFC_Obj05A_NormVxStdDev "Standard deviation of Normalized Object Velocity in longitudinal direction";
CM_ SG_ 186 VFC_Obj05A_ProbMovingLong "Probability of object moving longitudinally";
CM_ SG_ 187 VFC_Obj05B_TTIPC_StdDev "Inverse TTI standard deviation";
CM_ SG_ 187 VFC_Obj05B_TTIPC "Inverse TTI";
CM_ SG_ 187 VFC_Obj05B_AngLongitude "angular velocity with regarding to longitudinal direction";
CM_ SG_ 187 VFC_Obj05B_CRC "CRC - Autosar E2E Profile 5";
CM_ SG_ 187 VFC_Obj05B_AliveCtr "Alive counter - Autosar E2E Profile 5";
CM_ SG_ 187 VFC_Obj05B_BlockCtr "Protocol-Signal: Block Counter";
CM_ SG_ 187 VFC_Obj05B_ScaleChange "A scale change of of the detected object";
CM_ SG_ 187 VFC_Obj05B_ScaleChngStdDev "Standard deviation of object scale change";
CM_ SG_ 187 VFC_Obj05B_LineEdgeRightEgo "ObjLineEdgeAngle refers to the line which limits the host vehicle lane on the right side";
CM_ SG_ 187 VFC_Obj05B_LineEdgeLeftEgo "ObjLineEdgeAngle refers to the line which limits the host vehicle lane on the left side";
CM_ SG_ 187 VFC_Obj05B_CompletelyInImg "indicator if the object is completely measrued in the image";
CM_ SG_ 187 VFC_Obj05B_DirIndicator "The detected direction indicator lights";
CM_ SG_ 187 VFC_Obj05B_LineEdgeAngle "Angle between the video object's edge and the lane marking";
CM_ SG_ 187 VFC_Obj05B_BrakeLight "The number of detected lights. More confident if more lights are detected.";
CM_ SG_ 187 VFC_Obj05B_MeasSource "Bitmask for the measurement programs from which this object originates";
CM_ SG_ 187 VFC_Obj05B_Reliab "Bitmask that indicates the algorithmic paths that have detected this object";
CM_ SG_ 188 VFC_Obj06A_CRC "CRC - Autosar E2E Profile 5";
CM_ SG_ 188 VFC_Obj06A_AliveCtr "Alive counter - Autosar E2E Profile 5";
CM_ SG_ 188 VFC_Obj06A_BlockCtr "Protocol-Signal: Block-Counter";
CM_ SG_ 188 VFC_Obj06A_ProtOrderIndex "Protocol-Signal: Index to ensure same order in Tx and Rx of the objects";
CM_ SG_ 188 VFC_Obj06A_Ax "Object Acceleration in longitudinal direction";
CM_ SG_ 188 VFC_Obj06A_Vx "Object Velocity in longitudinal direction";
CM_ SG_ 188 VFC_Obj06A_Dx "Object Position in longitudinal direction";
CM_ SG_ 188 VFC_Obj06A_Dy "Object Position in lateral direction";
CM_ SG_ 188 VFC_Obj06A_Vy "Object Velocity in lateral direction";
CM_ SG_ 188 VFC_Obj06A_Ay "Object Acceleration in lateral direction";
CM_ SG_ 188 VFC_Obj06A_DyStdDev "Standard deviation of Object position in lateral direction";
CM_ SG_ 188 VFC_Obj06A_DxStdDev "Standard deviation of Object position in longitudinal direction";
CM_ SG_ 188 VFC_Obj06A_VxStdDev "Standard deviation of Object velocity in longitudinal direction";
CM_ SG_ 188 VFC_Obj06A_ExistProb "Object existence probability";
CM_ SG_ 188 VFC_Obj06A_VyStdDev "Standard deviation of Object velocity in lateral direction";
CM_ SG_ 188 VFC_Obj06A_TypeProb "Probability of the classified object type";
CM_ SG_ 188 VFC_Obj06A_AxStdDev "Standard deviation of Object acceleration in longitudinal direction";
CM_ SG_ 188 VFC_Obj06A_AyStdDev "Standard deviation of Object acceleration in lateral direction";
CM_ SG_ 188 VFC_Obj06A_PhiLeft "ACCS Viewing Angle of left object edge(dimensionless)";
CM_ SG_ 188 VFC_Obj06A_ClassifiedView "The classified view of object to be used in connection with Heading angle";
CM_ SG_ 188 VFC_Obj06A_Length "Length of the object";
CM_ SG_ 188 VFC_Obj06A_WidthStdDev "Standard deviation of object width";
CM_ SG_ 188 VFC_Obj06A_Height "Height of the object";
CM_ SG_ 188 VFC_Obj06A_HeightStdDev "Standard deviation of object height";
CM_ SG_ 188 VFC_Obj06A_PhiLeftStdDev "Standard deviation of the ACCS angle of left object(dimensionless)";
CM_ SG_ 188 VFC_Obj06A_HeadingStdDev "Standard deviation of object Heading angle";
CM_ SG_ 188 VFC_Obj06A_Measured "Indicator if the object detected is measured or predicted.";
CM_ SG_ 188 VFC_Obj06A_Heading "Heading angle of the object";
CM_ SG_ 188 VFC_Obj06A_LengthStdDev "Standard deviation of object length";
CM_ SG_ 188 VFC_Obj06A_PhiMid "Viewing angle of the ACCS middle of the object(dimensionless)";
CM_ SG_ 188 VFC_Obj06A_Width "Width of the object";
CM_ SG_ 188 VFC_Obj06A_PhiMidStdDev "Standard deviation of the ACCS middle angle of object(dimensionless)";
CM_ SG_ 188 VFC_Obj06A_PhiRight "ACCS Viewing Angle of right object edge(dimensionless)";
CM_ SG_ 188 VFC_Obj06A_VisibleView "The visible view of the detectd object";
CM_ SG_ 188 VFC_Obj06A_PhiRightStdDev "Standard deviation of the ACCS angle of right object(dimensionless)";
CM_ SG_ 188 VFC_Obj06A_PhiLeftVel "Velocity of the ACCS viewing angle of the left edge";
CM_ SG_ 188 VFC_Obj06A_PhiRightVel "Velocity of the ACCS viewing angle of the right edge";
CM_ SG_ 188 VFC_Obj06A_PhiRightVelStdDev "Standard deviation of ACCS viewing angle velocity of right object edge from ego vehicle related to camera";
CM_ SG_ 188 VFC_Obj06A_PhiLeftVelStdDev "Standard deviation of ACCS viewing angle velocity of left object edge from ego vehicle related to camera";
CM_ SG_ 188 VFC_Obj06A_PhiTop "ACCS Viewing angle of the top of the object(dimensionless)";
CM_ SG_ 188 VFC_Obj06A_PhiBottom "ACCS Viewing angle of the bottom of the object(dimensionless)";
CM_ SG_ 188 VFC_Obj06A_PhiTopStdDev "Standard deviation  of the ACCS top angle of object(dimensionless)";
CM_ SG_ 188 VFC_Obj06A_HeadOrientation "The orientation of the head of cyclists or pedestrians that are detected.";
CM_ SG_ 188 VFC_Obj06A_Type "Classification of the object";
CM_ SG_ 188 VFC_Obj06A_PhiBottomStdDev "Standard deviation of the ACCS bottom angle of object(dimensionless)";
CM_ SG_ 188 VFC_Obj06A_NormVx "Normalised object velocity in longitudinal direction.";
CM_ SG_ 188 VFC_Obj06A_NormAx "Normalised object acceleration in longitudinal direction.";
CM_ SG_ 188 VFC_Obj06A_NormAxStdDev "Standard deviation of Normalized Object Acceleration in longitudinal direction";
CM_ SG_ 188 VFC_Obj06A_ProbMovingLat "Probability of object moving laterally";
CM_ SG_ 188 VFC_Obj06A_ID "Unique Object ID";
CM_ SG_ 188 VFC_Obj06A_NormVxStdDev "Standard deviation of Normalized Object Velocity in longitudinal direction";
CM_ SG_ 188 VFC_Obj06A_ProbMovingLong "Probability of object moving longitudinally";
CM_ SG_ 189 VFC_Obj06B_TTIPC_StdDev "Inverse TTI standard deviation";
CM_ SG_ 189 VFC_Obj06B_TTIPC "Inverse TTI";
CM_ SG_ 189 VFC_Obj06B_AngLongitude "angular velocity with regarding to longitudinal direction";
CM_ SG_ 189 VFC_Obj06B_CRC "CRC - Autosar E2E Profile 5";
CM_ SG_ 189 VFC_Obj06B_AliveCtr "Alive counter - Autosar E2E Profile 5";
CM_ SG_ 189 VFC_Obj06B_BlockCtr "Protocol-Signal: Block Counter";
CM_ SG_ 189 VFC_Obj06B_ScaleChange "A scale change of of the detected object";
CM_ SG_ 189 VFC_Obj06B_ScaleChngStdDev "Standard deviation of object scale change";
CM_ SG_ 189 VFC_Obj06B_LineEdgeRightEgo "ObjLineEdgeAngle refers to the line which limits the host vehicle lane on the right side";
CM_ SG_ 189 VFC_Obj06B_LineEdgeLeftEgo "ObjLineEdgeAngle refers to the line which limits the host vehicle lane on the left side";
CM_ SG_ 189 VFC_Obj06B_CompletelyInImg "indicator if the object is completely measrued in the image";
CM_ SG_ 189 VFC_Obj06B_DirIndicator "The detected direction indicator lights";
CM_ SG_ 189 VFC_Obj06B_LineEdgeAngle "Angle between the video object's edge and the lane marking";
CM_ SG_ 189 VFC_Obj06B_BrakeLight "The number of detected lights. More confident if more lights are detected.";
CM_ SG_ 189 VFC_Obj06B_MeasSource "Bitmask for the measurement programs from which this object originates";
CM_ SG_ 189 VFC_Obj06B_Reliab "Bitmask that indicates the algorithmic paths that have detected this object";
CM_ SG_ 190 VFC_Obj07A_CRC "CRC - Autosar E2E Profile 5";
CM_ SG_ 190 VFC_Obj07A_AliveCtr "Alive counter - Autosar E2E Profile 5";
CM_ SG_ 190 VFC_Obj07A_BlockCtr "Protocol-Signal: Block-Counter";
CM_ SG_ 190 VFC_Obj07A_ProtOrderIndex "Protocol-Signal: Index to ensure same order in Tx and Rx of the objects";
CM_ SG_ 190 VFC_Obj07A_Ax "Object Acceleration in longitudinal direction";
CM_ SG_ 190 VFC_Obj07A_Vx "Object Velocity in longitudinal direction";
CM_ SG_ 190 VFC_Obj07A_Dx "Object Position in longitudinal direction";
CM_ SG_ 190 VFC_Obj07A_Dy "Object Position in lateral direction";
CM_ SG_ 190 VFC_Obj07A_Vy "Object Velocity in lateral direction";
CM_ SG_ 190 VFC_Obj07A_Ay "Object Acceleration in lateral direction";
CM_ SG_ 190 VFC_Obj07A_DyStdDev "Standard deviation of Object position in lateral direction";
CM_ SG_ 190 VFC_Obj07A_DxStdDev "Standard deviation of Object position in longitudinal direction";
CM_ SG_ 190 VFC_Obj07A_VxStdDev "Standard deviation of Object velocity in longitudinal direction";
CM_ SG_ 190 VFC_Obj07A_ExistProb "Object existence probability";
CM_ SG_ 190 VFC_Obj07A_VyStdDev "Standard deviation of Object velocity in lateral direction";
CM_ SG_ 190 VFC_Obj07A_TypeProb "Probability of the classified object type";
CM_ SG_ 190 VFC_Obj07A_AxStdDev "Standard deviation of Object acceleration in longitudinal direction";
CM_ SG_ 190 VFC_Obj07A_AyStdDev "Standard deviation of Object acceleration in lateral direction";
CM_ SG_ 190 VFC_Obj07A_PhiLeft "ACCS Viewing Angle of left object edge(dimensionless)";
CM_ SG_ 190 VFC_Obj07A_ClassifiedView "The classified view of object to be used in connection with Heading angle";
CM_ SG_ 190 VFC_Obj07A_Length "Length of the object";
CM_ SG_ 190 VFC_Obj07A_WidthStdDev "Standard deviation of object width";
CM_ SG_ 190 VFC_Obj07A_Height "Height of the object";
CM_ SG_ 190 VFC_Obj07A_HeightStdDev "Standard deviation of object height";
CM_ SG_ 190 VFC_Obj07A_PhiLeftStdDev "Standard deviation of the ACCS angle of left object(dimensionless)";
CM_ SG_ 190 VFC_Obj07A_HeadingStdDev "Standard deviation of object Heading angle";
CM_ SG_ 190 VFC_Obj07A_Measured "Indicator if the object detected is measured or predicted.";
CM_ SG_ 190 VFC_Obj07A_Heading "Heading angle of the object";
CM_ SG_ 190 VFC_Obj07A_LengthStdDev "Standard deviation of object length";
CM_ SG_ 190 VFC_Obj07A_PhiMid "Viewing angle of the ACCS middle of the object(dimensionless)";
CM_ SG_ 190 VFC_Obj07A_Width "Width of the object";
CM_ SG_ 190 VFC_Obj07A_PhiMidStdDev "Standard deviation of the ACCS middle angle of object(dimensionless)";
CM_ SG_ 190 VFC_Obj07A_PhiRight "ACCS Viewing Angle of right object edge(dimensionless)";
CM_ SG_ 190 VFC_Obj07A_VisibleView "The visible view of the detectd object";
CM_ SG_ 190 VFC_Obj07A_PhiRightStdDev "Standard deviation of the ACCS angle of right object(dimensionless)";
CM_ SG_ 190 VFC_Obj07A_PhiLeftVel "Velocity of the ACCS viewing angle of the left edge";
CM_ SG_ 190 VFC_Obj07A_PhiRightVel "Velocity of the ACCS viewing angle of the right edge";
CM_ SG_ 190 VFC_Obj07A_PhiRightVelStdDev "Standard deviation of ACCS viewing angle velocity of right object edge from ego vehicle related to camera";
CM_ SG_ 190 VFC_Obj07A_PhiLeftVelStdDev "Standard deviation of ACCS viewing angle velocity of left object edge from ego vehicle related to camera";
CM_ SG_ 190 VFC_Obj07A_PhiTop "ACCS Viewing angle of the top of the object(dimensionless)";
CM_ SG_ 190 VFC_Obj07A_PhiBottom "ACCS Viewing angle of the bottom of the object(dimensionless)";
CM_ SG_ 190 VFC_Obj07A_PhiTopStdDev "Standard deviation  of the ACCS top angle of object(dimensionless)";
CM_ SG_ 190 VFC_Obj07A_HeadOrientation "The orientation of the head of cyclists or pedestrians that are detected.";
CM_ SG_ 190 VFC_Obj07A_Type "Classification of the object";
CM_ SG_ 190 VFC_Obj07A_PhiBottomStdDev "Standard deviation of the ACCS bottom angle of object(dimensionless)";
CM_ SG_ 190 VFC_Obj07A_NormVx "Normalised object velocity in longitudinal direction.";
CM_ SG_ 190 VFC_Obj07A_NormAx "Normalised object acceleration in longitudinal direction.";
CM_ SG_ 190 VFC_Obj07A_NormAxStdDev "Standard deviation of Normalized Object Acceleration in longitudinal direction";
CM_ SG_ 190 VFC_Obj07A_ProbMovingLat "Probability of object moving laterally";
CM_ SG_ 190 VFC_Obj07A_ID "Unique Object ID";
CM_ SG_ 190 VFC_Obj07A_NormVxStdDev "Standard deviation of Normalized Object Velocity in longitudinal direction";
CM_ SG_ 190 VFC_Obj07A_ProbMovingLong "Probability of object moving longitudinally";
CM_ SG_ 191 VFC_Obj07B_TTIPC_StdDev "Inverse TTI standard deviation";
CM_ SG_ 191 VFC_Obj07B_TTIPC "Inverse TTI";
CM_ SG_ 191 VFC_Obj07B_AngLongitude "angular velocity with regarding to longitudinal direction";
CM_ SG_ 191 VFC_Obj07B_CRC "CRC - Autosar E2E Profile 5";
CM_ SG_ 191 VFC_Obj07B_AliveCtr "Alive counter - Autosar E2E Profile 5";
CM_ SG_ 191 VFC_Obj07B_BlockCtr "Protocol-Signal: Block Counter";
CM_ SG_ 191 VFC_Obj07B_ScaleChange "A scale change of of the detected object";
CM_ SG_ 191 VFC_Obj07B_ScaleChngStdDev "Standard deviation of object scale change";
CM_ SG_ 191 VFC_Obj07B_LineEdgeRightEgo "ObjLineEdgeAngle refers to the line which limits the host vehicle lane on the right side";
CM_ SG_ 191 VFC_Obj07B_LineEdgeLeftEgo "ObjLineEdgeAngle refers to the line which limits the host vehicle lane on the left side";
CM_ SG_ 191 VFC_Obj07B_CompletelyInImg "indicator if the object is completely measrued in the image";
CM_ SG_ 191 VFC_Obj07B_DirIndicator "The detected direction indicator lights";
CM_ SG_ 191 VFC_Obj07B_LineEdgeAngle "Angle between the video object's edge and the lane marking";
CM_ SG_ 191 VFC_Obj07B_BrakeLight "The number of detected lights. More confident if more lights are detected.";
CM_ SG_ 191 VFC_Obj07B_MeasSource "Bitmask for the measurement programs from which this object originates";
CM_ SG_ 191 VFC_Obj07B_Reliab "Bitmask that indicates the algorithmic paths that have detected this object";
CM_ SG_ 192 VFC_Obj08A_CRC "CRC - Autosar E2E Profile 5";
CM_ SG_ 192 VFC_Obj08A_AliveCtr "Alive counter - Autosar E2E Profile 5";
CM_ SG_ 192 VFC_Obj08A_BlockCtr "Protocol-Signal: Block-Counter";
CM_ SG_ 192 VFC_Obj08A_ProtOrderIndex "Protocol-Signal: Index to ensure same order in Tx and Rx of the objects";
CM_ SG_ 192 VFC_Obj08A_Ax "Object Acceleration in longitudinal direction";
CM_ SG_ 192 VFC_Obj08A_Vx "Object Velocity in longitudinal direction";
CM_ SG_ 192 VFC_Obj08A_Dx "Object Position in longitudinal direction";
CM_ SG_ 192 VFC_Obj08A_Dy "Object Position in lateral direction";
CM_ SG_ 192 VFC_Obj08A_Vy "Object Velocity in lateral direction";
CM_ SG_ 192 VFC_Obj08A_Ay "Object Acceleration in lateral direction";
CM_ SG_ 192 VFC_Obj08A_DyStdDev "Standard deviation of Object position in lateral direction";
CM_ SG_ 192 VFC_Obj08A_DxStdDev "Standard deviation of Object position in longitudinal direction";
CM_ SG_ 192 VFC_Obj08A_VxStdDev "Standard deviation of Object velocity in longitudinal direction";
CM_ SG_ 192 VFC_Obj08A_ExistProb "Object existence probability";
CM_ SG_ 192 VFC_Obj08A_VyStdDev "Standard deviation of Object velocity in lateral direction";
CM_ SG_ 192 VFC_Obj08A_TypeProb "Probability of the classified object type";
CM_ SG_ 192 VFC_Obj08A_AxStdDev "Standard deviation of Object acceleration in longitudinal direction";
CM_ SG_ 192 VFC_Obj08A_AyStdDev "Standard deviation of Object acceleration in lateral direction";
CM_ SG_ 192 VFC_Obj08A_PhiLeft "ACCS Viewing Angle of left object edge(dimensionless)";
CM_ SG_ 192 VFC_Obj08A_ClassifiedView "The classified view of object to be used in connection with Heading angle";
CM_ SG_ 192 VFC_Obj08A_Length "Length of the object";
CM_ SG_ 192 VFC_Obj08A_WidthStdDev "Standard deviation of object width";
CM_ SG_ 192 VFC_Obj08A_Height "Height of the object";
CM_ SG_ 192 VFC_Obj08A_HeightStdDev "Standard deviation of object height";
CM_ SG_ 192 VFC_Obj08A_PhiLeftStdDev "Standard deviation of the ACCS angle of left object(dimensionless)";
CM_ SG_ 192 VFC_Obj08A_HeadingStdDev "Standard deviation of object Heading angle";
CM_ SG_ 192 VFC_Obj08A_Measured "Indicator if the object detected is measured or predicted.";
CM_ SG_ 192 VFC_Obj08A_Heading "Heading angle of the object";
CM_ SG_ 192 VFC_Obj08A_LengthStdDev "Standard deviation of object length";
CM_ SG_ 192 VFC_Obj08A_PhiMid "Viewing angle of the ACCS middle of the object(dimensionless)";
CM_ SG_ 192 VFC_Obj08A_Width "Width of the object";
CM_ SG_ 192 VFC_Obj08A_PhiMidStdDev "Standard deviation of the ACCS middle angle of object(dimensionless)";
CM_ SG_ 192 VFC_Obj08A_PhiRight "ACCS Viewing Angle of right object edge(dimensionless)";
CM_ SG_ 192 VFC_Obj08A_VisibleView "The visible view of the detectd object";
CM_ SG_ 192 VFC_Obj08A_PhiRightStdDev "Standard deviation of the ACCS angle of right object(dimensionless)";
CM_ SG_ 192 VFC_Obj08A_PhiLeftVel "Velocity of the ACCS viewing angle of the left edge";
CM_ SG_ 192 VFC_Obj08A_PhiRightVel "Velocity of the ACCS viewing angle of the right edge";
CM_ SG_ 192 VFC_Obj08A_PhiRightVelStdDev "Standard deviation of ACCS viewing angle velocity of right object edge from ego vehicle related to camera";
CM_ SG_ 192 VFC_Obj08A_PhiLeftVelStdDev "Standard deviation of ACCS viewing angle velocity of left object edge from ego vehicle related to camera";
CM_ SG_ 192 VFC_Obj08A_PhiTop "ACCS Viewing angle of the top of the object(dimensionless)";
CM_ SG_ 192 VFC_Obj08A_PhiBottom "ACCS Viewing angle of the bottom of the object(dimensionless)";
CM_ SG_ 192 VFC_Obj08A_PhiTopStdDev "Standard deviation  of the ACCS top angle of object(dimensionless)";
CM_ SG_ 192 VFC_Obj08A_HeadOrientation "The orientation of the head of cyclists or pedestrians that are detected.";
CM_ SG_ 192 VFC_Obj08A_Type "Classification of the object";
CM_ SG_ 192 VFC_Obj08A_PhiBottomStdDev "Standard deviation of the ACCS bottom angle of object(dimensionless)";
CM_ SG_ 192 VFC_Obj08A_NormVx "Normalised object velocity in longitudinal direction.";
CM_ SG_ 192 VFC_Obj08A_NormAx "Normalised object acceleration in longitudinal direction.";
CM_ SG_ 192 VFC_Obj08A_NormAxStdDev "Standard deviation of Normalized Object Acceleration in longitudinal direction";
CM_ SG_ 192 VFC_Obj08A_ProbMovingLat "Probability of object moving laterally";
CM_ SG_ 192 VFC_Obj08A_ID "Unique Object ID";
CM_ SG_ 192 VFC_Obj08A_NormVxStdDev "Standard deviation of Normalized Object Velocity in longitudinal direction";
CM_ SG_ 192 VFC_Obj08A_ProbMovingLong "Probability of object moving longitudinally";
CM_ SG_ 193 VFC_Obj08B_TTIPC_StdDev "Inverse TTI standard deviation";
CM_ SG_ 193 VFC_Obj08B_TTIPC "Inverse TTI";
CM_ SG_ 193 VFC_Obj08B_AngLongitude "angular velocity with regarding to longitudinal direction";
CM_ SG_ 193 VFC_Obj08B_CRC "CRC - Autosar E2E Profile 5";
CM_ SG_ 193 VFC_Obj08B_AliveCtr "Alive counter - Autosar E2E Profile 5";
CM_ SG_ 193 VFC_Obj08B_BlockCtr "Protocol-Signal: Block Counter";
CM_ SG_ 193 VFC_Obj08B_ScaleChange "A scale change of of the detected object";
CM_ SG_ 193 VFC_Obj08B_ScaleChngStdDev "Standard deviation of object scale change";
CM_ SG_ 193 VFC_Obj08B_LineEdgeRightEgo "ObjLineEdgeAngle refers to the line which limits the host vehicle lane on the right side";
CM_ SG_ 193 VFC_Obj08B_LineEdgeLeftEgo "ObjLineEdgeAngle refers to the line which limits the host vehicle lane on the left side";
CM_ SG_ 193 VFC_Obj08B_CompletelyInImg "indicator if the object is completely measrued in the image";
CM_ SG_ 193 VFC_Obj08B_DirIndicator "The detected direction indicator lights";
CM_ SG_ 193 VFC_Obj08B_LineEdgeAngle "Angle between the video object's edge and the lane marking";
CM_ SG_ 193 VFC_Obj08B_BrakeLight "The number of detected lights. More confident if more lights are detected.";
CM_ SG_ 193 VFC_Obj08B_MeasSource "Bitmask for the measurement programs from which this object originates";
CM_ SG_ 193 VFC_Obj08B_Reliab "Bitmask that indicates the algorithmic paths that have detected this object";
BA_DEF_ BO_  "GenMsgSendType" ENUM  "cyclic","NoMsgSendType","IfActive","Event","CA","CE";
BA_DEF_ BO_  "GenMsgCycleTime" INT 0 0;
BA_DEF_ SG_  "GenSigSendType" ENUM  "cyclic","OnChange","OnWrite","IfActive","OnChangeWithRepetition","OnWriteWithRepetition","IfActiveWithRepetition","CA","CE","Event";
BA_DEF_ SG_  "GenSigStartValue" INT 0 0;
BA_DEF_  "DBName" STRING ;
BA_DEF_ BO_  "CANFD_BRS" ENUM  "0","1";
BA_DEF_ BO_  "VFrameFormat" ENUM  "StandardCAN","ExtendedCAN","reserved","reserved","reserved","reserved","reserved","reserved","reserved","reserved","reserved","reserved","reserved","reserved","StandardCAN_FD","ExtendedCAN_FD";
BA_DEF_  "BusBaudateData" INT 0 10000;
BA_DEF_  "BusBaudateOther" INT 0 10000;
BA_DEF_ BO_  "GenMsgILSupport" ENUM  "No","Yes";
BA_DEF_  "BusType" STRING ;
BA_DEF_ SG_  "sigDespEng" STRING ;
BA_DEF_ SG_  "sigSecLevel" STRING ;
BA_DEF_ SG_  "sigConfig" STRING ;
BA_DEF_ SG_  "sigExplanation" STRING ;
BA_DEF_DEF_  "GenMsgSendType" "cyclic";
BA_DEF_DEF_  "GenMsgCycleTime" 0;
BA_DEF_DEF_  "GenSigSendType" "cyclic";
BA_DEF_DEF_  "GenSigStartValue" 0;
BA_DEF_DEF_  "DBName" "";
BA_DEF_DEF_  "CANFD_BRS" "1";
BA_DEF_DEF_  "VFrameFormat" "";
BA_DEF_DEF_  "BusBaudateData" 2;
BA_DEF_DEF_  "BusBaudateOther" 500;
BA_DEF_DEF_  "GenMsgILSupport" "Yes";
BA_DEF_DEF_  "BusType" "CAN FD";
BA_DEF_DEF_  "sigDespEng" "";
BA_DEF_DEF_  "sigSecLevel" "";
BA_DEF_DEF_  "sigConfig" "";
BA_DEF_DEF_  "sigExplanation" "";
BA_ "DBName" "BJEV_5R1V1D_AEB_V3_5";
BA_ "GenMsgCycleTime" BO_ 255 500;
BA_ "VFrameFormat" BO_ 255 14;
BA_ "GenMsgCycleTime" BO_ 75 50;
BA_ "VFrameFormat" BO_ 75 14;
BA_ "GenMsgCycleTime" BO_ 74 50;
BA_ "VFrameFormat" BO_ 74 14;
BA_ "GenMsgCycleTime" BO_ 81 50;
BA_ "VFrameFormat" BO_ 81 14;
BA_ "GenMsgCycleTime" BO_ 2281601536 60;
BA_ "VFrameFormat" BO_ 2281601536 15;
BA_ "GenMsgCycleTime" BO_ 931 100;
BA_ "VFrameFormat" BO_ 931 14;
BA_ "GenMsgCycleTime" BO_ 80 50;
BA_ "VFrameFormat" BO_ 80 14;
BA_ "GenMsgSendType" BO_ 160 3;
BA_ "VFrameFormat" BO_ 160 14;
BA_ "GenMsgSendType" BO_ 176 3;
BA_ "VFrameFormat" BO_ 176 14;
BA_ "GenMsgSendType" BO_ 177 3;
BA_ "VFrameFormat" BO_ 177 14;
BA_ "GenMsgSendType" BO_ 178 3;
BA_ "VFrameFormat" BO_ 178 14;
BA_ "GenMsgSendType" BO_ 179 3;
BA_ "VFrameFormat" BO_ 179 14;
BA_ "GenMsgSendType" BO_ 180 3;
BA_ "VFrameFormat" BO_ 180 14;
BA_ "GenMsgSendType" BO_ 181 3;
BA_ "VFrameFormat" BO_ 181 14;
BA_ "GenMsgSendType" BO_ 182 3;
BA_ "VFrameFormat" BO_ 182 14;
BA_ "GenMsgSendType" BO_ 183 3;
BA_ "VFrameFormat" BO_ 183 14;
BA_ "GenMsgSendType" BO_ 184 3;
BA_ "VFrameFormat" BO_ 184 14;
BA_ "GenMsgSendType" BO_ 185 3;
BA_ "VFrameFormat" BO_ 185 14;
BA_ "GenMsgSendType" BO_ 186 3;
BA_ "VFrameFormat" BO_ 186 14;
BA_ "GenMsgSendType" BO_ 187 3;
BA_ "VFrameFormat" BO_ 187 14;
BA_ "GenMsgSendType" BO_ 188 3;
BA_ "VFrameFormat" BO_ 188 14;
BA_ "GenMsgSendType" BO_ 189 3;
BA_ "VFrameFormat" BO_ 189 14;
BA_ "GenMsgSendType" BO_ 190 3;
BA_ "VFrameFormat" BO_ 190 14;
BA_ "GenMsgSendType" BO_ 191 3;
BA_ "VFrameFormat" BO_ 191 14;
BA_ "GenMsgSendType" BO_ 192 3;
BA_ "VFrameFormat" BO_ 192 14;
BA_ "GenMsgSendType" BO_ 193 3;
BA_ "VFrameFormat" BO_ 193 14;
BA_ "GenSigStartValue" SG_ 74 ADAS_FrntTar1Y_ACC 127;
BA_ "GenSigStartValue" SG_ 931 VFC_MapInfo_RoadCurv 2047;
BA_ "GenSigStartValue" SG_ 80 VFC_SensorState_ProtocolVersion 773;
BA_ "GenSigSendType" SG_ 160 VFC_ObjHdr_AUTOSARTStamp 9;
BA_ "GenSigSendType" SG_ 160 VFC_ObjHdr_CycleTime 9;
BA_ "GenSigSendType" SG_ 160 VFC_ObjHdr_MountPosZ 9;
BA_ "GenSigStartValue" SG_ 160 VFC_ObjHdr_MountPosY 2000;
BA_ "GenSigSendType" SG_ 160 VFC_ObjHdr_MountPosY 9;
BA_ "GenSigStartValue" SG_ 160 VFC_ObjHdr_MountPosX 4000;
BA_ "GenSigSendType" SG_ 160 VFC_ObjHdr_MountPosX 9;
BA_ "GenSigSendType" SG_ 160 VFC_ObjHdr_CalibYawStdDev 9;
BA_ "GenSigStartValue" SG_ 160 VFC_ObjHdr_CalibYawAngle 400;
BA_ "GenSigSendType" SG_ 160 VFC_ObjHdr_CalibYawAngle 9;
BA_ "GenSigSendType" SG_ 160 VFC_ObjHdr_CalibRollStdDev 9;
BA_ "GenSigStartValue" SG_ 160 VFC_ObjHdr_CalibRollAngle 400;
BA_ "GenSigSendType" SG_ 160 VFC_ObjHdr_CalibRollAngle 9;
BA_ "GenSigSendType" SG_ 160 VFC_ObjHdr_FreeViewProb 9;
BA_ "GenSigSendType" SG_ 160 VFC_ObjHdr_CalibPitchStdDev 9;
BA_ "GenSigSendType" SG_ 160 VFC_ObjHdr_CalibState 9;
BA_ "GenSigStartValue" SG_ 160 VFC_ObjHdr_CalibPitchAngle 400;
BA_ "GenSigSendType" SG_ 160 VFC_ObjHdr_CalibPitchAngle 9;
BA_ "GenSigSendType" SG_ 160 VFC_ObjHdr_FrameNo 9;
BA_ "GenSigSendType" SG_ 160 VFC_ObjHdr_CRC 9;
BA_ "GenSigSendType" SG_ 160 VFC_ObjHdr_AliveCtr 9;
BA_ "GenSigSendType" SG_ 160 VFC_ObjHdr_BlockCtr 9;
BA_ "GenSigSendType" SG_ 160 VFC_ObjHdr_TimeStamp 9;
BA_ "GenSigSendType" SG_ 160 VFC_ObjHdr_Blindness 9;
BA_ "GenSigSendType" SG_ 160 VFC_ObjHdr_ObjCount 9;
BA_ "GenSigSendType" SG_ 176 VFC_Obj00A_CRC 9;
BA_ "GenSigSendType" SG_ 176 VFC_Obj00A_AliveCtr 9;
BA_ "GenSigSendType" SG_ 176 VFC_Obj00A_BlockCtr 9;
BA_ "GenSigSendType" SG_ 176 VFC_Obj00A_ProtOrderIndex 9;
BA_ "GenSigStartValue" SG_ 176 VFC_Obj00A_Ax 160;
BA_ "GenSigSendType" SG_ 176 VFC_Obj00A_Ax 9;
BA_ "GenSigStartValue" SG_ 176 VFC_Obj00A_Vx 1540;
BA_ "GenSigSendType" SG_ 176 VFC_Obj00A_Vx 9;
BA_ "GenSigSendType" SG_ 176 VFC_Obj00A_Dx 9;
BA_ "GenSigStartValue" SG_ 176 VFC_Obj00A_Dy 8000;
BA_ "GenSigSendType" SG_ 176 VFC_Obj00A_Dy 9;
BA_ "GenSigStartValue" SG_ 176 VFC_Obj00A_Vy 500;
BA_ "GenSigSendType" SG_ 176 VFC_Obj00A_Vy 9;
BA_ "GenSigStartValue" SG_ 176 VFC_Obj00A_Ay 120;
BA_ "GenSigSendType" SG_ 176 VFC_Obj00A_Ay 9;
BA_ "GenSigSendType" SG_ 176 VFC_Obj00A_DyStdDev 9;
BA_ "GenSigSendType" SG_ 176 VFC_Obj00A_DxStdDev 9;
BA_ "GenSigSendType" SG_ 176 VFC_Obj00A_VxStdDev 9;
BA_ "GenSigSendType" SG_ 176 VFC_Obj00A_ExistProb 9;
BA_ "GenSigSendType" SG_ 176 VFC_Obj00A_VyStdDev 9;
BA_ "GenSigSendType" SG_ 176 VFC_Obj00A_TypeProb 9;
BA_ "GenSigSendType" SG_ 176 VFC_Obj00A_AxStdDev 9;
BA_ "GenSigSendType" SG_ 176 VFC_Obj00A_AyStdDev 9;
BA_ "GenSigStartValue" SG_ 176 VFC_Obj00A_PhiLeft 4000;
BA_ "GenSigSendType" SG_ 176 VFC_Obj00A_PhiLeft 9;
BA_ "GenSigSendType" SG_ 176 VFC_Obj00A_ClassifiedView 9;
BA_ "GenSigSendType" SG_ 176 VFC_Obj00A_Length 9;
BA_ "GenSigSendType" SG_ 176 VFC_Obj00A_WidthStdDev 9;
BA_ "GenSigSendType" SG_ 176 VFC_Obj00A_Height 9;
BA_ "GenSigSendType" SG_ 176 VFC_Obj00A_HeightStdDev 9;
BA_ "GenSigSendType" SG_ 176 VFC_Obj00A_PhiLeftStdDev 9;
BA_ "GenSigSendType" SG_ 176 VFC_Obj00A_HeadingStdDev 9;
BA_ "GenSigSendType" SG_ 176 VFC_Obj00A_Measured 9;
BA_ "GenSigStartValue" SG_ 176 VFC_Obj00A_Heading 157;
BA_ "GenSigSendType" SG_ 176 VFC_Obj00A_Heading 9;
BA_ "GenSigSendType" SG_ 176 VFC_Obj00A_LengthStdDev 9;
BA_ "GenSigStartValue" SG_ 176 VFC_Obj00A_PhiMid 4000;
BA_ "GenSigSendType" SG_ 176 VFC_Obj00A_PhiMid 9;
BA_ "GenSigSendType" SG_ 176 VFC_Obj00A_Width 9;
BA_ "GenSigSendType" SG_ 176 VFC_Obj00A_PhiMidStdDev 9;
BA_ "GenSigStartValue" SG_ 176 VFC_Obj00A_PhiRight 4000;
BA_ "GenSigSendType" SG_ 176 VFC_Obj00A_PhiRight 9;
BA_ "GenSigSendType" SG_ 176 VFC_Obj00A_VisibleView 9;
BA_ "GenSigSendType" SG_ 176 VFC_Obj00A_PhiRightStdDev 9;
BA_ "GenSigStartValue" SG_ 176 VFC_Obj00A_PhiLeftVel 4000;
BA_ "GenSigSendType" SG_ 176 VFC_Obj00A_PhiLeftVel 9;
BA_ "GenSigStartValue" SG_ 176 VFC_Obj00A_PhiRightVel 4000;
BA_ "GenSigSendType" SG_ 176 VFC_Obj00A_PhiRightVel 9;
BA_ "GenSigSendType" SG_ 176 VFC_Obj00A_PhiRightVelStdDev 9;
BA_ "GenSigSendType" SG_ 176 VFC_Obj00A_PhiLeftVelStdDev 9;
BA_ "GenSigStartValue" SG_ 176 VFC_Obj00A_PhiTop 1600;
BA_ "GenSigSendType" SG_ 176 VFC_Obj00A_PhiTop 9;
BA_ "GenSigStartValue" SG_ 176 VFC_Obj00A_PhiBottom 1600;
BA_ "GenSigSendType" SG_ 176 VFC_Obj00A_PhiBottom 9;
BA_ "GenSigSendType" SG_ 176 VFC_Obj00A_PhiTopStdDev 9;
BA_ "GenSigSendType" SG_ 176 VFC_Obj00A_HeadOrientation 9;
BA_ "GenSigSendType" SG_ 176 VFC_Obj00A_Type 9;
BA_ "GenSigSendType" SG_ 176 VFC_Obj00A_PhiBottomStdDev 9;
BA_ "GenSigStartValue" SG_ 176 VFC_Obj00A_NormVx 40000;
BA_ "GenSigSendType" SG_ 176 VFC_Obj00A_NormVx 9;
BA_ "GenSigStartValue" SG_ 176 VFC_Obj00A_NormAx 5000;
BA_ "GenSigSendType" SG_ 176 VFC_Obj00A_NormAx 9;
BA_ "GenSigSendType" SG_ 176 VFC_Obj00A_NormAxStdDev 9;
BA_ "GenSigSendType" SG_ 176 VFC_Obj00A_ProbMovingLat 9;
BA_ "GenSigSendType" SG_ 176 VFC_Obj00A_ID 9;
BA_ "GenSigSendType" SG_ 176 VFC_Obj00A_NormVxStdDev 9;
BA_ "GenSigSendType" SG_ 176 VFC_Obj00A_ProbMovingLong 9;
BA_ "GenSigSendType" SG_ 177 VFC_Obj00B_TTIPC_StdDev 9;
BA_ "GenSigSendType" SG_ 177 VFC_Obj00B_TTIPC 9;
BA_ "GenSigStartValue" SG_ 177 VFC_Obj00B_AngLongitude 500;
BA_ "GenSigSendType" SG_ 177 VFC_Obj00B_AngLongitude 9;
BA_ "GenSigSendType" SG_ 177 VFC_Obj00B_CRC 9;
BA_ "GenSigSendType" SG_ 177 VFC_Obj00B_AliveCtr 9;
BA_ "GenSigSendType" SG_ 177 VFC_Obj00B_BlockCtr 9;
BA_ "GenSigSendType" SG_ 177 VFC_Obj00B_ScaleChange 9;
BA_ "GenSigSendType" SG_ 177 VFC_Obj00B_ScaleChngStdDev 9;
BA_ "GenSigSendType" SG_ 177 VFC_Obj00B_LineEdgeRightEgo 9;
BA_ "GenSigSendType" SG_ 177 VFC_Obj00B_LineEdgeLeftEgo 9;
BA_ "GenSigSendType" SG_ 177 VFC_Obj00B_CompletelyInImg 9;
BA_ "GenSigSendType" SG_ 177 VFC_Obj00B_DirIndicator 9;
BA_ "GenSigStartValue" SG_ 177 VFC_Obj00B_LineEdgeAngle 4000;
BA_ "GenSigSendType" SG_ 177 VFC_Obj00B_LineEdgeAngle 9;
BA_ "GenSigSendType" SG_ 177 VFC_Obj00B_BrakeLight 9;
BA_ "GenSigSendType" SG_ 177 VFC_Obj00B_MeasSource 9;
BA_ "GenSigSendType" SG_ 177 VFC_Obj00B_Reliab 9;
BA_ "GenSigSendType" SG_ 178 VFC_Obj01A_CRC 9;
BA_ "GenSigSendType" SG_ 178 VFC_Obj01A_AliveCtr 9;
BA_ "GenSigSendType" SG_ 178 VFC_Obj01A_BlockCtr 9;
BA_ "GenSigSendType" SG_ 178 VFC_Obj01A_ProtOrderIndex 9;
BA_ "GenSigStartValue" SG_ 178 VFC_Obj01A_Ax 160;
BA_ "GenSigSendType" SG_ 178 VFC_Obj01A_Ax 9;
BA_ "GenSigStartValue" SG_ 178 VFC_Obj01A_Vx 1540;
BA_ "GenSigSendType" SG_ 178 VFC_Obj01A_Vx 9;
BA_ "GenSigSendType" SG_ 178 VFC_Obj01A_Dx 9;
BA_ "GenSigStartValue" SG_ 178 VFC_Obj01A_Dy 8000;
BA_ "GenSigSendType" SG_ 178 VFC_Obj01A_Dy 9;
BA_ "GenSigStartValue" SG_ 178 VFC_Obj01A_Vy 500;
BA_ "GenSigSendType" SG_ 178 VFC_Obj01A_Vy 9;
BA_ "GenSigStartValue" SG_ 178 VFC_Obj01A_Ay 120;
BA_ "GenSigSendType" SG_ 178 VFC_Obj01A_Ay 9;
BA_ "GenSigSendType" SG_ 178 VFC_Obj01A_DyStdDev 9;
BA_ "GenSigSendType" SG_ 178 VFC_Obj01A_DxStdDev 9;
BA_ "GenSigSendType" SG_ 178 VFC_Obj01A_VxStdDev 9;
BA_ "GenSigSendType" SG_ 178 VFC_Obj01A_ExistProb 9;
BA_ "GenSigSendType" SG_ 178 VFC_Obj01A_VyStdDev 9;
BA_ "GenSigSendType" SG_ 178 VFC_Obj01A_TypeProb 9;
BA_ "GenSigSendType" SG_ 178 VFC_Obj01A_AxStdDev 9;
BA_ "GenSigSendType" SG_ 178 VFC_Obj01A_AyStdDev 9;
BA_ "GenSigStartValue" SG_ 178 VFC_Obj01A_PhiLeft 4000;
BA_ "GenSigSendType" SG_ 178 VFC_Obj01A_PhiLeft 9;
BA_ "GenSigSendType" SG_ 178 VFC_Obj01A_ClassifiedView 9;
BA_ "GenSigSendType" SG_ 178 VFC_Obj01A_Length 9;
BA_ "GenSigSendType" SG_ 178 VFC_Obj01A_WidthStdDev 9;
BA_ "GenSigSendType" SG_ 178 VFC_Obj01A_Height 9;
BA_ "GenSigSendType" SG_ 178 VFC_Obj01A_HeightStdDev 9;
BA_ "GenSigSendType" SG_ 178 VFC_Obj01A_PhiLeftStdDev 9;
BA_ "GenSigSendType" SG_ 178 VFC_Obj01A_HeadingStdDev 9;
BA_ "GenSigSendType" SG_ 178 VFC_Obj01A_Measured 9;
BA_ "GenSigStartValue" SG_ 178 VFC_Obj01A_Heading 157;
BA_ "GenSigSendType" SG_ 178 VFC_Obj01A_Heading 9;
BA_ "GenSigSendType" SG_ 178 VFC_Obj01A_LengthStdDev 9;
BA_ "GenSigStartValue" SG_ 178 VFC_Obj01A_PhiMid 4000;
BA_ "GenSigSendType" SG_ 178 VFC_Obj01A_PhiMid 9;
BA_ "GenSigSendType" SG_ 178 VFC_Obj01A_Width 9;
BA_ "GenSigSendType" SG_ 178 VFC_Obj01A_PhiMidStdDev 9;
BA_ "GenSigStartValue" SG_ 178 VFC_Obj01A_PhiRight 4000;
BA_ "GenSigSendType" SG_ 178 VFC_Obj01A_PhiRight 9;
BA_ "GenSigSendType" SG_ 178 VFC_Obj01A_VisibleView 9;
BA_ "GenSigSendType" SG_ 178 VFC_Obj01A_PhiRightStdDev 9;
BA_ "GenSigStartValue" SG_ 178 VFC_Obj01A_PhiLeftVel 4000;
BA_ "GenSigSendType" SG_ 178 VFC_Obj01A_PhiLeftVel 9;
BA_ "GenSigStartValue" SG_ 178 VFC_Obj01A_PhiRightVel 4000;
BA_ "GenSigSendType" SG_ 178 VFC_Obj01A_PhiRightVel 9;
BA_ "GenSigSendType" SG_ 178 VFC_Obj01A_PhiRightVelStdDev 9;
BA_ "GenSigSendType" SG_ 178 VFC_Obj01A_PhiLeftVelStdDev 9;
BA_ "GenSigStartValue" SG_ 178 VFC_Obj01A_PhiTop 1600;
BA_ "GenSigSendType" SG_ 178 VFC_Obj01A_PhiTop 9;
BA_ "GenSigStartValue" SG_ 178 VFC_Obj01A_PhiBottom 1600;
BA_ "GenSigSendType" SG_ 178 VFC_Obj01A_PhiBottom 9;
BA_ "GenSigSendType" SG_ 178 VFC_Obj01A_PhiTopStdDev 9;
BA_ "GenSigSendType" SG_ 178 VFC_Obj01A_HeadOrientation 9;
BA_ "GenSigSendType" SG_ 178 VFC_Obj01A_Type 9;
BA_ "GenSigSendType" SG_ 178 VFC_Obj01A_PhiBottomStdDev 9;
BA_ "GenSigStartValue" SG_ 178 VFC_Obj01A_NormVx 40000;
BA_ "GenSigSendType" SG_ 178 VFC_Obj01A_NormVx 9;
BA_ "GenSigStartValue" SG_ 178 VFC_Obj01A_NormAx 5000;
BA_ "GenSigSendType" SG_ 178 VFC_Obj01A_NormAx 9;
BA_ "GenSigSendType" SG_ 178 VFC_Obj01A_NormAxStdDev 9;
BA_ "GenSigSendType" SG_ 178 VFC_Obj01A_ProbMovingLat 9;
BA_ "GenSigSendType" SG_ 178 VFC_Obj01A_ID 9;
BA_ "GenSigSendType" SG_ 178 VFC_Obj01A_NormVxStdDev 9;
BA_ "GenSigSendType" SG_ 178 VFC_Obj01A_ProbMovingLong 9;
BA_ "GenSigSendType" SG_ 179 VFC_Obj01B_TTIPC_StdDev 9;
BA_ "GenSigSendType" SG_ 179 VFC_Obj01B_TTIPC 9;
BA_ "GenSigStartValue" SG_ 179 VFC_Obj01B_AngLongitude 500;
BA_ "GenSigSendType" SG_ 179 VFC_Obj01B_AngLongitude 9;
BA_ "GenSigSendType" SG_ 179 VFC_Obj01B_CRC 9;
BA_ "GenSigSendType" SG_ 179 VFC_Obj01B_AliveCtr 9;
BA_ "GenSigSendType" SG_ 179 VFC_Obj01B_BlockCtr 9;
BA_ "GenSigSendType" SG_ 179 VFC_Obj01B_ScaleChange 9;
BA_ "GenSigSendType" SG_ 179 VFC_Obj01B_ScaleChngStdDev 9;
BA_ "GenSigSendType" SG_ 179 VFC_Obj01B_LineEdgeRightEgo 9;
BA_ "GenSigSendType" SG_ 179 VFC_Obj01B_LineEdgeLeftEgo 9;
BA_ "GenSigSendType" SG_ 179 VFC_Obj01B_CompletelyInImg 9;
BA_ "GenSigSendType" SG_ 179 VFC_Obj01B_DirIndicator 9;
BA_ "GenSigStartValue" SG_ 179 VFC_Obj01B_LineEdgeAngle 4000;
BA_ "GenSigSendType" SG_ 179 VFC_Obj01B_LineEdgeAngle 9;
BA_ "GenSigSendType" SG_ 179 VFC_Obj01B_BrakeLight 9;
BA_ "GenSigSendType" SG_ 179 VFC_Obj01B_MeasSource 9;
BA_ "GenSigSendType" SG_ 179 VFC_Obj01B_Reliab 9;
BA_ "GenSigSendType" SG_ 180 VFC_Obj02A_CRC 9;
BA_ "GenSigSendType" SG_ 180 VFC_Obj02A_AliveCtr 9;
BA_ "GenSigSendType" SG_ 180 VFC_Obj02A_BlockCtr 9;
BA_ "GenSigSendType" SG_ 180 VFC_Obj02A_ProtOrderIndex 9;
BA_ "GenSigStartValue" SG_ 180 VFC_Obj02A_Ax 160;
BA_ "GenSigSendType" SG_ 180 VFC_Obj02A_Ax 9;
BA_ "GenSigStartValue" SG_ 180 VFC_Obj02A_Vx 1540;
BA_ "GenSigSendType" SG_ 180 VFC_Obj02A_Vx 9;
BA_ "GenSigSendType" SG_ 180 VFC_Obj02A_Dx 9;
BA_ "GenSigStartValue" SG_ 180 VFC_Obj02A_Dy 8000;
BA_ "GenSigSendType" SG_ 180 VFC_Obj02A_Dy 9;
BA_ "GenSigStartValue" SG_ 180 VFC_Obj02A_Vy 500;
BA_ "GenSigSendType" SG_ 180 VFC_Obj02A_Vy 9;
BA_ "GenSigStartValue" SG_ 180 VFC_Obj02A_Ay 120;
BA_ "GenSigSendType" SG_ 180 VFC_Obj02A_Ay 9;
BA_ "GenSigSendType" SG_ 180 VFC_Obj02A_DyStdDev 9;
BA_ "GenSigSendType" SG_ 180 VFC_Obj02A_DxStdDev 9;
BA_ "GenSigSendType" SG_ 180 VFC_Obj02A_VxStdDev 9;
BA_ "GenSigSendType" SG_ 180 VFC_Obj02A_ExistProb 9;
BA_ "GenSigSendType" SG_ 180 VFC_Obj02A_VyStdDev 9;
BA_ "GenSigSendType" SG_ 180 VFC_Obj02A_TypeProb 9;
BA_ "GenSigSendType" SG_ 180 VFC_Obj02A_AxStdDev 9;
BA_ "GenSigSendType" SG_ 180 VFC_Obj02A_AyStdDev 9;
BA_ "GenSigStartValue" SG_ 180 VFC_Obj02A_PhiLeft 4000;
BA_ "GenSigSendType" SG_ 180 VFC_Obj02A_PhiLeft 9;
BA_ "GenSigSendType" SG_ 180 VFC_Obj02A_ClassifiedView 9;
BA_ "GenSigSendType" SG_ 180 VFC_Obj02A_Length 9;
BA_ "GenSigSendType" SG_ 180 VFC_Obj02A_WidthStdDev 9;
BA_ "GenSigSendType" SG_ 180 VFC_Obj02A_Height 9;
BA_ "GenSigSendType" SG_ 180 VFC_Obj02A_HeightStdDev 9;
BA_ "GenSigSendType" SG_ 180 VFC_Obj02A_PhiLeftStdDev 9;
BA_ "GenSigSendType" SG_ 180 VFC_Obj02A_HeadingStdDev 9;
BA_ "GenSigSendType" SG_ 180 VFC_Obj02A_Measured 9;
BA_ "GenSigStartValue" SG_ 180 VFC_Obj02A_Heading 157;
BA_ "GenSigSendType" SG_ 180 VFC_Obj02A_Heading 9;
BA_ "GenSigSendType" SG_ 180 VFC_Obj02A_LengthStdDev 9;
BA_ "GenSigStartValue" SG_ 180 VFC_Obj02A_PhiMid 4000;
BA_ "GenSigSendType" SG_ 180 VFC_Obj02A_PhiMid 9;
BA_ "GenSigSendType" SG_ 180 VFC_Obj02A_Width 9;
BA_ "GenSigSendType" SG_ 180 VFC_Obj02A_PhiMidStdDev 9;
BA_ "GenSigStartValue" SG_ 180 VFC_Obj02A_PhiRight 4000;
BA_ "GenSigSendType" SG_ 180 VFC_Obj02A_PhiRight 9;
BA_ "GenSigSendType" SG_ 180 VFC_Obj02A_VisibleView 9;
BA_ "GenSigSendType" SG_ 180 VFC_Obj02A_PhiRightStdDev 9;
BA_ "GenSigStartValue" SG_ 180 VFC_Obj02A_PhiLeftVel 4000;
BA_ "GenSigSendType" SG_ 180 VFC_Obj02A_PhiLeftVel 9;
BA_ "GenSigStartValue" SG_ 180 VFC_Obj02A_PhiRightVel 4000;
BA_ "GenSigSendType" SG_ 180 VFC_Obj02A_PhiRightVel 9;
BA_ "GenSigSendType" SG_ 180 VFC_Obj02A_PhiRightVelStdDev 9;
BA_ "GenSigSendType" SG_ 180 VFC_Obj02A_PhiLeftVelStdDev 9;
BA_ "GenSigStartValue" SG_ 180 VFC_Obj02A_PhiTop 1600;
BA_ "GenSigSendType" SG_ 180 VFC_Obj02A_PhiTop 9;
BA_ "GenSigStartValue" SG_ 180 VFC_Obj02A_PhiBottom 1600;
BA_ "GenSigSendType" SG_ 180 VFC_Obj02A_PhiBottom 9;
BA_ "GenSigSendType" SG_ 180 VFC_Obj02A_PhiTopStdDev 9;
BA_ "GenSigSendType" SG_ 180 VFC_Obj02A_HeadOrientation 9;
BA_ "GenSigSendType" SG_ 180 VFC_Obj02A_Type 9;
BA_ "GenSigSendType" SG_ 180 VFC_Obj02A_PhiBottomStdDev 9;
BA_ "GenSigStartValue" SG_ 180 VFC_Obj02A_NormVx 40000;
BA_ "GenSigSendType" SG_ 180 VFC_Obj02A_NormVx 9;
BA_ "GenSigStartValue" SG_ 180 VFC_Obj02A_NormAx 5000;
BA_ "GenSigSendType" SG_ 180 VFC_Obj02A_NormAx 9;
BA_ "GenSigSendType" SG_ 180 VFC_Obj02A_NormAxStdDev 9;
BA_ "GenSigSendType" SG_ 180 VFC_Obj02A_ProbMovingLat 9;
BA_ "GenSigSendType" SG_ 180 VFC_Obj02A_ID 9;
BA_ "GenSigSendType" SG_ 180 VFC_Obj02A_NormVxStdDev 9;
BA_ "GenSigSendType" SG_ 180 VFC_Obj02A_ProbMovingLong 9;
BA_ "GenSigSendType" SG_ 181 VFC_Obj02B_TTIPC_StdDev 9;
BA_ "GenSigSendType" SG_ 181 VFC_Obj02B_TTIPC 9;
BA_ "GenSigStartValue" SG_ 181 VFC_Obj02B_AngLongitude 500;
BA_ "GenSigSendType" SG_ 181 VFC_Obj02B_AngLongitude 9;
BA_ "GenSigSendType" SG_ 181 VFC_Obj02B_CRC 9;
BA_ "GenSigSendType" SG_ 181 VFC_Obj02B_AliveCtr 9;
BA_ "GenSigSendType" SG_ 181 VFC_Obj02B_BlockCtr 9;
BA_ "GenSigSendType" SG_ 181 VFC_Obj02B_ScaleChange 9;
BA_ "GenSigSendType" SG_ 181 VFC_Obj02B_ScaleChngStdDev 9;
BA_ "GenSigSendType" SG_ 181 VFC_Obj02B_LineEdgeRightEgo 9;
BA_ "GenSigSendType" SG_ 181 VFC_Obj02B_LineEdgeLeftEgo 9;
BA_ "GenSigSendType" SG_ 181 VFC_Obj02B_CompletelyInImg 9;
BA_ "GenSigSendType" SG_ 181 VFC_Obj02B_DirIndicator 9;
BA_ "GenSigStartValue" SG_ 181 VFC_Obj02B_LineEdgeAngle 4000;
BA_ "GenSigSendType" SG_ 181 VFC_Obj02B_LineEdgeAngle 9;
BA_ "GenSigSendType" SG_ 181 VFC_Obj02B_BrakeLight 9;
BA_ "GenSigSendType" SG_ 181 VFC_Obj02B_MeasSource 9;
BA_ "GenSigSendType" SG_ 181 VFC_Obj02B_Reliab 9;
BA_ "GenSigSendType" SG_ 182 VFC_Obj03A_CRC 9;
BA_ "GenSigSendType" SG_ 182 VFC_Obj03A_AliveCtr 9;
BA_ "GenSigSendType" SG_ 182 VFC_Obj03A_BlockCtr 9;
BA_ "GenSigSendType" SG_ 182 VFC_Obj03A_ProtOrderIndex 9;
BA_ "GenSigStartValue" SG_ 182 VFC_Obj03A_Ax 160;
BA_ "GenSigSendType" SG_ 182 VFC_Obj03A_Ax 9;
BA_ "GenSigStartValue" SG_ 182 VFC_Obj03A_Vx 1540;
BA_ "GenSigSendType" SG_ 182 VFC_Obj03A_Vx 9;
BA_ "GenSigSendType" SG_ 182 VFC_Obj03A_Dx 9;
BA_ "GenSigStartValue" SG_ 182 VFC_Obj03A_Dy 8000;
BA_ "GenSigSendType" SG_ 182 VFC_Obj03A_Dy 9;
BA_ "GenSigStartValue" SG_ 182 VFC_Obj03A_Vy 500;
BA_ "GenSigSendType" SG_ 182 VFC_Obj03A_Vy 9;
BA_ "GenSigStartValue" SG_ 182 VFC_Obj03A_Ay 120;
BA_ "GenSigSendType" SG_ 182 VFC_Obj03A_Ay 9;
BA_ "GenSigSendType" SG_ 182 VFC_Obj03A_DyStdDev 9;
BA_ "GenSigSendType" SG_ 182 VFC_Obj03A_DxStdDev 9;
BA_ "GenSigSendType" SG_ 182 VFC_Obj03A_VxStdDev 9;
BA_ "GenSigSendType" SG_ 182 VFC_Obj03A_ExistProb 9;
BA_ "GenSigSendType" SG_ 182 VFC_Obj03A_VyStdDev 9;
BA_ "GenSigSendType" SG_ 182 VFC_Obj03A_TypeProb 9;
BA_ "GenSigSendType" SG_ 182 VFC_Obj03A_AxStdDev 9;
BA_ "GenSigSendType" SG_ 182 VFC_Obj03A_AyStdDev 9;
BA_ "GenSigStartValue" SG_ 182 VFC_Obj03A_PhiLeft 4000;
BA_ "GenSigSendType" SG_ 182 VFC_Obj03A_PhiLeft 9;
BA_ "GenSigSendType" SG_ 182 VFC_Obj03A_ClassifiedView 9;
BA_ "GenSigSendType" SG_ 182 VFC_Obj03A_Length 9;
BA_ "GenSigSendType" SG_ 182 VFC_Obj03A_WidthStdDev 9;
BA_ "GenSigSendType" SG_ 182 VFC_Obj03A_Height 9;
BA_ "GenSigSendType" SG_ 182 VFC_Obj03A_HeightStdDev 9;
BA_ "GenSigSendType" SG_ 182 VFC_Obj03A_PhiLeftStdDev 9;
BA_ "GenSigSendType" SG_ 182 VFC_Obj03A_HeadingStdDev 9;
BA_ "GenSigSendType" SG_ 182 VFC_Obj03A_Measured 9;
BA_ "GenSigStartValue" SG_ 182 VFC_Obj03A_Heading 157;
BA_ "GenSigSendType" SG_ 182 VFC_Obj03A_Heading 9;
BA_ "GenSigSendType" SG_ 182 VFC_Obj03A_LengthStdDev 9;
BA_ "GenSigStartValue" SG_ 182 VFC_Obj03A_PhiMid 4000;
BA_ "GenSigSendType" SG_ 182 VFC_Obj03A_PhiMid 9;
BA_ "GenSigSendType" SG_ 182 VFC_Obj03A_Width 9;
BA_ "GenSigSendType" SG_ 182 VFC_Obj03A_PhiMidStdDev 9;
BA_ "GenSigStartValue" SG_ 182 VFC_Obj03A_PhiRight 4000;
BA_ "GenSigSendType" SG_ 182 VFC_Obj03A_PhiRight 9;
BA_ "GenSigSendType" SG_ 182 VFC_Obj03A_VisibleView 9;
BA_ "GenSigSendType" SG_ 182 VFC_Obj03A_PhiRightStdDev 9;
BA_ "GenSigStartValue" SG_ 182 VFC_Obj03A_PhiLeftVel 4000;
BA_ "GenSigSendType" SG_ 182 VFC_Obj03A_PhiLeftVel 9;
BA_ "GenSigStartValue" SG_ 182 VFC_Obj03A_PhiRightVel 4000;
BA_ "GenSigSendType" SG_ 182 VFC_Obj03A_PhiRightVel 9;
BA_ "GenSigSendType" SG_ 182 VFC_Obj03A_PhiRightVelStdDev 9;
BA_ "GenSigSendType" SG_ 182 VFC_Obj03A_PhiLeftVelStdDev 9;
BA_ "GenSigStartValue" SG_ 182 VFC_Obj03A_PhiTop 1600;
BA_ "GenSigSendType" SG_ 182 VFC_Obj03A_PhiTop 9;
BA_ "GenSigStartValue" SG_ 182 VFC_Obj03A_PhiBottom 1600;
BA_ "GenSigSendType" SG_ 182 VFC_Obj03A_PhiBottom 9;
BA_ "GenSigSendType" SG_ 182 VFC_Obj03A_PhiTopStdDev 9;
BA_ "GenSigSendType" SG_ 182 VFC_Obj03A_HeadOrientation 9;
BA_ "GenSigSendType" SG_ 182 VFC_Obj03A_Type 9;
BA_ "GenSigSendType" SG_ 182 VFC_Obj03A_PhiBottomStdDev 9;
BA_ "GenSigStartValue" SG_ 182 VFC_Obj03A_NormVx 40000;
BA_ "GenSigSendType" SG_ 182 VFC_Obj03A_NormVx 9;
BA_ "GenSigStartValue" SG_ 182 VFC_Obj03A_NormAx 5000;
BA_ "GenSigSendType" SG_ 182 VFC_Obj03A_NormAx 9;
BA_ "GenSigSendType" SG_ 182 VFC_Obj03A_NormAxStdDev 9;
BA_ "GenSigSendType" SG_ 182 VFC_Obj03A_ProbMovingLat 9;
BA_ "GenSigSendType" SG_ 182 VFC_Obj03A_ID 9;
BA_ "GenSigSendType" SG_ 182 VFC_Obj03A_NormVxStdDev 9;
BA_ "GenSigSendType" SG_ 182 VFC_Obj03A_ProbMovingLong 9;
BA_ "GenSigSendType" SG_ 183 VFC_Obj03B_TTIPC_StdDev 9;
BA_ "GenSigSendType" SG_ 183 VFC_Obj03B_TTIPC 9;
BA_ "GenSigStartValue" SG_ 183 VFC_Obj03B_AngLongitude 500;
BA_ "GenSigSendType" SG_ 183 VFC_Obj03B_AngLongitude 9;
BA_ "GenSigSendType" SG_ 183 VFC_Obj03B_CRC 9;
BA_ "GenSigSendType" SG_ 183 VFC_Obj03B_AliveCtr 9;
BA_ "GenSigSendType" SG_ 183 VFC_Obj03B_BlockCtr 9;
BA_ "GenSigSendType" SG_ 183 VFC_Obj03B_ScaleChange 9;
BA_ "GenSigSendType" SG_ 183 VFC_Obj03B_ScaleChngStdDev 9;
BA_ "GenSigSendType" SG_ 183 VFC_Obj03B_LineEdgeRightEgo 9;
BA_ "GenSigSendType" SG_ 183 VFC_Obj03B_LineEdgeLeftEgo 9;
BA_ "GenSigSendType" SG_ 183 VFC_Obj03B_CompletelyInImg 9;
BA_ "GenSigSendType" SG_ 183 VFC_Obj03B_DirIndicator 9;
BA_ "GenSigStartValue" SG_ 183 VFC_Obj03B_LineEdgeAngle 4000;
BA_ "GenSigSendType" SG_ 183 VFC_Obj03B_LineEdgeAngle 9;
BA_ "GenSigSendType" SG_ 183 VFC_Obj03B_BrakeLight 9;
BA_ "GenSigSendType" SG_ 183 VFC_Obj03B_MeasSource 9;
BA_ "GenSigSendType" SG_ 183 VFC_Obj03B_Reliab 9;
BA_ "GenSigSendType" SG_ 184 VFC_Obj04A_CRC 9;
BA_ "GenSigSendType" SG_ 184 VFC_Obj04A_AliveCtr 9;
BA_ "GenSigSendType" SG_ 184 VFC_Obj04A_BlockCtr 9;
BA_ "GenSigSendType" SG_ 184 VFC_Obj04A_ProtOrderIndex 9;
BA_ "GenSigStartValue" SG_ 184 VFC_Obj04A_Ax 160;
BA_ "GenSigSendType" SG_ 184 VFC_Obj04A_Ax 9;
BA_ "GenSigStartValue" SG_ 184 VFC_Obj04A_Vx 1540;
BA_ "GenSigSendType" SG_ 184 VFC_Obj04A_Vx 9;
BA_ "GenSigSendType" SG_ 184 VFC_Obj04A_Dx 9;
BA_ "GenSigStartValue" SG_ 184 VFC_Obj04A_Dy 8000;
BA_ "GenSigSendType" SG_ 184 VFC_Obj04A_Dy 9;
BA_ "GenSigStartValue" SG_ 184 VFC_Obj04A_Vy 500;
BA_ "GenSigSendType" SG_ 184 VFC_Obj04A_Vy 9;
BA_ "GenSigStartValue" SG_ 184 VFC_Obj04A_Ay 120;
BA_ "GenSigSendType" SG_ 184 VFC_Obj04A_Ay 9;
BA_ "GenSigSendType" SG_ 184 VFC_Obj04A_DyStdDev 9;
BA_ "GenSigSendType" SG_ 184 VFC_Obj04A_DxStdDev 9;
BA_ "GenSigSendType" SG_ 184 VFC_Obj04A_VxStdDev 9;
BA_ "GenSigSendType" SG_ 184 VFC_Obj04A_ExistProb 9;
BA_ "GenSigSendType" SG_ 184 VFC_Obj04A_VyStdDev 9;
BA_ "GenSigSendType" SG_ 184 VFC_Obj04A_TypeProb 9;
BA_ "GenSigSendType" SG_ 184 VFC_Obj04A_AxStdDev 9;
BA_ "GenSigSendType" SG_ 184 VFC_Obj04A_AyStdDev 9;
BA_ "GenSigStartValue" SG_ 184 VFC_Obj04A_PhiLeft 4000;
BA_ "GenSigSendType" SG_ 184 VFC_Obj04A_PhiLeft 9;
BA_ "GenSigSendType" SG_ 184 VFC_Obj04A_ClassifiedView 9;
BA_ "GenSigSendType" SG_ 184 VFC_Obj04A_Length 9;
BA_ "GenSigSendType" SG_ 184 VFC_Obj04A_WidthStdDev 9;
BA_ "GenSigSendType" SG_ 184 VFC_Obj04A_Height 9;
BA_ "GenSigSendType" SG_ 184 VFC_Obj04A_HeightStdDev 9;
BA_ "GenSigSendType" SG_ 184 VFC_Obj04A_PhiLeftStdDev 9;
BA_ "GenSigSendType" SG_ 184 VFC_Obj04A_HeadingStdDev 9;
BA_ "GenSigSendType" SG_ 184 VFC_Obj04A_Measured 9;
BA_ "GenSigStartValue" SG_ 184 VFC_Obj04A_Heading 157;
BA_ "GenSigSendType" SG_ 184 VFC_Obj04A_Heading 9;
BA_ "GenSigSendType" SG_ 184 VFC_Obj04A_LengthStdDev 9;
BA_ "GenSigStartValue" SG_ 184 VFC_Obj04A_PhiMid 4000;
BA_ "GenSigSendType" SG_ 184 VFC_Obj04A_PhiMid 9;
BA_ "GenSigSendType" SG_ 184 VFC_Obj04A_Width 9;
BA_ "GenSigSendType" SG_ 184 VFC_Obj04A_PhiMidStdDev 9;
BA_ "GenSigStartValue" SG_ 184 VFC_Obj04A_PhiRight 4000;
BA_ "GenSigSendType" SG_ 184 VFC_Obj04A_PhiRight 9;
BA_ "GenSigSendType" SG_ 184 VFC_Obj04A_VisibleView 9;
BA_ "GenSigSendType" SG_ 184 VFC_Obj04A_PhiRightStdDev 9;
BA_ "GenSigStartValue" SG_ 184 VFC_Obj04A_PhiLeftVel 4000;
BA_ "GenSigSendType" SG_ 184 VFC_Obj04A_PhiLeftVel 9;
BA_ "GenSigStartValue" SG_ 184 VFC_Obj04A_PhiRightVel 4000;
BA_ "GenSigSendType" SG_ 184 VFC_Obj04A_PhiRightVel 9;
BA_ "GenSigSendType" SG_ 184 VFC_Obj04A_PhiRightVelStdDev 9;
BA_ "GenSigSendType" SG_ 184 VFC_Obj04A_PhiLeftVelStdDev 9;
BA_ "GenSigStartValue" SG_ 184 VFC_Obj04A_PhiTop 1600;
BA_ "GenSigSendType" SG_ 184 VFC_Obj04A_PhiTop 9;
BA_ "GenSigStartValue" SG_ 184 VFC_Obj04A_PhiBottom 1600;
BA_ "GenSigSendType" SG_ 184 VFC_Obj04A_PhiBottom 9;
BA_ "GenSigSendType" SG_ 184 VFC_Obj04A_PhiTopStdDev 9;
BA_ "GenSigSendType" SG_ 184 VFC_Obj04A_HeadOrientation 9;
BA_ "GenSigSendType" SG_ 184 VFC_Obj04A_Type 9;
BA_ "GenSigSendType" SG_ 184 VFC_Obj04A_PhiBottomStdDev 9;
BA_ "GenSigStartValue" SG_ 184 VFC_Obj04A_NormVx 40000;
BA_ "GenSigSendType" SG_ 184 VFC_Obj04A_NormVx 9;
BA_ "GenSigStartValue" SG_ 184 VFC_Obj04A_NormAx 5000;
BA_ "GenSigSendType" SG_ 184 VFC_Obj04A_NormAx 9;
BA_ "GenSigSendType" SG_ 184 VFC_Obj04A_NormAxStdDev 9;
BA_ "GenSigSendType" SG_ 184 VFC_Obj04A_ProbMovingLat 9;
BA_ "GenSigSendType" SG_ 184 VFC_Obj04A_ID 9;
BA_ "GenSigSendType" SG_ 184 VFC_Obj04A_NormVxStdDev 9;
BA_ "GenSigSendType" SG_ 184 VFC_Obj04A_ProbMovingLong 9;
BA_ "GenSigSendType" SG_ 185 VFC_Obj04B_TTIPC_StdDev 9;
BA_ "GenSigSendType" SG_ 185 VFC_Obj04B_TTIPC 9;
BA_ "GenSigStartValue" SG_ 185 VFC_Obj04B_AngLongitude 500;
BA_ "GenSigSendType" SG_ 185 VFC_Obj04B_AngLongitude 9;
BA_ "GenSigSendType" SG_ 185 VFC_Obj04B_CRC 9;
BA_ "GenSigSendType" SG_ 185 VFC_Obj04B_AliveCtr 9;
BA_ "GenSigSendType" SG_ 185 VFC_Obj04B_BlockCtr 9;
BA_ "GenSigSendType" SG_ 185 VFC_Obj04B_ScaleChange 9;
BA_ "GenSigSendType" SG_ 185 VFC_Obj04B_ScaleChngStdDev 9;
BA_ "GenSigSendType" SG_ 185 VFC_Obj04B_LineEdgeRightEgo 9;
BA_ "GenSigSendType" SG_ 185 VFC_Obj04B_LineEdgeLeftEgo 9;
BA_ "GenSigSendType" SG_ 185 VFC_Obj04B_CompletelyInImg 9;
BA_ "GenSigSendType" SG_ 185 VFC_Obj04B_DirIndicator 9;
BA_ "GenSigStartValue" SG_ 185 VFC_Obj04B_LineEdgeAngle 4000;
BA_ "GenSigSendType" SG_ 185 VFC_Obj04B_LineEdgeAngle 9;
BA_ "GenSigSendType" SG_ 185 VFC_Obj04B_BrakeLight 9;
BA_ "GenSigSendType" SG_ 185 VFC_Obj04B_MeasSource 9;
BA_ "GenSigSendType" SG_ 185 VFC_Obj04B_Reliab 9;
BA_ "GenSigSendType" SG_ 186 VFC_Obj05A_CRC 9;
BA_ "GenSigSendType" SG_ 186 VFC_Obj05A_AliveCtr 9;
BA_ "GenSigSendType" SG_ 186 VFC_Obj05A_BlockCtr 9;
BA_ "GenSigSendType" SG_ 186 VFC_Obj05A_ProtOrderIndex 9;
BA_ "GenSigStartValue" SG_ 186 VFC_Obj05A_Ax 160;
BA_ "GenSigSendType" SG_ 186 VFC_Obj05A_Ax 9;
BA_ "GenSigStartValue" SG_ 186 VFC_Obj05A_Vx 1540;
BA_ "GenSigSendType" SG_ 186 VFC_Obj05A_Vx 9;
BA_ "GenSigSendType" SG_ 186 VFC_Obj05A_Dx 9;
BA_ "GenSigStartValue" SG_ 186 VFC_Obj05A_Dy 8000;
BA_ "GenSigSendType" SG_ 186 VFC_Obj05A_Dy 9;
BA_ "GenSigStartValue" SG_ 186 VFC_Obj05A_Vy 500;
BA_ "GenSigSendType" SG_ 186 VFC_Obj05A_Vy 9;
BA_ "GenSigStartValue" SG_ 186 VFC_Obj05A_Ay 120;
BA_ "GenSigSendType" SG_ 186 VFC_Obj05A_Ay 9;
BA_ "GenSigSendType" SG_ 186 VFC_Obj05A_DyStdDev 9;
BA_ "GenSigSendType" SG_ 186 VFC_Obj05A_DxStdDev 9;
BA_ "GenSigSendType" SG_ 186 VFC_Obj05A_VxStdDev 9;
BA_ "GenSigSendType" SG_ 186 VFC_Obj05A_ExistProb 9;
BA_ "GenSigSendType" SG_ 186 VFC_Obj05A_VyStdDev 9;
BA_ "GenSigSendType" SG_ 186 VFC_Obj05A_TypeProb 9;
BA_ "GenSigSendType" SG_ 186 VFC_Obj05A_AxStdDev 9;
BA_ "GenSigSendType" SG_ 186 VFC_Obj05A_AyStdDev 9;
BA_ "GenSigStartValue" SG_ 186 VFC_Obj05A_PhiLeft 4000;
BA_ "GenSigSendType" SG_ 186 VFC_Obj05A_PhiLeft 9;
BA_ "GenSigSendType" SG_ 186 VFC_Obj05A_ClassifiedView 9;
BA_ "GenSigSendType" SG_ 186 VFC_Obj05A_Length 9;
BA_ "GenSigSendType" SG_ 186 VFC_Obj05A_WidthStdDev 9;
BA_ "GenSigSendType" SG_ 186 VFC_Obj05A_Height 9;
BA_ "GenSigSendType" SG_ 186 VFC_Obj05A_HeightStdDev 9;
BA_ "GenSigSendType" SG_ 186 VFC_Obj05A_PhiLeftStdDev 9;
BA_ "GenSigSendType" SG_ 186 VFC_Obj05A_HeadingStdDev 9;
BA_ "GenSigSendType" SG_ 186 VFC_Obj05A_Measured 9;
BA_ "GenSigStartValue" SG_ 186 VFC_Obj05A_Heading 157;
BA_ "GenSigSendType" SG_ 186 VFC_Obj05A_Heading 9;
BA_ "GenSigSendType" SG_ 186 VFC_Obj05A_LengthStdDev 9;
BA_ "GenSigStartValue" SG_ 186 VFC_Obj05A_PhiMid 4000;
BA_ "GenSigSendType" SG_ 186 VFC_Obj05A_PhiMid 9;
BA_ "GenSigSendType" SG_ 186 VFC_Obj05A_Width 9;
BA_ "GenSigSendType" SG_ 186 VFC_Obj05A_PhiMidStdDev 9;
BA_ "GenSigStartValue" SG_ 186 VFC_Obj05A_PhiRight 4000;
BA_ "GenSigSendType" SG_ 186 VFC_Obj05A_PhiRight 9;
BA_ "GenSigSendType" SG_ 186 VFC_Obj05A_VisibleView 9;
BA_ "GenSigSendType" SG_ 186 VFC_Obj05A_PhiRightStdDev 9;
BA_ "GenSigStartValue" SG_ 186 VFC_Obj05A_PhiLeftVel 4000;
BA_ "GenSigSendType" SG_ 186 VFC_Obj05A_PhiLeftVel 9;
BA_ "GenSigStartValue" SG_ 186 VFC_Obj05A_PhiRightVel 4000;
BA_ "GenSigSendType" SG_ 186 VFC_Obj05A_PhiRightVel 9;
BA_ "GenSigSendType" SG_ 186 VFC_Obj05A_PhiRightVelStdDev 9;
BA_ "GenSigSendType" SG_ 186 VFC_Obj05A_PhiLeftVelStdDev 9;
BA_ "GenSigStartValue" SG_ 186 VFC_Obj05A_PhiTop 1600;
BA_ "GenSigSendType" SG_ 186 VFC_Obj05A_PhiTop 9;
BA_ "GenSigStartValue" SG_ 186 VFC_Obj05A_PhiBottom 1600;
BA_ "GenSigSendType" SG_ 186 VFC_Obj05A_PhiBottom 9;
BA_ "GenSigSendType" SG_ 186 VFC_Obj05A_PhiTopStdDev 9;
BA_ "GenSigSendType" SG_ 186 VFC_Obj05A_HeadOrientation 9;
BA_ "GenSigSendType" SG_ 186 VFC_Obj05A_Type 9;
BA_ "GenSigSendType" SG_ 186 VFC_Obj05A_PhiBottomStdDev 9;
BA_ "GenSigStartValue" SG_ 186 VFC_Obj05A_NormVx 40000;
BA_ "GenSigSendType" SG_ 186 VFC_Obj05A_NormVx 9;
BA_ "GenSigStartValue" SG_ 186 VFC_Obj05A_NormAx 5000;
BA_ "GenSigSendType" SG_ 186 VFC_Obj05A_NormAx 9;
BA_ "GenSigSendType" SG_ 186 VFC_Obj05A_NormAxStdDev 9;
BA_ "GenSigSendType" SG_ 186 VFC_Obj05A_ProbMovingLat 9;
BA_ "GenSigSendType" SG_ 186 VFC_Obj05A_ID 9;
BA_ "GenSigSendType" SG_ 186 VFC_Obj05A_NormVxStdDev 9;
BA_ "GenSigSendType" SG_ 186 VFC_Obj05A_ProbMovingLong 9;
BA_ "GenSigSendType" SG_ 187 VFC_Obj05B_TTIPC_StdDev 9;
BA_ "GenSigSendType" SG_ 187 VFC_Obj05B_TTIPC 9;
BA_ "GenSigStartValue" SG_ 187 VFC_Obj05B_AngLongitude 500;
BA_ "GenSigSendType" SG_ 187 VFC_Obj05B_AngLongitude 9;
BA_ "GenSigSendType" SG_ 187 VFC_Obj05B_CRC 9;
BA_ "GenSigSendType" SG_ 187 VFC_Obj05B_AliveCtr 9;
BA_ "GenSigSendType" SG_ 187 VFC_Obj05B_BlockCtr 9;
BA_ "GenSigSendType" SG_ 187 VFC_Obj05B_ScaleChange 9;
BA_ "GenSigSendType" SG_ 187 VFC_Obj05B_ScaleChngStdDev 9;
BA_ "GenSigSendType" SG_ 187 VFC_Obj05B_LineEdgeRightEgo 9;
BA_ "GenSigSendType" SG_ 187 VFC_Obj05B_LineEdgeLeftEgo 9;
BA_ "GenSigSendType" SG_ 187 VFC_Obj05B_CompletelyInImg 9;
BA_ "GenSigSendType" SG_ 187 VFC_Obj05B_DirIndicator 9;
BA_ "GenSigStartValue" SG_ 187 VFC_Obj05B_LineEdgeAngle 4000;
BA_ "GenSigSendType" SG_ 187 VFC_Obj05B_LineEdgeAngle 9;
BA_ "GenSigSendType" SG_ 187 VFC_Obj05B_BrakeLight 9;
BA_ "GenSigSendType" SG_ 187 VFC_Obj05B_MeasSource 9;
BA_ "GenSigSendType" SG_ 187 VFC_Obj05B_Reliab 9;
BA_ "GenSigSendType" SG_ 188 VFC_Obj06A_CRC 9;
BA_ "GenSigSendType" SG_ 188 VFC_Obj06A_AliveCtr 9;
BA_ "GenSigSendType" SG_ 188 VFC_Obj06A_BlockCtr 9;
BA_ "GenSigSendType" SG_ 188 VFC_Obj06A_ProtOrderIndex 9;
BA_ "GenSigStartValue" SG_ 188 VFC_Obj06A_Ax 160;
BA_ "GenSigSendType" SG_ 188 VFC_Obj06A_Ax 9;
BA_ "GenSigStartValue" SG_ 188 VFC_Obj06A_Vx 1540;
BA_ "GenSigSendType" SG_ 188 VFC_Obj06A_Vx 9;
BA_ "GenSigSendType" SG_ 188 VFC_Obj06A_Dx 9;
BA_ "GenSigStartValue" SG_ 188 VFC_Obj06A_Dy 8000;
BA_ "GenSigSendType" SG_ 188 VFC_Obj06A_Dy 9;
BA_ "GenSigStartValue" SG_ 188 VFC_Obj06A_Vy 500;
BA_ "GenSigSendType" SG_ 188 VFC_Obj06A_Vy 9;
BA_ "GenSigStartValue" SG_ 188 VFC_Obj06A_Ay 120;
BA_ "GenSigSendType" SG_ 188 VFC_Obj06A_Ay 9;
BA_ "GenSigSendType" SG_ 188 VFC_Obj06A_DyStdDev 9;
BA_ "GenSigSendType" SG_ 188 VFC_Obj06A_DxStdDev 9;
BA_ "GenSigSendType" SG_ 188 VFC_Obj06A_VxStdDev 9;
BA_ "GenSigSendType" SG_ 188 VFC_Obj06A_ExistProb 9;
BA_ "GenSigSendType" SG_ 188 VFC_Obj06A_VyStdDev 9;
BA_ "GenSigSendType" SG_ 188 VFC_Obj06A_TypeProb 9;
BA_ "GenSigSendType" SG_ 188 VFC_Obj06A_AxStdDev 9;
BA_ "GenSigSendType" SG_ 188 VFC_Obj06A_AyStdDev 9;
BA_ "GenSigStartValue" SG_ 188 VFC_Obj06A_PhiLeft 4000;
BA_ "GenSigSendType" SG_ 188 VFC_Obj06A_PhiLeft 9;
BA_ "GenSigSendType" SG_ 188 VFC_Obj06A_ClassifiedView 9;
BA_ "GenSigSendType" SG_ 188 VFC_Obj06A_Length 9;
BA_ "GenSigSendType" SG_ 188 VFC_Obj06A_WidthStdDev 9;
BA_ "GenSigSendType" SG_ 188 VFC_Obj06A_Height 9;
BA_ "GenSigSendType" SG_ 188 VFC_Obj06A_HeightStdDev 9;
BA_ "GenSigSendType" SG_ 188 VFC_Obj06A_PhiLeftStdDev 9;
BA_ "GenSigSendType" SG_ 188 VFC_Obj06A_HeadingStdDev 9;
BA_ "GenSigSendType" SG_ 188 VFC_Obj06A_Measured 9;
BA_ "GenSigStartValue" SG_ 188 VFC_Obj06A_Heading 157;
BA_ "GenSigSendType" SG_ 188 VFC_Obj06A_Heading 9;
BA_ "GenSigSendType" SG_ 188 VFC_Obj06A_LengthStdDev 9;
BA_ "GenSigStartValue" SG_ 188 VFC_Obj06A_PhiMid 4000;
BA_ "GenSigSendType" SG_ 188 VFC_Obj06A_PhiMid 9;
BA_ "GenSigSendType" SG_ 188 VFC_Obj06A_Width 9;
BA_ "GenSigSendType" SG_ 188 VFC_Obj06A_PhiMidStdDev 9;
BA_ "GenSigStartValue" SG_ 188 VFC_Obj06A_PhiRight 4000;
BA_ "GenSigSendType" SG_ 188 VFC_Obj06A_PhiRight 9;
BA_ "GenSigSendType" SG_ 188 VFC_Obj06A_VisibleView 9;
BA_ "GenSigSendType" SG_ 188 VFC_Obj06A_PhiRightStdDev 9;
BA_ "GenSigStartValue" SG_ 188 VFC_Obj06A_PhiLeftVel 4000;
BA_ "GenSigSendType" SG_ 188 VFC_Obj06A_PhiLeftVel 9;
BA_ "GenSigStartValue" SG_ 188 VFC_Obj06A_PhiRightVel 4000;
BA_ "GenSigSendType" SG_ 188 VFC_Obj06A_PhiRightVel 9;
BA_ "GenSigSendType" SG_ 188 VFC_Obj06A_PhiRightVelStdDev 9;
BA_ "GenSigSendType" SG_ 188 VFC_Obj06A_PhiLeftVelStdDev 9;
BA_ "GenSigStartValue" SG_ 188 VFC_Obj06A_PhiTop 1600;
BA_ "GenSigSendType" SG_ 188 VFC_Obj06A_PhiTop 9;
BA_ "GenSigStartValue" SG_ 188 VFC_Obj06A_PhiBottom 1600;
BA_ "GenSigSendType" SG_ 188 VFC_Obj06A_PhiBottom 9;
BA_ "GenSigSendType" SG_ 188 VFC_Obj06A_PhiTopStdDev 9;
BA_ "GenSigSendType" SG_ 188 VFC_Obj06A_HeadOrientation 9;
BA_ "GenSigSendType" SG_ 188 VFC_Obj06A_Type 9;
BA_ "GenSigSendType" SG_ 188 VFC_Obj06A_PhiBottomStdDev 9;
BA_ "GenSigStartValue" SG_ 188 VFC_Obj06A_NormVx 40000;
BA_ "GenSigSendType" SG_ 188 VFC_Obj06A_NormVx 9;
BA_ "GenSigStartValue" SG_ 188 VFC_Obj06A_NormAx 5000;
BA_ "GenSigSendType" SG_ 188 VFC_Obj06A_NormAx 9;
BA_ "GenSigSendType" SG_ 188 VFC_Obj06A_NormAxStdDev 9;
BA_ "GenSigSendType" SG_ 188 VFC_Obj06A_ProbMovingLat 9;
BA_ "GenSigSendType" SG_ 188 VFC_Obj06A_ID 9;
BA_ "GenSigSendType" SG_ 188 VFC_Obj06A_NormVxStdDev 9;
BA_ "GenSigSendType" SG_ 188 VFC_Obj06A_ProbMovingLong 9;
BA_ "GenSigSendType" SG_ 189 VFC_Obj06B_TTIPC_StdDev 9;
BA_ "GenSigSendType" SG_ 189 VFC_Obj06B_TTIPC 9;
BA_ "GenSigStartValue" SG_ 189 VFC_Obj06B_AngLongitude 500;
BA_ "GenSigSendType" SG_ 189 VFC_Obj06B_AngLongitude 9;
BA_ "GenSigSendType" SG_ 189 VFC_Obj06B_CRC 9;
BA_ "GenSigSendType" SG_ 189 VFC_Obj06B_AliveCtr 9;
BA_ "GenSigSendType" SG_ 189 VFC_Obj06B_BlockCtr 9;
BA_ "GenSigSendType" SG_ 189 VFC_Obj06B_ScaleChange 9;
BA_ "GenSigSendType" SG_ 189 VFC_Obj06B_ScaleChngStdDev 9;
BA_ "GenSigSendType" SG_ 189 VFC_Obj06B_LineEdgeRightEgo 9;
BA_ "GenSigSendType" SG_ 189 VFC_Obj06B_LineEdgeLeftEgo 9;
BA_ "GenSigSendType" SG_ 189 VFC_Obj06B_CompletelyInImg 9;
BA_ "GenSigSendType" SG_ 189 VFC_Obj06B_DirIndicator 9;
BA_ "GenSigStartValue" SG_ 189 VFC_Obj06B_LineEdgeAngle 4000;
BA_ "GenSigSendType" SG_ 189 VFC_Obj06B_LineEdgeAngle 9;
BA_ "GenSigSendType" SG_ 189 VFC_Obj06B_BrakeLight 9;
BA_ "GenSigSendType" SG_ 189 VFC_Obj06B_MeasSource 9;
BA_ "GenSigSendType" SG_ 189 VFC_Obj06B_Reliab 9;
BA_ "GenSigSendType" SG_ 190 VFC_Obj07A_CRC 9;
BA_ "GenSigSendType" SG_ 190 VFC_Obj07A_AliveCtr 9;
BA_ "GenSigSendType" SG_ 190 VFC_Obj07A_BlockCtr 9;
BA_ "GenSigSendType" SG_ 190 VFC_Obj07A_ProtOrderIndex 9;
BA_ "GenSigStartValue" SG_ 190 VFC_Obj07A_Ax 160;
BA_ "GenSigSendType" SG_ 190 VFC_Obj07A_Ax 9;
BA_ "GenSigStartValue" SG_ 190 VFC_Obj07A_Vx 1540;
BA_ "GenSigSendType" SG_ 190 VFC_Obj07A_Vx 9;
BA_ "GenSigSendType" SG_ 190 VFC_Obj07A_Dx 9;
BA_ "GenSigStartValue" SG_ 190 VFC_Obj07A_Dy 8000;
BA_ "GenSigSendType" SG_ 190 VFC_Obj07A_Dy 9;
BA_ "GenSigStartValue" SG_ 190 VFC_Obj07A_Vy 500;
BA_ "GenSigSendType" SG_ 190 VFC_Obj07A_Vy 9;
BA_ "GenSigStartValue" SG_ 190 VFC_Obj07A_Ay 120;
BA_ "GenSigSendType" SG_ 190 VFC_Obj07A_Ay 9;
BA_ "GenSigSendType" SG_ 190 VFC_Obj07A_DyStdDev 9;
BA_ "GenSigSendType" SG_ 190 VFC_Obj07A_DxStdDev 9;
BA_ "GenSigSendType" SG_ 190 VFC_Obj07A_VxStdDev 9;
BA_ "GenSigSendType" SG_ 190 VFC_Obj07A_ExistProb 9;
BA_ "GenSigSendType" SG_ 190 VFC_Obj07A_VyStdDev 9;
BA_ "GenSigSendType" SG_ 190 VFC_Obj07A_TypeProb 9;
BA_ "GenSigSendType" SG_ 190 VFC_Obj07A_AxStdDev 9;
BA_ "GenSigSendType" SG_ 190 VFC_Obj07A_AyStdDev 9;
BA_ "GenSigStartValue" SG_ 190 VFC_Obj07A_PhiLeft 4000;
BA_ "GenSigSendType" SG_ 190 VFC_Obj07A_PhiLeft 9;
BA_ "GenSigSendType" SG_ 190 VFC_Obj07A_ClassifiedView 9;
BA_ "GenSigSendType" SG_ 190 VFC_Obj07A_Length 9;
BA_ "GenSigSendType" SG_ 190 VFC_Obj07A_WidthStdDev 9;
BA_ "GenSigSendType" SG_ 190 VFC_Obj07A_Height 9;
BA_ "GenSigSendType" SG_ 190 VFC_Obj07A_HeightStdDev 9;
BA_ "GenSigSendType" SG_ 190 VFC_Obj07A_PhiLeftStdDev 9;
BA_ "GenSigSendType" SG_ 190 VFC_Obj07A_HeadingStdDev 9;
BA_ "GenSigSendType" SG_ 190 VFC_Obj07A_Measured 9;
BA_ "GenSigStartValue" SG_ 190 VFC_Obj07A_Heading 157;
BA_ "GenSigSendType" SG_ 190 VFC_Obj07A_Heading 9;
BA_ "GenSigSendType" SG_ 190 VFC_Obj07A_LengthStdDev 9;
BA_ "GenSigStartValue" SG_ 190 VFC_Obj07A_PhiMid 4000;
BA_ "GenSigSendType" SG_ 190 VFC_Obj07A_PhiMid 9;
BA_ "GenSigSendType" SG_ 190 VFC_Obj07A_Width 9;
BA_ "GenSigSendType" SG_ 190 VFC_Obj07A_PhiMidStdDev 9;
BA_ "GenSigStartValue" SG_ 190 VFC_Obj07A_PhiRight 4000;
BA_ "GenSigSendType" SG_ 190 VFC_Obj07A_PhiRight 9;
BA_ "GenSigSendType" SG_ 190 VFC_Obj07A_VisibleView 9;
BA_ "GenSigSendType" SG_ 190 VFC_Obj07A_PhiRightStdDev 9;
BA_ "GenSigStartValue" SG_ 190 VFC_Obj07A_PhiLeftVel 4000;
BA_ "GenSigSendType" SG_ 190 VFC_Obj07A_PhiLeftVel 9;
BA_ "GenSigStartValue" SG_ 190 VFC_Obj07A_PhiRightVel 4000;
BA_ "GenSigSendType" SG_ 190 VFC_Obj07A_PhiRightVel 9;
BA_ "GenSigSendType" SG_ 190 VFC_Obj07A_PhiRightVelStdDev 9;
BA_ "GenSigSendType" SG_ 190 VFC_Obj07A_PhiLeftVelStdDev 9;
BA_ "GenSigStartValue" SG_ 190 VFC_Obj07A_PhiTop 1600;
BA_ "GenSigSendType" SG_ 190 VFC_Obj07A_PhiTop 9;
BA_ "GenSigStartValue" SG_ 190 VFC_Obj07A_PhiBottom 1600;
BA_ "GenSigSendType" SG_ 190 VFC_Obj07A_PhiBottom 9;
BA_ "GenSigSendType" SG_ 190 VFC_Obj07A_PhiTopStdDev 9;
BA_ "GenSigSendType" SG_ 190 VFC_Obj07A_HeadOrientation 9;
BA_ "GenSigSendType" SG_ 190 VFC_Obj07A_Type 9;
BA_ "GenSigSendType" SG_ 190 VFC_Obj07A_PhiBottomStdDev 9;
BA_ "GenSigStartValue" SG_ 190 VFC_Obj07A_NormVx 40000;
BA_ "GenSigSendType" SG_ 190 VFC_Obj07A_NormVx 9;
BA_ "GenSigStartValue" SG_ 190 VFC_Obj07A_NormAx 5000;
BA_ "GenSigSendType" SG_ 190 VFC_Obj07A_NormAx 9;
BA_ "GenSigSendType" SG_ 190 VFC_Obj07A_NormAxStdDev 9;
BA_ "GenSigSendType" SG_ 190 VFC_Obj07A_ProbMovingLat 9;
BA_ "GenSigSendType" SG_ 190 VFC_Obj07A_ID 9;
BA_ "GenSigSendType" SG_ 190 VFC_Obj07A_NormVxStdDev 9;
BA_ "GenSigSendType" SG_ 190 VFC_Obj07A_ProbMovingLong 9;
BA_ "GenSigSendType" SG_ 191 VFC_Obj07B_TTIPC_StdDev 9;
BA_ "GenSigSendType" SG_ 191 VFC_Obj07B_TTIPC 9;
BA_ "GenSigStartValue" SG_ 191 VFC_Obj07B_AngLongitude 500;
BA_ "GenSigSendType" SG_ 191 VFC_Obj07B_AngLongitude 9;
BA_ "GenSigSendType" SG_ 191 VFC_Obj07B_CRC 9;
BA_ "GenSigSendType" SG_ 191 VFC_Obj07B_AliveCtr 9;
BA_ "GenSigSendType" SG_ 191 VFC_Obj07B_BlockCtr 9;
BA_ "GenSigSendType" SG_ 191 VFC_Obj07B_ScaleChange 9;
BA_ "GenSigSendType" SG_ 191 VFC_Obj07B_ScaleChngStdDev 9;
BA_ "GenSigSendType" SG_ 191 VFC_Obj07B_LineEdgeRightEgo 9;
BA_ "GenSigSendType" SG_ 191 VFC_Obj07B_LineEdgeLeftEgo 9;
BA_ "GenSigSendType" SG_ 191 VFC_Obj07B_CompletelyInImg 9;
BA_ "GenSigSendType" SG_ 191 VFC_Obj07B_DirIndicator 9;
BA_ "GenSigStartValue" SG_ 191 VFC_Obj07B_LineEdgeAngle 4000;
BA_ "GenSigSendType" SG_ 191 VFC_Obj07B_LineEdgeAngle 9;
BA_ "GenSigSendType" SG_ 191 VFC_Obj07B_BrakeLight 9;
BA_ "GenSigSendType" SG_ 191 VFC_Obj07B_MeasSource 9;
BA_ "GenSigSendType" SG_ 191 VFC_Obj07B_Reliab 9;
BA_ "GenSigSendType" SG_ 192 VFC_Obj08A_CRC 9;
BA_ "GenSigSendType" SG_ 192 VFC_Obj08A_AliveCtr 9;
BA_ "GenSigSendType" SG_ 192 VFC_Obj08A_BlockCtr 9;
BA_ "GenSigSendType" SG_ 192 VFC_Obj08A_ProtOrderIndex 9;
BA_ "GenSigStartValue" SG_ 192 VFC_Obj08A_Ax 160;
BA_ "GenSigSendType" SG_ 192 VFC_Obj08A_Ax 9;
BA_ "GenSigStartValue" SG_ 192 VFC_Obj08A_Vx 1540;
BA_ "GenSigSendType" SG_ 192 VFC_Obj08A_Vx 9;
BA_ "GenSigSendType" SG_ 192 VFC_Obj08A_Dx 9;
BA_ "GenSigStartValue" SG_ 192 VFC_Obj08A_Dy 8000;
BA_ "GenSigSendType" SG_ 192 VFC_Obj08A_Dy 9;
BA_ "GenSigStartValue" SG_ 192 VFC_Obj08A_Vy 500;
BA_ "GenSigSendType" SG_ 192 VFC_Obj08A_Vy 9;
BA_ "GenSigStartValue" SG_ 192 VFC_Obj08A_Ay 120;
BA_ "GenSigSendType" SG_ 192 VFC_Obj08A_Ay 9;
BA_ "GenSigSendType" SG_ 192 VFC_Obj08A_DyStdDev 9;
BA_ "GenSigSendType" SG_ 192 VFC_Obj08A_DxStdDev 9;
BA_ "GenSigSendType" SG_ 192 VFC_Obj08A_VxStdDev 9;
BA_ "GenSigSendType" SG_ 192 VFC_Obj08A_ExistProb 9;
BA_ "GenSigSendType" SG_ 192 VFC_Obj08A_VyStdDev 9;
BA_ "GenSigSendType" SG_ 192 VFC_Obj08A_TypeProb 9;
BA_ "GenSigSendType" SG_ 192 VFC_Obj08A_AxStdDev 9;
BA_ "GenSigSendType" SG_ 192 VFC_Obj08A_AyStdDev 9;
BA_ "GenSigStartValue" SG_ 192 VFC_Obj08A_PhiLeft 4000;
BA_ "GenSigSendType" SG_ 192 VFC_Obj08A_PhiLeft 9;
BA_ "GenSigSendType" SG_ 192 VFC_Obj08A_ClassifiedView 9;
BA_ "GenSigSendType" SG_ 192 VFC_Obj08A_Length 9;
BA_ "GenSigSendType" SG_ 192 VFC_Obj08A_WidthStdDev 9;
BA_ "GenSigSendType" SG_ 192 VFC_Obj08A_Height 9;
BA_ "GenSigSendType" SG_ 192 VFC_Obj08A_HeightStdDev 9;
BA_ "GenSigSendType" SG_ 192 VFC_Obj08A_PhiLeftStdDev 9;
BA_ "GenSigSendType" SG_ 192 VFC_Obj08A_HeadingStdDev 9;
BA_ "GenSigSendType" SG_ 192 VFC_Obj08A_Measured 9;
BA_ "GenSigStartValue" SG_ 192 VFC_Obj08A_Heading 157;
BA_ "GenSigSendType" SG_ 192 VFC_Obj08A_Heading 9;
BA_ "GenSigSendType" SG_ 192 VFC_Obj08A_LengthStdDev 9;
BA_ "GenSigStartValue" SG_ 192 VFC_Obj08A_PhiMid 4000;
BA_ "GenSigSendType" SG_ 192 VFC_Obj08A_PhiMid 9;
BA_ "GenSigSendType" SG_ 192 VFC_Obj08A_Width 9;
BA_ "GenSigSendType" SG_ 192 VFC_Obj08A_PhiMidStdDev 9;
BA_ "GenSigStartValue" SG_ 192 VFC_Obj08A_PhiRight 4000;
BA_ "GenSigSendType" SG_ 192 VFC_Obj08A_PhiRight 9;
BA_ "GenSigSendType" SG_ 192 VFC_Obj08A_VisibleView 9;
BA_ "GenSigSendType" SG_ 192 VFC_Obj08A_PhiRightStdDev 9;
BA_ "GenSigStartValue" SG_ 192 VFC_Obj08A_PhiLeftVel 4000;
BA_ "GenSigSendType" SG_ 192 VFC_Obj08A_PhiLeftVel 9;
BA_ "GenSigStartValue" SG_ 192 VFC_Obj08A_PhiRightVel 4000;
BA_ "GenSigSendType" SG_ 192 VFC_Obj08A_PhiRightVel 9;
BA_ "GenSigSendType" SG_ 192 VFC_Obj08A_PhiRightVelStdDev 9;
BA_ "GenSigSendType" SG_ 192 VFC_Obj08A_PhiLeftVelStdDev 9;
BA_ "GenSigStartValue" SG_ 192 VFC_Obj08A_PhiTop 1600;
BA_ "GenSigSendType" SG_ 192 VFC_Obj08A_PhiTop 9;
BA_ "GenSigStartValue" SG_ 192 VFC_Obj08A_PhiBottom 1600;
BA_ "GenSigSendType" SG_ 192 VFC_Obj08A_PhiBottom 9;
BA_ "GenSigSendType" SG_ 192 VFC_Obj08A_PhiTopStdDev 9;
BA_ "GenSigSendType" SG_ 192 VFC_Obj08A_HeadOrientation 9;
BA_ "GenSigSendType" SG_ 192 VFC_Obj08A_Type 9;
BA_ "GenSigSendType" SG_ 192 VFC_Obj08A_PhiBottomStdDev 9;
BA_ "GenSigStartValue" SG_ 192 VFC_Obj08A_NormVx 40000;
BA_ "GenSigSendType" SG_ 192 VFC_Obj08A_NormVx 9;
BA_ "GenSigStartValue" SG_ 192 VFC_Obj08A_NormAx 5000;
BA_ "GenSigSendType" SG_ 192 VFC_Obj08A_NormAx 9;
BA_ "GenSigSendType" SG_ 192 VFC_Obj08A_NormAxStdDev 9;
BA_ "GenSigSendType" SG_ 192 VFC_Obj08A_ProbMovingLat 9;
BA_ "GenSigSendType" SG_ 192 VFC_Obj08A_ID 9;
BA_ "GenSigSendType" SG_ 192 VFC_Obj08A_NormVxStdDev 9;
BA_ "GenSigSendType" SG_ 192 VFC_Obj08A_ProbMovingLong 9;
BA_ "GenSigSendType" SG_ 193 VFC_Obj08B_TTIPC_StdDev 9;
BA_ "GenSigSendType" SG_ 193 VFC_Obj08B_TTIPC 9;
BA_ "GenSigStartValue" SG_ 193 VFC_Obj08B_AngLongitude 500;
BA_ "GenSigSendType" SG_ 193 VFC_Obj08B_AngLongitude 9;
BA_ "GenSigSendType" SG_ 193 VFC_Obj08B_CRC 9;
BA_ "GenSigSendType" SG_ 193 VFC_Obj08B_AliveCtr 9;
BA_ "GenSigSendType" SG_ 193 VFC_Obj08B_BlockCtr 9;
BA_ "GenSigSendType" SG_ 193 VFC_Obj08B_ScaleChange 9;
BA_ "GenSigSendType" SG_ 193 VFC_Obj08B_ScaleChngStdDev 9;
BA_ "GenSigSendType" SG_ 193 VFC_Obj08B_LineEdgeRightEgo 9;
BA_ "GenSigSendType" SG_ 193 VFC_Obj08B_LineEdgeLeftEgo 9;
BA_ "GenSigSendType" SG_ 193 VFC_Obj08B_CompletelyInImg 9;
BA_ "GenSigSendType" SG_ 193 VFC_Obj08B_DirIndicator 9;
BA_ "GenSigStartValue" SG_ 193 VFC_Obj08B_LineEdgeAngle 4000;
BA_ "GenSigSendType" SG_ 193 VFC_Obj08B_LineEdgeAngle 9;
BA_ "GenSigSendType" SG_ 193 VFC_Obj08B_BrakeLight 9;
BA_ "GenSigSendType" SG_ 193 VFC_Obj08B_MeasSource 9;
BA_ "GenSigSendType" SG_ 193 VFC_Obj08B_Reliab 9;
VAL_ 75 ADAS_FwdWarnFltTxt 1 "FCW Failure" 0 "Default" ;
VAL_ 75 ADAS_FCWSwtFb 3 "Fault" 2 "Switch On" 1 "Switch Off" 0 "Default" ;
VAL_ 75 ADAS_AEBSwtFb 3 "Fault" 2 "Switch On" 1 "Switch Off" 0 "Default" ;
VAL_ 75 ADAS_ADASSnvtySetFb 3 "Reserved" 2 "High Sensitivity" 1 "Low Sensitivity" 0 "Default" ;
VAL_ 75 ADAS_Warn_FCW 3 "Acutewarning" 2 "Prewarning" 1 "Latent Warning" 0 "No Warning" ;
VAL_ 75 ADAS_WarnTyp_FCWAEB 7 "Reserved" 6 "Bus" 5 "Cyclist" 4 "Truck" 3 "Car" 2 "Pedestrian" 1 "Unknown" 0 "Reserved" ;
VAL_ 75 ADAS_Sts_FCW 7 "Reserved" 6 "Reserved" 5 "Reserved" 4 "Fault" 3 "Active" 2 "Standby" 1 "Reserved" 0 "Off" ;
VAL_ 75 ADAS_Sts_AEB 7 "Reserved" 6 "Reserved" 5 "Reserved" 4 "Fault" 3 "Active" 2 "Standby" 1 "Reserved" 0 "Off" ;
VAL_ 74 ADAS_FrntTar1Typ_ACC 7 "Reserved" 6 "Reserved" 5 "Reserved" 4 "Reserved" 3 "Motor/Bicycle" 2 "Truck" 1 "Car" 0 "No Display" ;
VAL_ 74 ADAS_FrntTar1X_ACC 255 "Invalid" ;
VAL_ 74 ADAS_FrntTar1Y_ACC 255 "Invalid" ;
VAL_ 81 RFC_SensorS_Status 0 "SENSOR FULLY OPERATIONAL" 1 "HW MALFUNCTION" 2 "DSP ISSUES" 3 "COMMUNICATION ERRORS" 4 "MISALIGNMENT (OUT OF SPEC)" 5 "SENSOR BLIDNESS DETECTED" 6 "SENSOR DISTUBED" 7 "OTHER ISSUES" 8 "RESERVED1" 9 "RESERVED2" 10 "RESERVED3" 11 "RESERVED4" 12 "RESERVED5" 13 "RESERVED6" 14 "RESERVED7" 15 "INVALID" ;
VAL_ 931 VFC_MapInfo_CountryCode 156 "CN=156" 0 "Unknown" ;
VAL_ 931 VFC_MapInfo_CurrentLane 7 "N/A" 6 "reserved" 5 "mid-lane within 3 or mare lanes" 4 "right most lane" 3 "left most lane" 2 "Signal lane road" 1 "Emergency lane" 0 "Unknown" ;
VAL_ 931 VFC_MapInfo_BuildUp 3 "reserved" 2 "unknown" 1 "in the segment" 0 "not in the segment" ;
VAL_ 931 VFC_MapInfo_Bridge 3 "reserved" 2 "unknown" 1 "in the segment" 0 "not in the segment" ;
VAL_ 931 VFC_MapInfo_Tunnel 3 "reserved" 2 "unknown" 1 "in the segment" 0 "not in the segment" ;
VAL_ 931 VFC_MapInfo_TollGate 3 "reserved" 2 "unknown" 1 "in the segment" 0 "not in the segment" ;
VAL_ 931 VFC_MapInfo_DiRoad_Offset200 3 "Invalid" 2 "Unknown" 1 "True" 0 "False" ;
VAL_ 931 VFC_MapInfo_LaneNum_Offset200 7 "Unknown" 6 "6 or more lanes" 5 "5 lanes" 4 "4 lanes" 3 "3 lanes" 2 "2 lanes" 1 "1 lane" 0 "Wrong direction" ;
VAL_ 931 VFC_MapInfo_LaneNum_Offset0 7 "Unknown" 6 "6 or more lanes" 5 "5 lanes" 4 "4 lanes" 3 "3 lanes" 2 "2 lanes" 1 "1 lane" 0 "Wrong direction" ;
VAL_ 931 VFC_MapInfo_DiRoad_Offset0 3 "Invalid" 2 "Unknown" 1 "True" 0 "False" ;
VAL_ 931 VFC_MapInfo_RoadClass_Offset200 7 "SNA" 6 "Class 6" 5 "Class 5" 4 "Class 4" 3 "Class 3" 2 "Class 2" 1 "Class 1" 0 "Unknown" ;
VAL_ 931 VFC_MapInfo_RoadClass_Offset0 7 "SNA" 6 "Class 6" 5 "Class 5" 4 "Class 4" 3 "Class 3" 2 "Class 2" 1 "Class 1" 0 "Unknown" ;
VAL_ 80 VFC_SensorState_Status 0 "off" 1 "on" 2 "Reduced" 3 "HW_Error" 4 "SW_Error" 5 "FID_Active" 6 "Reserved6" 7 "Reserved7" ;
VAL_ 80 VFC_SensorState_VisionFault 0 "Camera Operational" 1 "Camera Initialization" 2 "Camera Limited (reduced Mode)" 3 "Reserved" 4 "Camera Blocked" 5 "Camera Error" 6 "Camera Calibration" 7 "Reserved" ;
VAL_ 160 VFC_ObjHdr_CalibState 0 "Fully Calibrated" 1 "Not Calibrated" 2 "Yaw Not Calibrated" 3 "Pitch Not Calibrated" 4 "Roll Not Calibrated" 5 "Reserved5" 6 "Reserved6" 7 "Reserved7" ;
VAL_ 176 VFC_Obj00A_ClassifiedView 0 "Unknown" 1 "Front" 2 "Rear" 3 "Left" 4 "Right" ;
VAL_ 176 VFC_Obj00A_Measured 0 "Invalid" 1 "Predicted" 2 "Measured" 3 "Reserved" ;
VAL_ 176 VFC_Obj00A_VisibleView 0 "UNKNOWN" 1 "CLASSIC" 2 "SIDE" 3 "CLASSIC_SIDE" 4 "SIDE_CLASSIC" ;
VAL_ 176 VFC_Obj00A_HeadOrientation 0 "N/A" 1 "Head front" 2 "Head left front" 3 "Head left" 4 "Head left back" 5 "Head back" 6 "Head right back" 7 "Head right" 8 "Head right front" 15 "Unknown" ;
VAL_ 176 VFC_Obj00A_Type 0 "No type" 1 "Car" 2 "Truck" 3 "Motorcycle" 4 "Pedestrian" 5 "Cyclist" 6 "Animal" ;
VAL_ 177 VFC_Obj00B_LineEdgeRightEgo 0 "Right" 1 "Not Right" ;
VAL_ 177 VFC_Obj00B_LineEdgeLeftEgo 0 "Left" 1 "Not Left" ;
VAL_ 177 VFC_Obj00B_CompletelyInImg 0 "completely measured" 1 "not completely measured" ;
VAL_ 177 VFC_Obj00B_DirIndicator 0 "No direction indicator" 1 "Left indicator" 2 "Right indicator" 3 "Warning Lights" 4 "Unknown" ;
VAL_ 177 VFC_Obj00B_BrakeLight 0 "No light detected" 1 "One light detected" 2 "Two lights detected" 3 "Three lights detected" 4 "Unknown" ;
VAL_ 177 VFC_Obj00B_MeasSource 1 "MOD" 2 "PDET" 4 "OFT" 8 "OLS" 16 "Reserved" ;
VAL_ 177 VFC_Obj00B_Reliab 1 "Classifier Path" 2 "Flow Path" 4 "Disparity Path" 8 "Semantic Segmentation Path" 16 "Flow Stixel Path" 32 "Reserved" ;
VAL_ 178 VFC_Obj01A_ClassifiedView 0 "Unknown" 1 "Front" 2 "Rear" 3 "Left" 4 "Right" ;
VAL_ 178 VFC_Obj01A_Measured 0 "Invalid" 1 "Predicted" 2 "Measured" 3 "Reserved" ;
VAL_ 178 VFC_Obj01A_VisibleView 0 "UNKNOWN" 1 "CLASSIC" 2 "SIDE" 3 "CLASSIC_SIDE" 4 "SIDE_CLASSIC" ;
VAL_ 178 VFC_Obj01A_HeadOrientation 0 "N/A" 1 "Head front" 2 "Head left front" 3 "Head left" 4 "Head left back" 5 "Head back" 6 "Head right back" 7 "Head right" 8 "Head right front" 15 "Unknown" ;
VAL_ 178 VFC_Obj01A_Type 0 "No type" 1 "Car" 2 "Truck" 3 "Motorcycle" 4 "Pedestrian" 5 "Cyclist" 6 "Animal" ;
VAL_ 179 VFC_Obj01B_LineEdgeRightEgo 0 "Right" 1 "Not Right" ;
VAL_ 179 VFC_Obj01B_LineEdgeLeftEgo 0 "Left" 1 "Not Left" ;
VAL_ 179 VFC_Obj01B_CompletelyInImg 0 "completely measured" 1 "not completely measured" ;
VAL_ 179 VFC_Obj01B_DirIndicator 0 "No direction indicator" 1 "Left indicator" 2 "Right indicator" 3 "Warning Lights" 4 "Unknown" ;
VAL_ 179 VFC_Obj01B_BrakeLight 0 "No light detected" 1 "One light detected" 2 "Two lights detected" 3 "Three lights detected" 4 "Unknown" ;
VAL_ 179 VFC_Obj01B_MeasSource 1 "MOD" 2 "PDET" 4 "OFT" 8 "OLS" 16 "Reserved" ;
VAL_ 179 VFC_Obj01B_Reliab 1 "Classifier Path" 2 "Flow Path" 4 "Disparity Path" 8 "Semantic Segmentation Path" 16 "Flow Stixel Path" 32 "Reserved" ;
VAL_ 180 VFC_Obj02A_ClassifiedView 0 "Unknown" 1 "Front" 2 "Rear" 3 "Left" 4 "Right" ;
VAL_ 180 VFC_Obj02A_Measured 0 "Invalid" 1 "Predicted" 2 "Measured" 3 "Reserved" ;
VAL_ 180 VFC_Obj02A_VisibleView 0 "UNKNOWN" 1 "CLASSIC" 2 "SIDE" 3 "CLASSIC_SIDE" 4 "SIDE_CLASSIC" ;
VAL_ 180 VFC_Obj02A_HeadOrientation 0 "N/A" 1 "Head front" 2 "Head left front" 3 "Head left" 4 "Head left back" 5 "Head back" 6 "Head right back" 7 "Head right" 8 "Head right front" 15 "Unknown" ;
VAL_ 180 VFC_Obj02A_Type 0 "No type" 1 "Car" 2 "Truck" 3 "Motorcycle" 4 "Pedestrian" 5 "Cyclist" 6 "Animal" ;
VAL_ 181 VFC_Obj02B_LineEdgeRightEgo 0 "Right" 1 "Not Right" ;
VAL_ 181 VFC_Obj02B_LineEdgeLeftEgo 0 "Left" 1 "Not Left" ;
VAL_ 181 VFC_Obj02B_CompletelyInImg 0 "completely measured" 1 "not completely measured" ;
VAL_ 181 VFC_Obj02B_DirIndicator 0 "No direction indicator" 1 "Left indicator" 2 "Right indicator" 3 "Warning Lights" 4 "Unknown" ;
VAL_ 181 VFC_Obj02B_BrakeLight 0 "No light detected" 1 "One light detected" 2 "Two lights detected" 3 "Three lights detected" 4 "Unknown" ;
VAL_ 181 VFC_Obj02B_MeasSource 1 "MOD" 2 "PDET" 4 "OFT" 8 "OLS" 16 "Reserved" ;
VAL_ 181 VFC_Obj02B_Reliab 1 "Classifier Path" 2 "Flow Path" 4 "Disparity Path" 8 "Semantic Segmentation Path" 16 "Flow Stixel Path" 32 "Reserved" ;
VAL_ 182 VFC_Obj03A_ClassifiedView 0 "Unknown" 1 "Front" 2 "Rear" 3 "Left" 4 "Right" ;
VAL_ 182 VFC_Obj03A_Measured 0 "Invalid" 1 "Predicted" 2 "Measured" 3 "Reserved" ;
VAL_ 182 VFC_Obj03A_VisibleView 0 "UNKNOWN" 1 "CLASSIC" 2 "SIDE" 3 "CLASSIC_SIDE" 4 "SIDE_CLASSIC" ;
VAL_ 182 VFC_Obj03A_HeadOrientation 0 "N/A" 1 "Head front" 2 "Head left front" 3 "Head left" 4 "Head left back" 5 "Head back" 6 "Head right back" 7 "Head right" 8 "Head right front" 15 "Unknown" ;
VAL_ 182 VFC_Obj03A_Type 0 "No type" 1 "Car" 2 "Truck" 3 "Motorcycle" 4 "Pedestrian" 5 "Cyclist" 6 "Animal" ;
VAL_ 183 VFC_Obj03B_LineEdgeRightEgo 0 "Right" 1 "Not Right" ;
VAL_ 183 VFC_Obj03B_LineEdgeLeftEgo 0 "Left" 1 "Not Left" ;
VAL_ 183 VFC_Obj03B_CompletelyInImg 0 "completely measured" 1 "not completely measured" ;
VAL_ 183 VFC_Obj03B_DirIndicator 0 "No direction indicator" 1 "Left indicator" 2 "Right indicator" 3 "Warning Lights" 4 "Unknown" ;
VAL_ 183 VFC_Obj03B_BrakeLight 0 "No light detected" 1 "One light detected" 2 "Two lights detected" 3 "Three lights detected" 4 "Unknown" ;
VAL_ 183 VFC_Obj03B_MeasSource 1 "MOD" 2 "PDET" 4 "OFT" 8 "OLS" 16 "Reserved" ;
VAL_ 183 VFC_Obj03B_Reliab 1 "Classifier Path" 2 "Flow Path" 4 "Disparity Path" 8 "Semantic Segmentation Path" 16 "Flow Stixel Path" 32 "Reserved" ;
VAL_ 184 VFC_Obj04A_ClassifiedView 0 "Unknown" 1 "Front" 2 "Rear" 3 "Left" 4 "Right" ;
VAL_ 184 VFC_Obj04A_Measured 0 "Invalid" 1 "Predicted" 2 "Measured" 3 "Reserved" ;
VAL_ 184 VFC_Obj04A_VisibleView 0 "UNKNOWN" 1 "CLASSIC" 2 "SIDE" 3 "CLASSIC_SIDE" 4 "SIDE_CLASSIC" ;
VAL_ 184 VFC_Obj04A_HeadOrientation 0 "N/A" 1 "Head front" 2 "Head left front" 3 "Head left" 4 "Head left back" 5 "Head back" 6 "Head right back" 7 "Head right" 8 "Head right front" 15 "Unknown" ;
VAL_ 184 VFC_Obj04A_Type 0 "No type" 1 "Car" 2 "Truck" 3 "Motorcycle" 4 "Pedestrian" 5 "Cyclist" 6 "Animal" ;
VAL_ 185 VFC_Obj04B_LineEdgeRightEgo 0 "Right" 1 "Not Right" ;
VAL_ 185 VFC_Obj04B_LineEdgeLeftEgo 0 "Left" 1 "Not Left" ;
VAL_ 185 VFC_Obj04B_CompletelyInImg 0 "completely measured" 1 "not completely measured" ;
VAL_ 185 VFC_Obj04B_DirIndicator 0 "No direction indicator" 1 "Left indicator" 2 "Right indicator" 3 "Warning Lights" 4 "Unknown" ;
VAL_ 185 VFC_Obj04B_BrakeLight 0 "No light detected" 1 "One light detected" 2 "Two lights detected" 3 "Three lights detected" 4 "Unknown" ;
VAL_ 185 VFC_Obj04B_MeasSource 1 "MOD" 2 "PDET" 4 "OFT" 8 "OLS" 16 "Reserved" ;
VAL_ 185 VFC_Obj04B_Reliab 1 "Classifier Path" 2 "Flow Path" 4 "Disparity Path" 8 "Semantic Segmentation Path" 16 "Flow Stixel Path" 32 "Reserved" ;
VAL_ 186 VFC_Obj05A_ClassifiedView 0 "Unknown" 1 "Front" 2 "Rear" 3 "Left" 4 "Right" ;
VAL_ 186 VFC_Obj05A_Measured 0 "Invalid" 1 "Predicted" 2 "Measured" 3 "Reserved" ;
VAL_ 186 VFC_Obj05A_VisibleView 0 "UNKNOWN" 1 "CLASSIC" 2 "SIDE" 3 "CLASSIC_SIDE" 4 "SIDE_CLASSIC" ;
VAL_ 186 VFC_Obj05A_HeadOrientation 0 "N/A" 1 "Head front" 2 "Head left front" 3 "Head left" 4 "Head left back" 5 "Head back" 6 "Head right back" 7 "Head right" 8 "Head right front" 15 "Unknown" ;
VAL_ 186 VFC_Obj05A_Type 0 "No type" 1 "Car" 2 "Truck" 3 "Motorcycle" 4 "Pedestrian" 5 "Cyclist" 6 "Animal" ;
VAL_ 187 VFC_Obj05B_LineEdgeRightEgo 0 "Right" 1 "Not Right" ;
VAL_ 187 VFC_Obj05B_LineEdgeLeftEgo 0 "Left" 1 "Not Left" ;
VAL_ 187 VFC_Obj05B_CompletelyInImg 0 "completely measured" 1 "not completely measured" ;
VAL_ 187 VFC_Obj05B_DirIndicator 0 "No direction indicator" 1 "Left indicator" 2 "Right indicator" 3 "Warning Lights" 4 "Unknown" ;
VAL_ 187 VFC_Obj05B_BrakeLight 0 "No light detected" 1 "One light detected" 2 "Two lights detected" 3 "Three lights detected" 4 "Unknown" ;
VAL_ 187 VFC_Obj05B_MeasSource 1 "MOD" 2 "PDET" 4 "OFT" 8 "OLS" 16 "Reserved" ;
VAL_ 187 VFC_Obj05B_Reliab 1 "Classifier Path" 2 "Flow Path" 4 "Disparity Path" 8 "Semantic Segmentation Path" 16 "Flow Stixel Path" 32 "Reserved" ;
VAL_ 188 VFC_Obj06A_ClassifiedView 0 "Unknown" 1 "Front" 2 "Rear" 3 "Left" 4 "Right" ;
VAL_ 188 VFC_Obj06A_Measured 0 "Invalid" 1 "Predicted" 2 "Measured" 3 "Reserved" ;
VAL_ 188 VFC_Obj06A_VisibleView 0 "UNKNOWN" 1 "CLASSIC" 2 "SIDE" 3 "CLASSIC_SIDE" 4 "SIDE_CLASSIC" ;
VAL_ 188 VFC_Obj06A_HeadOrientation 0 "N/A" 1 "Head front" 2 "Head left front" 3 "Head left" 4 "Head left back" 5 "Head back" 6 "Head right back" 7 "Head right" 8 "Head right front" 15 "Unknown" ;
VAL_ 188 VFC_Obj06A_Type 0 "No type" 1 "Car" 2 "Truck" 3 "Motorcycle" 4 "Pedestrian" 5 "Cyclist" 6 "Animal" ;
VAL_ 189 VFC_Obj06B_LineEdgeRightEgo 0 "Right" 1 "Not Right" ;
VAL_ 189 VFC_Obj06B_LineEdgeLeftEgo 0 "Left" 1 "Not Left" ;
VAL_ 189 VFC_Obj06B_CompletelyInImg 0 "completely measured" 1 "not completely measured" ;
VAL_ 189 VFC_Obj06B_DirIndicator 0 "No direction indicator" 1 "Left indicator" 2 "Right indicator" 3 "Warning Lights" 4 "Unknown" ;
VAL_ 189 VFC_Obj06B_BrakeLight 0 "No light detected" 1 "One light detected" 2 "Two lights detected" 3 "Three lights detected" 4 "Unknown" ;
VAL_ 189 VFC_Obj06B_MeasSource 1 "MOD" 2 "PDET" 4 "OFT" 8 "OLS" 16 "Reserved" ;
VAL_ 189 VFC_Obj06B_Reliab 1 "Classifier Path" 2 "Flow Path" 4 "Disparity Path" 8 "Semantic Segmentation Path" 16 "Flow Stixel Path" 32 "Reserved" ;
VAL_ 190 VFC_Obj07A_ClassifiedView 0 "Unknown" 1 "Front" 2 "Rear" 3 "Left" 4 "Right" ;
VAL_ 190 VFC_Obj07A_Measured 0 "Invalid" 1 "Predicted" 2 "Measured" 3 "Reserved" ;
VAL_ 190 VFC_Obj07A_VisibleView 0 "UNKNOWN" 1 "CLASSIC" 2 "SIDE" 3 "CLASSIC_SIDE" 4 "SIDE_CLASSIC" ;
VAL_ 190 VFC_Obj07A_HeadOrientation 0 "N/A" 1 "Head front" 2 "Head left front" 3 "Head left" 4 "Head left back" 5 "Head back" 6 "Head right back" 7 "Head right" 8 "Head right front" 15 "Unknown" ;
VAL_ 190 VFC_Obj07A_Type 0 "No type" 1 "Car" 2 "Truck" 3 "Motorcycle" 4 "Pedestrian" 5 "Cyclist" 6 "Animal" ;
VAL_ 191 VFC_Obj07B_LineEdgeRightEgo 0 "Right" 1 "Not Right" ;
VAL_ 191 VFC_Obj07B_LineEdgeLeftEgo 0 "Left" 1 "Not Left" ;
VAL_ 191 VFC_Obj07B_CompletelyInImg 0 "completely measured" 1 "not completely measured" ;
VAL_ 191 VFC_Obj07B_DirIndicator 0 "No direction indicator" 1 "Left indicator" 2 "Right indicator" 3 "Warning Lights" 4 "Unknown" ;
VAL_ 191 VFC_Obj07B_BrakeLight 0 "No light detected" 1 "One light detected" 2 "Two lights detected" 3 "Three lights detected" 4 "Unknown" ;
VAL_ 191 VFC_Obj07B_MeasSource 1 "MOD" 2 "PDET" 4 "OFT" 8 "OLS" 16 "Reserved" ;
VAL_ 191 VFC_Obj07B_Reliab 1 "Classifier Path" 2 "Flow Path" 4 "Disparity Path" 8 "Semantic Segmentation Path" 16 "Flow Stixel Path" 32 "Reserved" ;
VAL_ 192 VFC_Obj08A_ClassifiedView 0 "Unknown" 1 "Front" 2 "Rear" 3 "Left" 4 "Right" ;
VAL_ 192 VFC_Obj08A_Measured 0 "Invalid" 1 "Predicted" 2 "Measured" 3 "Reserved" ;
VAL_ 192 VFC_Obj08A_VisibleView 0 "UNKNOWN" 1 "CLASSIC" 2 "SIDE" 3 "CLASSIC_SIDE" 4 "SIDE_CLASSIC" ;
VAL_ 192 VFC_Obj08A_HeadOrientation 0 "N/A" 1 "Head front" 2 "Head left front" 3 "Head left" 4 "Head left back" 5 "Head back" 6 "Head right back" 7 "Head right" 8 "Head right front" 15 "Unknown" ;
VAL_ 192 VFC_Obj08A_Type 0 "No type" 1 "Car" 2 "Truck" 3 "Motorcycle" 4 "Pedestrian" 5 "Cyclist" 6 "Animal" ;
VAL_ 193 VFC_Obj08B_LineEdgeRightEgo 0 "Right" 1 "Not Right" ;
VAL_ 193 VFC_Obj08B_LineEdgeLeftEgo 0 "Left" 1 "Not Left" ;
VAL_ 193 VFC_Obj08B_CompletelyInImg 0 "completely measured" 1 "not completely measured" ;
VAL_ 193 VFC_Obj08B_DirIndicator 0 "No direction indicator" 1 "Left indicator" 2 "Right indicator" 3 "Warning Lights" 4 "Unknown" ;
VAL_ 193 VFC_Obj08B_BrakeLight 0 "No light detected" 1 "One light detected" 2 "Two lights detected" 3 "Three lights detected" 4 "Unknown" ;
VAL_ 193 VFC_Obj08B_MeasSource 1 "MOD" 2 "PDET" 4 "OFT" 8 "OLS" 16 "Reserved" ;
VAL_ 193 VFC_Obj08B_Reliab 1 "Classifier Path" 2 "Flow Path" 4 "Disparity Path" 8 "Semantic Segmentation Path" 16 "Flow Stixel Path" 32 "Reserved" ;
